VERSION ""

NS_ :

BS_:

BU_: TCM iBooster HCU CIM SCM Right_Hand_Control Left_Hand_Control GPS VCM IC_2 XM GMRS Radio_CANtool Diagnostic_Tool_Digital_Wrench Information_System_Controller_1 STEERING_CONTROLLER VEHICLE_SECURITY RADIO_Hub ABS Battery_Management_Cntrl_2 Battery_Management_Cntrl_1 Auxiliary_Power_Unit_2 Auxiliary_Power_Unit_1 Electric_Propulsion_Cntrl_Unit_4 Electric_Propulsion_Cntrl_Unit_3 Electric_Propulsion_Cntrl_Unit_2 Electric_Propulsion_Cntrl_Unit_1 ECM IC

BO_ 3221225472 VECTOR__INDEPENDENT_SIG_MSG: 0 Vector__XXX
 SG_ pEPS_SAScalibrated : 0|2@1+ (1,0) [0|3] "" Vector__XXX
 SG_ pEPS_OpStatus : 0|3@1+ (1,0) [0|7] "" Vector__XXX
 SG_ pEPS_OpMode : 0|8@1+ (1,0) [0|255] "" Vector__XXX
 SG_ pEPS_ShaftVelocity : 0|16@1+ (0.1,-3276.5) [-3276.5|3276.5] "deg/s" Vector__XXX
 SG_ pEPS_ShaftPosition : 0|16@1+ (0.1,-3276.5) [-3276.5|3276.5] "deg" Vector__XXX
 SG_ DM_SPN2 : 0|8@1+ (1,0) [0|255] "" Vector__XXX
 SG_ DM_SPN3 : 0|3@1+ (1,0) [0|7] "" Vector__XXX
 SG_ DM_SPN1 : 0|8@1+ (1,0) [0|255] "" Vector__XXX
 SG_ DM_FailureModeIdentifier : 0|5@1+ (1,0) [0|0] "" Vector__XXX
 SG_ DM_SPNConversionMethod : 0|1@1+ (1,0) [0|1] "" Vector__XXX
 SG_ DM_OccurenceCount : 0|7@1+ (1,0) [0|126] "" Vector__XXX

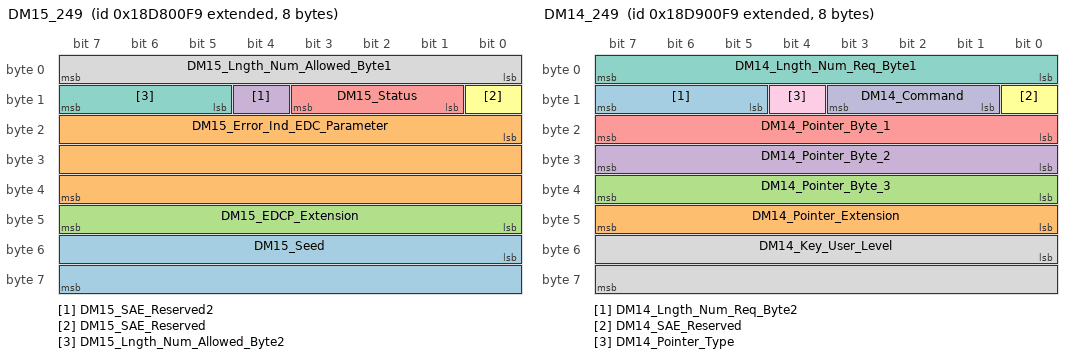
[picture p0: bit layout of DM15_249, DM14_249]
BO_ 2564292857 DM15_249: 8 Diagnostic_Tool_Digital_Wrench
 SG_ DM15_Seed : 48|16@1+ (1,0) [0|65535] "" Vector__XXX
 SG_ DM15_Error_Ind_EDC_Parameter : 16|24@1+ (1,0) [0|16777215] "" Vector__XXX
 SG_ DM15_EDCP_Extension : 40|8@1+ (1,0) [0|255] "" Vector__XXX
 SG_ DM15_SAE_Reserved2 : 12|1@1+ (1,0) [1|1] "" Vector__XXX
 SG_ DM15_Status : 9|3@1+ (1,0) [0|7] "" Vector__XXX
 SG_ DM15_SAE_Reserved : 8|1@1+ (1,0) [1|1] "" Vector__XXX
 SG_ DM15_Lngth_Num_Allowed_Byte2 : 13|3@1+ (1,0) [0|7] "" Vector__XXX
 SG_ DM15_Lngth_Num_Allowed_Byte1 : 0|8@1+ (1,0) [0|255] "" Vector__XXX

BO_ 2564358393 DM14_249: 8 Diagnostic_Tool_Digital_Wrench
 SG_ DM14_Lngth_Num_Req_Byte2 : 13|3@1+ (1,0) [0|7] "" Vector__XXX
 SG_ DM14_Pointer_Extension : 40|8@1+ (1,0) [0|255] "" Vector__XXX
 SG_ DM14_Pointer_Byte_3 : 32|8@1+ (1,0) [0|255] "" Vector__XXX
 SG_ DM14_Pointer_Byte_2 : 24|8@1+ (1,0) [0|255] "" Vector__XXX
 SG_ DM14_Pointer_Byte_1 : 16|8@1+ (1,0) [0|255] "" Vector__XXX
 SG_ DM14_SAE_Reserved : 8|1@1+ (1,0) [1|1] "" Vector__XXX
 SG_ DM14_Lngth_Num_Req_Byte1 : 0|8@1+ (1,0) [0|255] "" Vector__XXX
 SG_ DM14_Key_User_Level : 48|16@1+ (1,0) [0|65535] "" Vector__XXX
 SG_ DM14_Pointer_Type : 12|1@1+ (1,0) [0|1] "" Vector__XXX
 SG_ DM14_Command : 9|3@1+ (1,0) [0|7] "" Vector__XXX

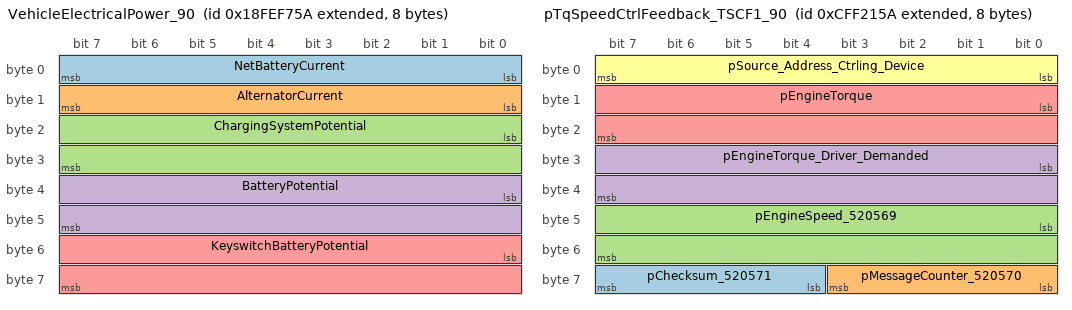
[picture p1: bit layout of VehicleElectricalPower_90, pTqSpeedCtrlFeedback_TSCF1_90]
BO_ 2566846298 VehicleElectricalPower_90: 8 HCU
 SG_ NetBatteryCurrent : 0|8@1+ (1,-125) [-125|125] "A" Vector__XXX
 SG_ AlternatorCurrent : 8|8@1+ (1,0) [0|250] "A" Vector__XXX
 SG_ ChargingSystemPotential : 16|16@1+ (0.05,0) [0|3212.75] "V" Vector__XXX
 SG_ BatteryPotential : 32|16@1+ (0.05,0) [0|3212.75] "V" Vector__XXX
 SG_ KeyswitchBatteryPotential : 48|16@1+ (0.05,0) [0|3212.75] "V" Vector__XXX

BO_ 2633984602 pDriveSystemStatus_90: 8 HCU
 SG_ pHeatedGripEnable : 48|2@1+ (1,0) [0|3] "" Vector__XXX
 SG_ pSideStandStatus : 36|2@1+ (1,0) [0|3] "" Vector__XXX
 SG_ pTetherSwitchStatus : 46|2@1+ (1,0) [0|3] "" Vector__XXX
 SG_ pLowFuelIndicatorStatus : 10|2@1+ (1,0) [0|3] "" Vector__XXX
 SG_ pOperatorNotInOperatingStation : 38|2@1+ (1,0) [0|3] "" Vector__XXX
 SG_ pParkBrakeIndicatorStatus : 40|3@1+ (1,0) [0|7] "" Vector__XXX
 SG_ pADCRequested : 34|2@1+ (1,0) [0|3] "" Vector__XXX
 SG_ pAWDModeRequested : 32|2@1+ (1,0) [0|3] "" Vector__XXX
 SG_ pRWDModeRequested : 30|2@1+ (1,0) [0|3] "" Vector__XXX
 SG_ pTurfModeRequested : 28|2@1+ (1,0) [0|3] "" Vector__XXX
 SG_ pADCStatus : 0|2@1+ (1,0) [0|3] "" Vector__XXX
 SG_ pTreadleNeutralStatus : 2|2@1+ (1,0) [0|3] "" Vector__XXX
 SG_ pTreadleReverseStatus : 4|2@1+ (1,0) [0|3] "" Vector__XXX
 SG_ pSecurityLightStatus : 6|2@1+ (1,0) [0|3] "" Vector__XXX
 SG_ pHighBeamIndicatorStatus : 8|2@1+ (1,0) [0|3] "" Vector__XXX
 SG_ pHeatedGripsPercentage : 16|8@1+ (0.4,0) [0|100] "%" Vector__XXX
 SG_ pCruiseControlSetStatus : 24|2@1+ (1,0) [0|3] "" Vector__XXX
 SG_ pSeatBeltIndicatorStatus : 12|3@1+ (1,0) [0|7] "" Vector__XXX

BO_ 2365530458 pTqSpeedCtrlFeedback_TSCF1_90: 8 HCU
 SG_ pChecksum_520571 : 60|4@1+ (1,0) [0|15] "" Vector__XXX
 SG_ pMessageCounter_520570 : 56|4@1+ (1,0) [0|15] "" Vector__XXX
 SG_ pEngineSpeed_520569 : 40|16@1+ (1,0) [0|64255] "rpm" Vector__XXX
 SG_ pEngineTorque_Driver_Demanded : 24|16@1- (0.03125,0) [-400|1607.96875] "Nm" Vector__XXX
 SG_ pEngineTorque : 8|16@1- (0.03125,0) [-400|1607.96875] "Nm" Vector__XXX
 SG_ pSource_Address_Ctrling_Device : 0|8@1+ (1,0) [0|255] "Source Address" Vector__XXX

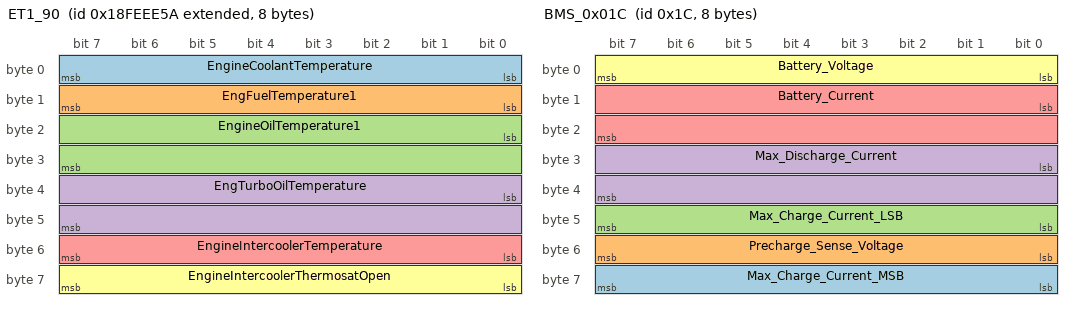
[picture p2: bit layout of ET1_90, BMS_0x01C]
BO_ 2566843994 ET1_90: 8 HCU
 SG_ EngineCoolantTemperature : 0|8@1+ (1,-40) [-40|210] "°C" Vector__XXX
 SG_ EngFuelTemperature1 : 8|8@1+ (1,-40) [-40|210] "°C" Vector__XXX
 SG_ EngineOilTemperature1 : 16|16@1+ (0.03125,-273) [-273|1734.96875] "°C" Vector__XXX
 SG_ EngTurboOilTemperature : 32|16@1+ (0.03125,-273) [-273|1734.96875] "°C" Vector__XXX
 SG_ EngineIntercoolerTemperature : 48|8@1+ (1,-40) [-40|210] "°C" Vector__XXX
 SG_ EngineIntercoolerThermosatOpen : 56|8@1+ (0.4,0) [0|100] "%" Vector__XXX

BO_ 2566841690 EngineHoursRevolutions_90: 8 HCU
 SG_ EngTotalHoursOfOper : 0|32@1+ (0.05,0) [0|210554060.75] "h" Vector__XXX
 SG_ TotalEngineRevolutions : 32|32@1+ (1000,0) [0|4211081215000] "r" Vector__XXX

BO_ 2566876762 pVF1_90: 8 HCU
 SG_ pEngineOilPressureStatus : 4|2@1+ (1,0) [0|3] "" Vector__XXX
 SG_ pHydraulicOilPressureStatus : 2|2@1+ (1,0) [0|3] "" Vector__XXX
 SG_ pHydraulicOilTempStatus : 0|2@1+ (1,0) [0|3] "" Vector__XXX

BO_ 2566876672 pVF1_00: 8 ECM
 SG_ pEngineOilPressureStatus : 4|2@1+ (1,0) [0|3] "" Vector__XXX
 SG_ pHydraulicOilPressureStatus : 2|2@1+ (1,0) [0|3] "" Vector__XXX
 SG_ pHydraulicOilTempStatus : 0|2@1+ (1,0) [0|3] "" Vector__XXX

BO_ 27 BMS_0x01B: 8 Battery_Management_Cntrl_1
 SG_ Battery_Relative_SOC : 0|8@1+ (1,0) [0|0] "%" Vector__XXX
 SG_ BMS_Mode : 8|2@1+ (1,0) [0|0] "1" Vector__XXX

BO_ 28 BMS_0x01C: 8 Battery_Management_Cntrl_1
 SG_ Max_Charge_Current_MSB : 56|8@1+ (1,0) [0|0] "A" Vector__XXX
 SG_ Precharge_Sense_Voltage : 48|8@1+ (1,0) [0|0] "V" Vector__XXX
 SG_ Max_Charge_Current_LSB : 40|8@1+ (1,0) [0|0] "A" Vector__XXX
 SG_ Max_Discharge_Current : 24|16@1+ (1,0) [0|0] "A" Vector__XXX
 SG_ Battery_Current : 8|16@1+ (1,-32768) [0|0] "A" Vector__XXX
 SG_ Battery_Voltage : 0|8@1+ (1,0) [0|0] "V" Vector__XXX

BO_ 2365553933 pRemoteBrakeControl1_13: 8 iBooster
 SG_ Checksum : 56|8@1+ (1,0) [0|255] "Count" Vector__XXX
 SG_ MessageCounter : 52|4@1- (1,0) [-8|7] "Count" Vector__XXX
 SG_ pActualBrakingApplication : 8|8@1+ (0.4,0) [0|100] "%" Vector__XXX
 SG_ pRequestedBrakingApplication : 0|8@1+ (0.4,0) [0|100] "%" Vector__XXX

BO_ 2348941059 TC1_03: 8 TCM
 SG_ TrsmRequestedGear_525 : 16|8@1+ (1,0) [0|0] "" Vector__XXX
 SG_ TrsmGearShiftInhibitReq_681 : 0|2@1+ (1,0) [0|0] "" Vector__XXX

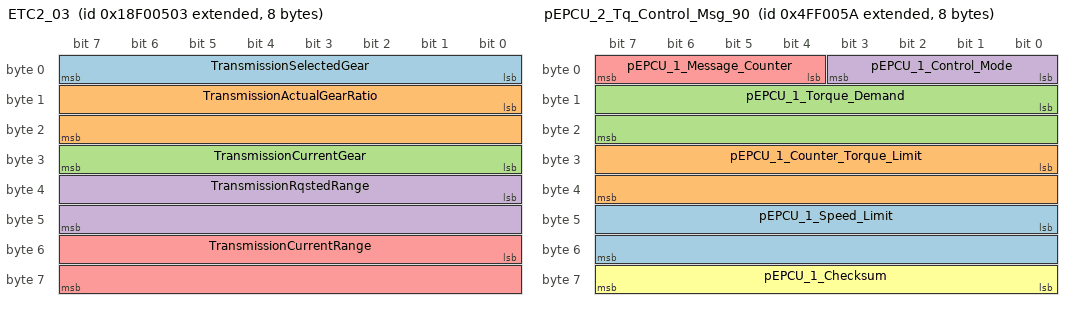
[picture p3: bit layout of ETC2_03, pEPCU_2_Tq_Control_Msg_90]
BO_ 2565866755 ETC2_03: 8 TCM
 SG_ TransmissionSelectedGear : 0|8@1+ (1,-125) [-125|125] "" Vector__XXX
 SG_ TransmissionActualGearRatio : 8|16@1+ (0.001,0) [0|64.255] "" Vector__XXX
 SG_ TransmissionCurrentGear : 24|8@1+ (1,-125) [-125|125] "" Vector__XXX
 SG_ TransmissionRqstedRange : 32|16@1+ (1,0) [0|65535] "" Vector__XXX
 SG_ TransmissionCurrentRange : 48|16@1+ (1,0) [0|65535] "" Vector__XXX

BO_ 2364539395 ElectronicTrsmController1_03: 8 TCM
 SG_ TrsmShiftInProcess_574 : 4|2@1+ (1,0) [0|0] "" Vector__XXX

BO_ 2566844675 CruiseControlVehSpeed_3: 8 TCM
 SG_ pCruiseCntrlCounter : 50|4@1+ (1,0) [0|15] "" Vector__XXX
 SG_ TwoSpeedAxleSwitch : 0|2@1+ (1,0) [0|3] "" Vector__XXX
 SG_ ParkingBrakeSwitch : 2|2@1+ (1,0) [0|3] "" Vector__XXX
 SG_ Wheel_BasedVehicleSpeed : 8|16@1+ (0.00390625,0) [0|251] "km/h" Vector__XXX
 SG_ CruiseCtrlActive : 24|2@1+ (1,0) [0|3] "" Vector__XXX
 SG_ CruiseCtrlEnableSwitch : 26|2@1+ (1,0) [0|3] "" Vector__XXX
 SG_ BrakeSwitch : 28|2@1+ (1,0) [0|3] "" Vector__XXX
 SG_ ClutchSwitch : 30|2@1+ (1,0) [0|3] "" Vector__XXX
 SG_ CruiseCtrlSetSwitch : 32|2@1+ (1,0) [0|3] "" Vector__XXX
 SG_ CruiseCtrlCoastSwitch : 34|2@1+ (1,0) [0|3] "" Vector__XXX
 SG_ CruiseCtrlResumeSwitch : 36|2@1+ (1,0) [0|3] "" Vector__XXX
 SG_ CruiseCtrlAccelerateSwitch : 38|2@1+ (1,0) [0|3] "" Vector__XXX
 SG_ CruiseCtrlSetSpeed : 40|8@1+ (1,0) [0|250] "km/h" Vector__XXX
 SG_ pOdometerDriveBit : 6|2@1+ (1,0) [0|3] "" Vector__XXX
 SG_ CruiseCtrlPauseSw : 4|2@1+ (1,0) [0|3] "" Vector__XXX
 SG_ pCCChecksum : 56|8@1+ (1,0) [0|255] "" Vector__XXX
 SG_ pCruiseEnableStatus : 48|4@1+ (1,0) [0|15] "" Vector__XXX

BO_ 2566841344 SHUTDN_00: 8 ECM
 SG_ Engine_Wait_to_Start_Lamp_1081 : 24|2@1+ (1,0) [0|0] "" Vector__XXX

BO_ 2231304282 pEPCU_2_Tq_Control_Msg_90: 8 HCU
 SG_ pEPCU_1_Speed_Limit : 40|16@1+ (1,-32768) [-32768|31488] "rpm" Vector__XXX
 SG_ pEPCU_1_Counter_Torque_Limit : 24|16@1+ (0.1,-3276.8) [-3276.8|3276.7] "Nm" Vector__XXX
 SG_ pEPCU_1_Torque_Demand : 8|16@1+ (0.1,-3276.8) [-3276.8|3276.7] "Nm" Vector__XXX
 SG_ pEPCU_1_Control_Mode : 0|4@1+ (1,0) [0|15] "" Vector__XXX
 SG_ pEPCU_1_Message_Counter : 4|4@1+ (1,0) [0|15] "" Vector__XXX
 SG_ pEPCU_1_Checksum : 56|8@1+ (1,0) [0|255] "" Vector__XXX

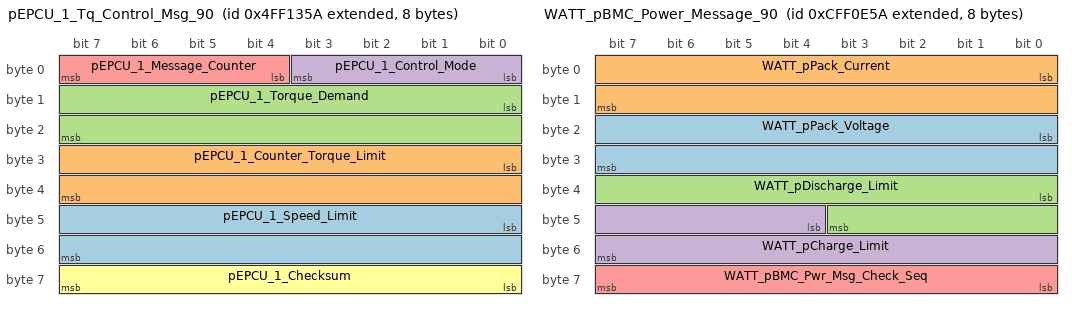
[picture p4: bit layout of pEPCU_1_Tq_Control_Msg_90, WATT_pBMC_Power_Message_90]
BO_ 2231309146 pEPCU_1_Tq_Control_Msg_90: 8 HCU
 SG_ pEPCU_1_Speed_Limit : 40|16@1+ (1,-32768) [-32768|31488] "rpm" Vector__XXX
 SG_ pEPCU_1_Counter_Torque_Limit : 24|16@1+ (0.1,-3276.8) [-3276.8|3276.7] "Nm" Vector__XXX
 SG_ pEPCU_1_Torque_Demand : 8|16@1+ (0.1,-3276.8) [-3276.8|3276.7] "Nm" Vector__XXX
 SG_ pEPCU_1_Control_Mode : 0|4@1+ (1,0) [0|15] "" Vector__XXX
 SG_ pEPCU_1_Message_Counter : 4|4@1+ (1,0) [0|15] "" Vector__XXX
 SG_ pEPCU_1_Checksum : 56|8@1+ (1,0) [0|255] "" Vector__XXX

BO_ 2365525594 WATT_pBMC_Power_Message_90: 8 HCU
 SG_ WATT_pPack_Voltage : 16|16@1+ (0.05,0) [0|3212.75] "V" Vector__XXX
 SG_ WATT_pPack_Current : 0|16@1+ (0.05,-1600) [-1600|1612.75] "A" Vector__XXX
 SG_ WATT_pDischarge_Limit : 32|12@1+ (0.5,0) [0|2007.5] "A" Vector__XXX
 SG_ WATT_pCharge_Limit : 44|12@1+ (0.5,0) [0|2007.5] "A" Vector__XXX
 SG_ WATT_pBMC_Pwr_Msg_Check_Seq : 56|8@1+ (1,0) [0|255] "" Vector__XXX

BO_ 2348941146 TC1_90: 8 HCU
 SG_ TrsmRequestedGear_525 : 16|8@1+ (1,0) [0|0] "" Vector__XXX
 SG_ TrsmGearShiftInhibitReq_681 : 0|2@1+ (1,0) [0|0] "" Vector__XXX

BO_ 2566841434 SHUTDN_90: 8 HCU
 SG_ Engine_Wait_to_Start_Lamp_1081 : 24|2@1+ (1,0) [0|0] "" Vector__XXX

BO_ 2566885722 RF3_RemoteFeedback3_90: 8 HCU
 SG_ pHybridPowertrainMode : 0|4@1+ (1,0) [0|0] "" Vector__XXX

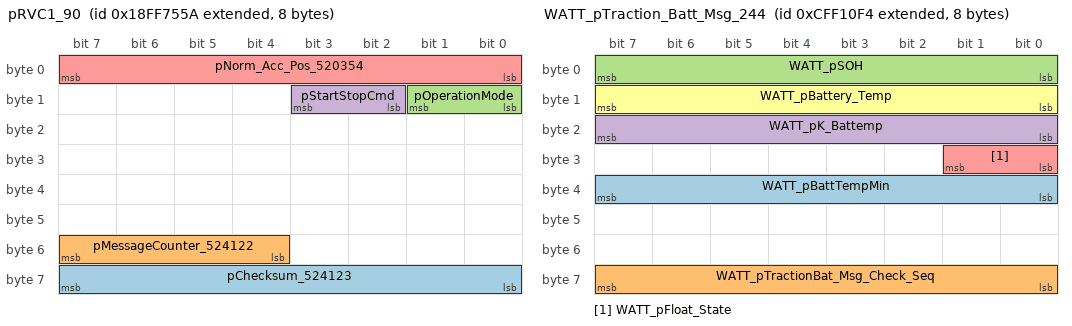
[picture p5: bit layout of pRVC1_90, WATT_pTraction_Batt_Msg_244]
BO_ 2566878554 pRVC1_90: 8 HCU
 SG_ pChecksum_524123 : 56|8@1+ (1,0) [0|255] "" Vector__XXX
 SG_ pMessageCounter_524122 : 52|4@1+ (1,0) [0|15] "" Vector__XXX
 SG_ pOperationMode : 8|2@1+ (1,0) [0|0] "" Vector__XXX
 SG_ pStartStopCmd : 10|2@1+ (1,0) [0|3] "" Vector__XXX
 SG_ pNorm_Acc_Pos_520354 : 0|8@1+ (0.4,0) [0|102] "Percent" Vector__XXX

BO_ 2566844762 CruiseControlVehSpeed_90: 8 HCU
 SG_ TwoSpeedAxleSwitch : 0|2@1+ (1,0) [0|3] "" Vector__XXX
 SG_ ParkingBrakeSwitch : 2|2@1+ (1,0) [0|3] "" Vector__XXX
 SG_ Wheel_BasedVehicleSpeed : 8|16@1+ (0.00390625,0) [0|251] "km/h" Vector__XXX
 SG_ CruiseCtrlActive : 24|2@1+ (1,0) [0|3] "" Vector__XXX
 SG_ CruiseCtrlEnableSwitch : 26|2@1+ (1,0) [0|3] "" Vector__XXX
 SG_ BrakeSwitch : 28|2@1+ (1,0) [0|3] "" Vector__XXX
 SG_ ClutchSwitch : 30|2@1+ (1,0) [0|3] "" Vector__XXX
 SG_ CruiseCtrlSetSwitch : 32|2@1+ (1,0) [0|3] "" Vector__XXX
 SG_ CruiseCtrlCoastSwitch : 34|2@1+ (1,0) [0|3] "" Vector__XXX
 SG_ CruiseCtrlResumeSwitch : 36|2@1+ (1,0) [0|3] "" Vector__XXX
 SG_ CruiseCtrlAccelerateSwitch : 38|2@1+ (1,0) [0|3] "" Vector__XXX
 SG_ CruiseCtrlSetSpeed : 40|8@1+ (1,0) [0|250] "km/h" Vector__XXX
 SG_ pOdometerDriveBit : 6|2@1+ (1,0) [0|3] "" Vector__XXX
 SG_ CruiseCtrlPauseSw : 4|2@1+ (1,0) [0|3] "" Vector__XXX
 SG_ pCCMessageCounter : 52|4@1+ (1,0) [0|15] "" Vector__XXX
 SG_ pCCChecksum : 56|8@1+ (1,0) [0|255] "" Vector__XXX
 SG_ pCruiseEnableStatus : 48|4@1+ (1,0) [0|15] "" Vector__XXX

BO_ 2566887489 pVehicleLoadInfo1_65: 6 Information_System_Controller_1
 SG_ pRiderWeightRearLeft : 32|8@1+ (1,0) [0|250] "kg" Vector__XXX
 SG_ pBoxLoadWeight : 48|8@1+ (10,0) [0|2400] "kg" Vector__XXX
 SG_ pRiderWeightRearRight : 40|8@1+ (1,0) [0|250] "kg" Vector__XXX
 SG_ pRiderWeightMidRight : 24|8@1+ (1,0) [0|250] "kg" Vector__XXX
 SG_ pRiderWeightMidLeft : 16|8@1+ (1,0) [0|250] "kg" Vector__XXX
 SG_ pRiderWeightFrontRight : 8|8@1+ (1,0) [0|250] "kg" Vector__XXX
 SG_ pRiderWeightFrontLeft : 0|8@1+ (1,0) [0|250] "kg" Vector__XXX

BO_ 2566853722 pWattMessage_90: 8 HCU
 SG_ pRangeToEmptyEV : 16|16@1+ (0.1,0) [0|6425.5] "km" Vector__XXX
 SG_ pEfficiencyEV : 0|16@1+ (0.1,0) [0|6425.5] "Wh/km" Vector__XXX

BO_ 2365554060 pRemoteBrakeControl1_140: 8 CIM
 SG_ Checksum : 56|8@1+ (1,0) [0|255] "Count" Vector__XXX
 SG_ MessageCounter : 52|4@1- (1,0) [-8|7] "Count" Vector__XXX
 SG_ pActualBrakingApplication : 8|8@1+ (0.4,0) [0|100] "%" Vector__XXX
 SG_ pRequestedBrakingApplication : 0|8@1+ (0.4,0) [0|100] "%" Vector__XXX

BO_ 2566877965 pRemoteSteeringControl1_13: 8 iBooster
 SG_ pEPS_CommandedVar2 : 48|16@1+ (0.1,-3276.5) [-3276.5|3276.5] "deg/s" Vector__XXX
 SG_ pEPS_CommandedVar1 : 32|16@1+ (0.1,-3276.5) [-3276.5|3276.5] "deg" Vector__XXX
 SG_ pEPS_OpModeCommanded : 0|8@1+ (1,0) [0|255] "" Vector__XXX

BO_ 2365526260 WATT_pTraction_Batt_Msg_244: 8 Battery_Management_Cntrl_2
 SG_ WATT_pBattTempMin : 32|8@1+ (1,-40) [-40|200] "deg C" Vector__XXX
 SG_ WATT_pTractionBat_Msg_Check_Seq : 56|8@1+ (1,0) [0|255] "" Vector__XXX
 SG_ WATT_pSOH : 0|8@1+ (0.5,0) [0|100] "%" Vector__XXX
 SG_ WATT_pK_Battemp : 16|8@1+ (0.5,0) [0|100] "%" Vector__XXX
 SG_ WATT_pFloat_State : 24|2@1+ (1,0) [0|3] "" Vector__XXX
 SG_ WATT_pBattery_Temp : 8|8@1+ (1,-40) [-40|200] "C" Vector__XXX

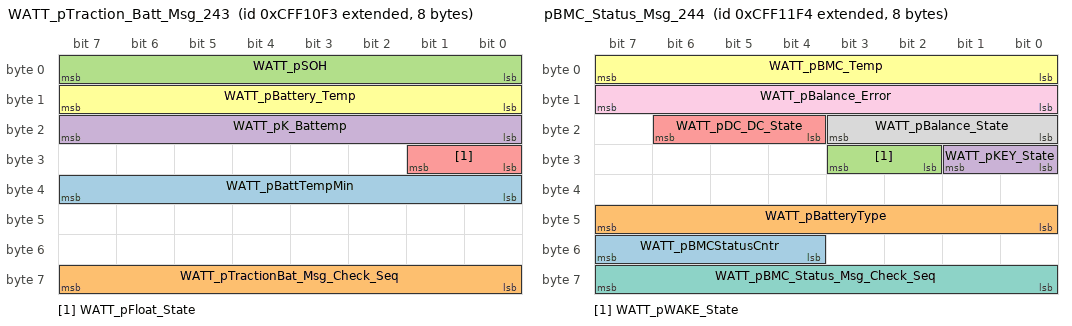
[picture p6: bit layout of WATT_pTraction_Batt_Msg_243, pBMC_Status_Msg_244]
BO_ 2365526259 WATT_pTraction_Batt_Msg_243: 8 Battery_Management_Cntrl_1
 SG_ WATT_pBattTempMin : 32|8@1+ (1,-40) [-40|200] "deg C" Vector__XXX
 SG_ WATT_pTractionBat_Msg_Check_Seq : 56|8@1+ (1,0) [0|255] "" Vector__XXX
 SG_ WATT_pSOH : 0|8@1+ (0.5,0) [0|100] "%" Vector__XXX
 SG_ WATT_pK_Battemp : 16|8@1+ (0.5,0) [0|100] "%" Vector__XXX
 SG_ WATT_pFloat_State : 24|2@1+ (1,0) [0|3] "" Vector__XXX
 SG_ WATT_pBattery_Temp : 8|8@1+ (1,-40) [-40|200] "C" Vector__XXX

BO_ 2365526516 pBMC_Status_Msg_244: 8 Battery_Management_Cntrl_2
 SG_ WATT_pBMCStatusCntr : 52|4@1+ (1,0) [0|15] "" Vector__XXX
 SG_ WATT_pBatteryType : 40|8@1+ (1,0) [0|255] "" Vector__XXX
 SG_ WATT_pWAKE_State : 26|2@1+ (1,0) [0|3] "" Vector__XXX
 SG_ WATT_pKEY_State : 24|2@1+ (1,0) [0|3] "" Vector__XXX
 SG_ WATT_pDC_DC_State : 20|3@1+ (1,0) [0|7] "" Vector__XXX
 SG_ WATT_pBMC_Temp : 0|8@1+ (1,-40) [-40|200] "C" Vector__XXX
 SG_ WATT_pBMC_Status_Msg_Check_Seq : 56|8@1+ (1,0) [0|255] "" Vector__XXX
 SG_ WATT_pBalance_State : 16|4@1+ (1,0) [0|15] "" Vector__XXX
 SG_ WATT_pBalance_Error : 8|8@1+ (0.5,-6.4) [-6.4|6.1] "%" Vector__XXX

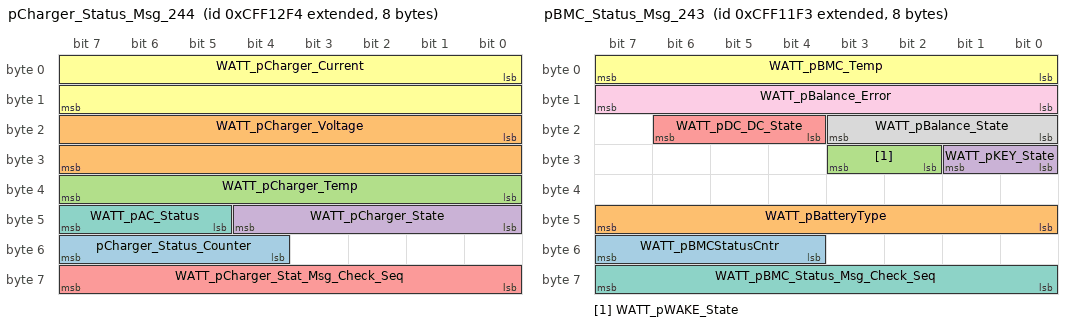
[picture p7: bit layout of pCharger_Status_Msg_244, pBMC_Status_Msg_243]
BO_ 2365526772 pCharger_Status_Msg_244: 8 Battery_Management_Cntrl_2
 SG_ pCharger_Status_Counter : 52|4@1+ (1,0) [0|15] "" Vector__XXX
 SG_ WATT_pCharger_Voltage : 16|16@1+ (0.05,0) [0|3212.75] "V" Vector__XXX
 SG_ WATT_pCharger_Temp : 32|8@1+ (1,-40) [-40|200] "C" Vector__XXX
 SG_ WATT_pCharger_State : 40|5@1+ (1,0) [0|31] "" Vector__XXX
 SG_ WATT_pCharger_Stat_Msg_Check_Seq : 56|8@1+ (1,0) [0|255] "" Vector__XXX
 SG_ WATT_pCharger_Current : 0|16@1+ (0.05,-1600) [-1600|1612.75] "A" Vector__XXX
 SG_ WATT_pAC_Status : 45|3@1+ (1,0) [0|7] "" Vector__XXX

BO_ 2365526004 pEnergy_Msg_244: 8 Battery_Management_Cntrl_2
 SG_ WATT_pWh_In_Since_Key : 24|32@1+ (6.10352E-005,-131072) [-131072|126000] "Wh" Vector__XXX
 SG_ WATT_pSOC : 0|8@1+ (0.5,0) [0|100] "%" Vector__XXX
 SG_ WATT_pEnergy_Msg_Check_Seq : 56|8@1+ (1,0) [0|255] "" Vector__XXX
 SG_ WATT_pAvailable_Wh : 8|16@1+ (4,0) [0|257020] "Wh" Vector__XXX

BO_ 2365526515 pBMC_Status_Msg_243: 8 Battery_Management_Cntrl_1
 SG_ WATT_pBMCStatusCntr : 52|4@1+ (1,0) [0|15] "" Vector__XXX
 SG_ WATT_pBatteryType : 40|8@1+ (1,0) [0|255] "" Vector__XXX
 SG_ WATT_pWAKE_State : 26|2@1+ (1,0) [0|3] "" Vector__XXX
 SG_ WATT_pKEY_State : 24|2@1+ (1,0) [0|3] "" Vector__XXX
 SG_ WATT_pDC_DC_State : 20|3@1+ (1,0) [0|7] "" Vector__XXX
 SG_ WATT_pBMC_Temp : 0|8@1+ (1,-40) [-40|200] "C" Vector__XXX
 SG_ WATT_pBMC_Status_Msg_Check_Seq : 56|8@1+ (1,0) [0|255] "" Vector__XXX
 SG_ WATT_pBalance_State : 16|4@1+ (1,0) [0|15] "" Vector__XXX
 SG_ WATT_pBalance_Error : 8|8@1+ (0.5,-6.4) [-6.4|6.1] "%" Vector__XXX

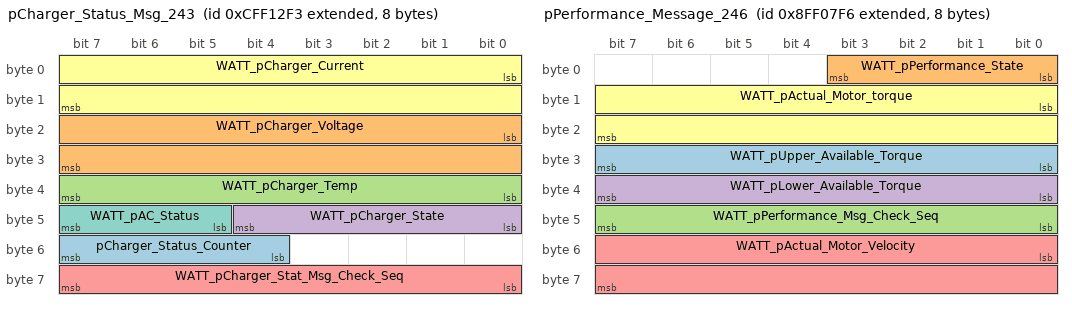
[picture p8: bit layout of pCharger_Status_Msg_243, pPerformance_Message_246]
BO_ 2365526771 pCharger_Status_Msg_243: 8 Battery_Management_Cntrl_1
 SG_ pCharger_Status_Counter : 52|4@1+ (1,0) [0|15] "" Vector__XXX
 SG_ WATT_pCharger_Voltage : 16|16@1+ (0.05,0) [0|3212.75] "V" Vector__XXX
 SG_ WATT_pCharger_Temp : 32|8@1+ (1,-40) [-40|200] "C" Vector__XXX
 SG_ WATT_pCharger_State : 40|5@1+ (1,0) [0|31] "" Vector__XXX
 SG_ WATT_pCharger_Stat_Msg_Check_Seq : 56|8@1+ (1,0) [0|255] "" Vector__XXX
 SG_ WATT_pCharger_Current : 0|16@1+ (0.05,-1600) [-1600|1612.75] "A" Vector__XXX
 SG_ WATT_pAC_Status : 45|3@1+ (1,0) [0|7] "" Vector__XXX

BO_ 2365526003 pEnergy_Msg_243: 8 Battery_Management_Cntrl_1
 SG_ WATT_pWh_In_Since_Key : 24|32@1+ (6.10352E-005,-131072) [-131072|126000] "Wh" Vector__XXX
 SG_ WATT_pSOC : 0|8@1+ (0.5,0) [0|100] "%" Vector__XXX
 SG_ WATT_pEnergy_Msg_Check_Seq : 56|8@1+ (1,0) [0|255] "" Vector__XXX
 SG_ WATT_pAvailable_Wh : 8|16@1+ (4,0) [0|257020] "Wh" Vector__XXX

BO_ 2298415094 pPerformance_Message_246: 8 Auxiliary_Power_Unit_2
 SG_ WATT_pUpper_Available_Torque : 24|8@1+ (2.5,-312.5) [-312.5|312.5] "Nm" Vector__XXX
 SG_ WATT_pPerformance_State : 0|4@1+ (1,0) [0|15] "" Vector__XXX
 SG_ WATT_pPerformance_Msg_Check_Seq : 40|8@1+ (1,0) [0|255] "" Vector__XXX
 SG_ WATT_pLower_Available_Torque : 32|8@1+ (2.5,-312.5) [-312.5|312.5] "Nm" Vector__XXX
 SG_ WATT_pActual_Motor_Velocity : 48|16@1+ (1,-32768) [-32768|31488] "RPM" Vector__XXX
 SG_ WATT_pActual_Motor_torque : 8|16@1+ (0.1,-3276.8) [-3276.8|3148.7] "Nm" Vector__XXX

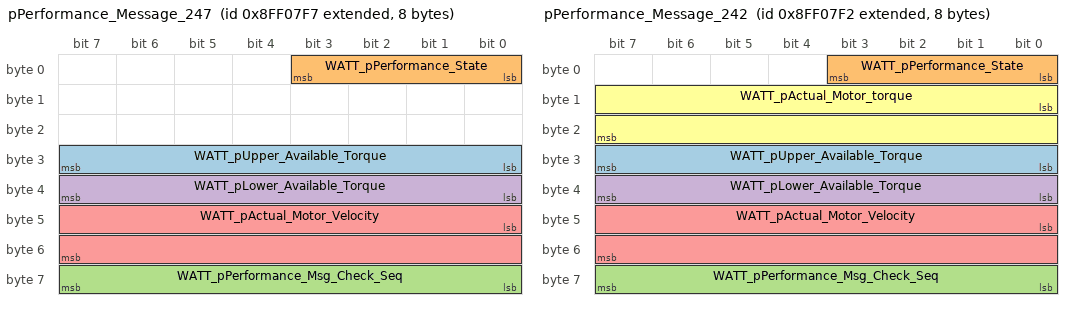
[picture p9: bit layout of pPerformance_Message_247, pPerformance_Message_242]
BO_ 2298415095 pPerformance_Message_247: 8 Auxiliary_Power_Unit_1
 SG_ WATT_pUpper_Available_Torque : 24|8@1+ (2.5,-312.5) [-312.5|312.5] "Nm" Vector__XXX
 SG_ WATT_pPerformance_State : 0|4@1+ (1,0) [0|15] "" Vector__XXX
 SG_ WATT_pPerformance_Msg_Check_Seq : 56|8@1+ (1,0) [0|255] "" Vector__XXX
 SG_ WATT_pLower_Available_Torque : 32|8@1+ (2.5,-312.5) [-312.5|312.5] "Nm" Vector__XXX
 SG_ WATT_pActual_Motor_Velocity : 40|16@1+ (1,-32768) [-32768|31488] "RPM" Vector__XXX

BO_ 2298415090 pPerformance_Message_242: 8 Electric_Propulsion_Cntrl_Unit_4
 SG_ WATT_pUpper_Available_Torque : 24|8@1+ (2.5,-312.5) [-312.5|312.5] "Nm" Vector__XXX
 SG_ WATT_pPerformance_State : 0|4@1+ (1,0) [0|15] "" Vector__XXX
 SG_ WATT_pPerformance_Msg_Check_Seq : 56|8@1+ (1,0) [0|255] "" Vector__XXX
 SG_ WATT_pLower_Available_Torque : 32|8@1+ (2.5,-312.5) [-312.5|312.5] "Nm" Vector__XXX
 SG_ WATT_pActual_Motor_Velocity : 40|16@1+ (1,-32768) [-32768|31488] "RPM" Vector__XXX
 SG_ WATT_pActual_Motor_torque : 8|16@1+ (0.1,-3276.8) [-3276.8|3148.7] "Nm" Vector__XXX

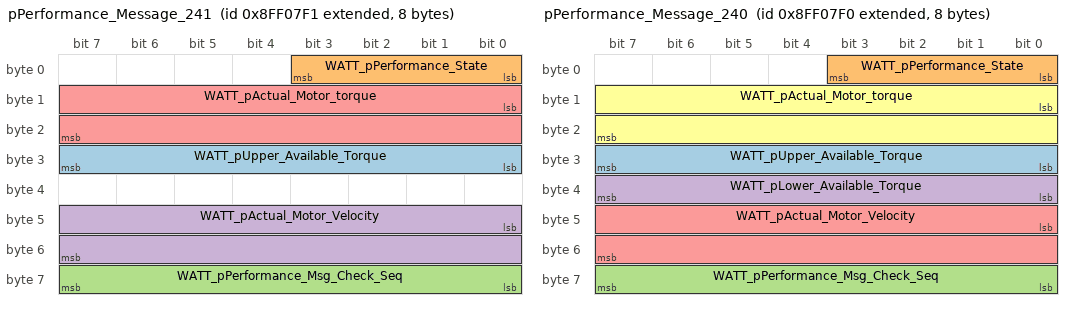
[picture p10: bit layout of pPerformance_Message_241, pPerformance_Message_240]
BO_ 2298415089 pPerformance_Message_241: 8 Electric_Propulsion_Cntrl_Unit_3
 SG_ WATT_pUpper_Available_Torque : 24|8@1+ (2.5,-312.5) [-312.5|312.5] "Nm" Vector__XXX
 SG_ WATT_pPerformance_State : 0|4@1+ (1,0) [0|15] "" Vector__XXX
 SG_ WATT_pPerformance_Msg_Check_Seq : 56|8@1+ (1,0) [0|255] "" Vector__XXX
 SG_ WATT_pActual_Motor_Velocity : 40|16@1+ (1,-32768) [-32768|31488] "RPM" Vector__XXX
 SG_ WATT_pActual_Motor_torque : 8|16@1+ (0.1,-3276.8) [-3276.8|3148.7] "Nm" Vector__XXX

BO_ 2298415088 pPerformance_Message_240: 8 Electric_Propulsion_Cntrl_Unit_2
 SG_ WATT_pUpper_Available_Torque : 24|8@1+ (2.5,-312.5) [-312.5|312.5] "Nm" Vector__XXX
 SG_ WATT_pPerformance_State : 0|4@1+ (1,0) [0|15] "" Vector__XXX
 SG_ WATT_pPerformance_Msg_Check_Seq : 56|8@1+ (1,0) [0|255] "" Vector__XXX
 SG_ WATT_pLower_Available_Torque : 32|8@1+ (2.5,-312.5) [-312.5|312.5] "Nm" Vector__XXX
 SG_ WATT_pActual_Motor_Velocity : 40|16@1+ (1,-32768) [-32768|31488] "RPM" Vector__XXX
 SG_ WATT_pActual_Motor_torque : 8|16@1+ (0.1,-3276.8) [-3276.8|3148.7] "Nm" Vector__XXX

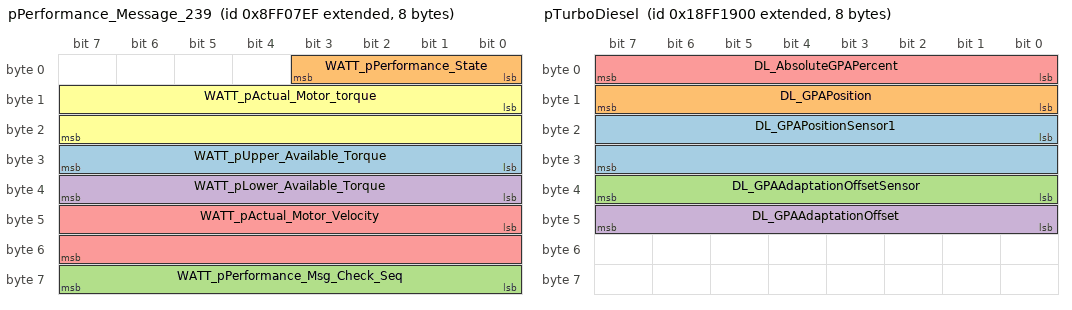
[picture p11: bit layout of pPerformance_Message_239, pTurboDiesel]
BO_ 2298415087 pPerformance_Message_239: 8 Electric_Propulsion_Cntrl_Unit_1
 SG_ WATT_pUpper_Available_Torque : 24|8@1+ (2.5,-312.5) [-312.5|312.5] "Nm" Vector__XXX
 SG_ WATT_pPerformance_State : 0|4@1+ (1,0) [0|15] "" Vector__XXX
 SG_ WATT_pPerformance_Msg_Check_Seq : 56|8@1+ (1,0) [0|255] "" Vector__XXX
 SG_ WATT_pLower_Available_Torque : 32|8@1+ (2.5,-312.5) [-312.5|312.5] "Nm" Vector__XXX
 SG_ WATT_pActual_Motor_Velocity : 40|16@1+ (1,-32768) [-32768|31488] "RPM" Vector__XXX
 SG_ WATT_pActual_Motor_torque : 8|16@1+ (0.1,-3276.8) [-3276.8|3148.7] "Nm" Vector__XXX

BO_ 2566834735 DM1_47: 22 SCM
 SG_ DM_FlashRedStopLamp : 12|2@1+ (1,0) [0|3] "" Vector__XXX
 SG_ DM_FlashProtectLamp : 8|2@1+ (1,0) [0|3] "" Vector__XXX
 SG_ DM_FlashMalfuncIndicatorLamp : 14|2@1+ (1,0) [0|3] "" Vector__XXX
 SG_ DM_FlashAmberWarningLamp : 10|2@1+ (1,0) [0|3] "" Vector__XXX
 SG_ DTC5 : 144|32@1+ (1,0) [0|4294967295] "" Vector__XXX
 SG_ DTC4 : 112|32@1+ (1,0) [0|4294967295] "" Vector__XXX
 SG_ DTC3 : 80|32@1+ (1,0) [0|4294967295] "" Vector__XXX
 SG_ DTC2 : 48|32@1+ (1,0) [0|4294967295] "" Vector__XXX
 SG_ DTC1 : 16|32@1+ (1,0) [0|4294967295] "" Vector__XXX
 SG_ DM_ProtectLampStatus : 0|2@1+ (1,0) [0|3] "" Vector__XXX
 SG_ DM_RedStopLampState : 4|2@1+ (1,0) [0|3] "" Vector__XXX
 SG_ DM_AmberWrningLmpStatus : 2|2@1+ (1,0) [0|3] "" Vector__XXX
 SG_ DM_MalfuncnIndicatorLampStatus : 6|2@1+ (1,0) [0|3] "" Vector__XXX

BO_ 2566903040 DL_DiscreteIO_0: 8 ECM
 SG_ DL_BoostBypassOutputActive : 54|1@1+ (1,0) [0|1] "" Vector__XXX
 SG_ DL_CruiseLampOutputActive : 53|1@1+ (1,0) [0|1] "" Vector__XXX
 SG_ DL_FuelSelectOutput2Active : 52|1@1+ (1,0) [0|1] "" Vector__XXX
 SG_ DL_FuelSelectOutput1Active : 51|1@1+ (1,0) [0|1] "" Vector__XXX
 SG_ DL_OemOutput4Active : 50|1@1+ (1,0) [0|1] "" Vector__XXX
 SG_ DL_OemOutput3Active : 49|1@1+ (1,0) [0|1] "" Vector__XXX
 SG_ DL_OemOutput2Active : 48|1@1+ (1,0) [0|1] "" Vector__XXX
 SG_ DL_OemOutput1Active : 47|1@1+ (1,0) [0|1] "" Vector__XXX
 SG_ DL_FuelPump2RelayOutputActive : 46|1@1+ (1,0) [0|1] "" Vector__XXX
 SG_ DL_IntercoolerOutputActive : 45|1@1+ (1,0) [0|1] "" Vector__XXX
 SG_ DL_ClutchSwitchInputActive : 18|1@1+ (1,0) [0|1] "" Vector__XXX
 SG_ DL_BrakeSwitchInputActive : 17|1@1+ (1,0) [0|1] "" Vector__XXX
 SG_ DL_ReverseSwitchInputActive : 16|1@1+ (1,0) [0|1] "" Vector__XXX
 SG_ DL_CrankReqInput : 0|1@1+ (1,0) [0|1] "" Vector__XXX
 SG_ DL_LowOilLevelInput : 1|1@1+ (1,0) [0|1] "" Vector__XXX
 SG_ DL_LoadAnticipate1Input : 2|1@1+ (1,0) [0|1] "" Vector__XXX
 SG_ DL_LoadAnticipate2Input : 3|1@1+ (1,0) [0|1] "" Vector__XXX
 SG_ DL_CruiseDecelInputActive : 10|1@1+ (1,0) [0|1] "" Vector__XXX
 SG_ DL_CruiseAccelInputActive : 11|1@1+ (1,0) [0|1] "" Vector__XXX
 SG_ DL_PowertrainRelayOutput : 32|1@1+ (1,0) [0|1] "" Vector__XXX
 SG_ DL_StarterRelayOutput : 33|1@1+ (1,0) [0|1] "" Vector__XXX
 SG_ DL_FuelPump1RelayOutput : 44|1@1+ (1,0) [0|1] "" Vector__XXX
 SG_ DL_SlowmodeInputActive : 5|1@1+ (1,0) [0|1] "" Vector__XXX
 SG_ DL_SlowModeLampOutput : 41|1@1+ (1,0) [0|1] "" Vector__XXX
 SG_ DL_GovCruiseSync : 9|1@1+ (1,0) [0|1] "" Vector__XXX
 SG_ DL_DiscreteLowOilPressInput : 7|1@1+ (1,0) [0|0] "" Vector__XXX
 SG_ DL_MILOutput : 34|1@1+ (1,0) [0|1] "" Vector__XXX

BO_ 2566854912 pTurboDiesel: 8 ECM
 SG_ DL_GPAPositionSensor1 : 16|16@1+ (0.001,0) [0|65.535] "Volts" Vector__XXX
 SG_ DL_GPAPosition : 8|8@1+ (0.4,0) [0|102] "%" Vector__XXX
 SG_ DL_GPAAdaptationOffsetSensor : 32|8@1+ (0.02,0) [0|5.1] "Volts" Vector__XXX
 SG_ DL_GPAAdaptationOffset : 40|8@1+ (0.4,0) [0|102] "%" Vector__XXX
 SG_ DL_AbsoluteGPAPercent : 0|8@1+ (0.4,0) [0|102] "%" Vector__XXX

BO_ 2566855680 pFanControl: 8 ECM
 SG_ pRqstdPerFan1DutyCycle : 8|8@1+ (0.4,0) [0|100] "%" Vector__XXX
 SG_ pFan1DirectionCmd : 0|2@1+ (1,0) [0|4] "" Vector__XXX

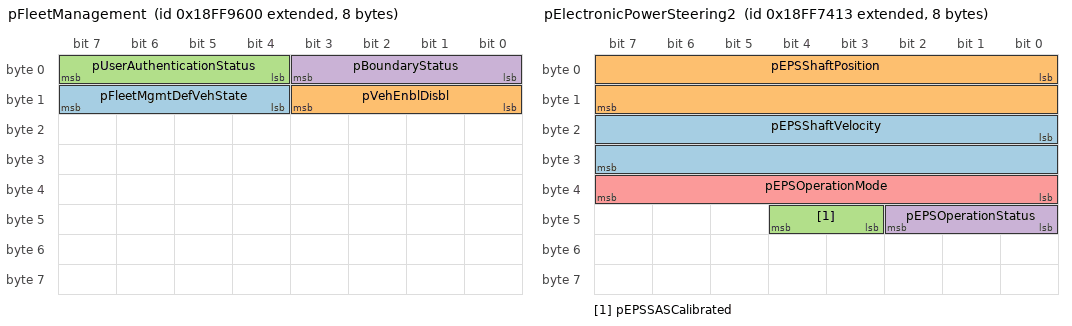
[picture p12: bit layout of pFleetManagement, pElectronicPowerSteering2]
BO_ 2566886912 pFleetManagement: 8 ECM
 SG_ pFleetMgmtDefVehState : 12|4@1+ (1,0) [0|15] "" Vector__XXX
 SG_ pVehEnblDisbl : 8|4@1+ (1,0) [0|15] "" Vector__XXX
 SG_ pUserAuthenticationStatus : 4|4@1+ (1,0) [0|15] "" Vector__XXX
 SG_ pBoundaryStatus : 0|4@1+ (1,0) [0|15] "" Vector__XXX

BO_ 2566886400 LogData: 8 ECM
 SG_ EngineCyldr2IngnitionTmg : 24|8@1+ (1,-128) [-128|122] "deg" Vector__XXX
 SG_ EngineCyldr1IgnitionTmg : 16|8@1+ (1,-128) [-128|122] "deg" Vector__XXX
 SG_ DesiredLambda : 8|8@1+ (0.0078125,0) [0|1.953125] "" Vector__XXX
 SG_ HighRngEngPerLoad : 0|8@1+ (2,0) [0|500] "%" Vector__XXX

BO_ 2566878227 pElectronicPowerSteering2: 8 STEERING_CONTROLLER
 SG_ pEPSShaftVelocity : 16|16@1+ (0.1,-3276.5) [-3276.5|3276.5] "degrees per second" Vector__XXX
 SG_ pEPSShaftPosition : 0|16@1+ (0.1,-3276.5) [-3276.5|3276.5] "degrees" Vector__XXX
 SG_ pEPSSASCalibrated : 43|2@1+ (1,0) [0|3] "" Vector__XXX
 SG_ pEPSOperationStatus : 40|3@1+ (1,0) [0|7] "" Vector__XXX
 SG_ pEPSOperationMode : 32|8@1+ (1,0) [0|255] "" Vector__XXX

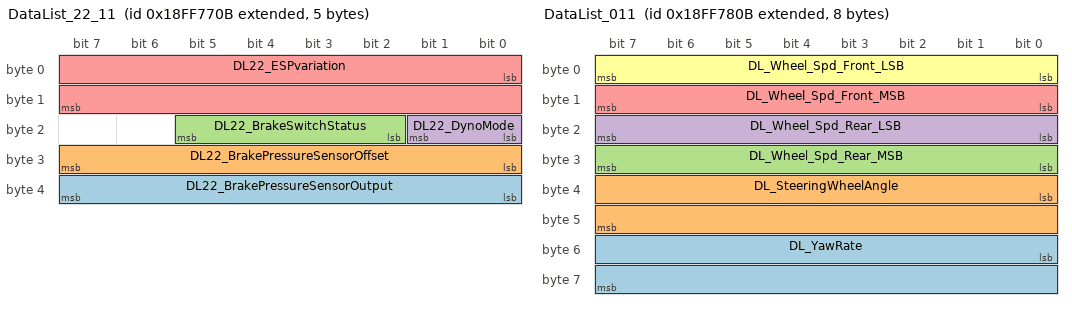
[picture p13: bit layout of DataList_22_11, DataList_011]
BO_ 2566878987 DataList_22_11: 5 ABS
 SG_ DL22_BrakePressureSensorOutput : 32|8@1- (100,5000) [5000|30500] "kPa" Vector__XXX
 SG_ DL22_BrakePressureSensorOffset : 24|8@1+ (100,5000) [5000|30500] "kPa" Vector__XXX
 SG_ DL22_BrakeSwitchStatus : 18|4@1+ (1,0) [0|15] "" Vector__XXX
 SG_ DL22_DynoMode : 16|2@1+ (1,0) [0|3] "Active/Inactive" Vector__XXX
 SG_ DL22_ESPvariation : 0|16@1+ (1,0) [0|255] "Hex" Vector__XXX

BO_ 2365553931 pRemoteBrakeControl1: 8 ABS
 SG_ Checksum : 56|8@1+ (1,0) [0|255] "Count" Vector__XXX
 SG_ MessageCounter : 52|4@1- (1,0) [-8|7] "Count" Vector__XXX
 SG_ pActualBrakingApplication : 8|8@1+ (0.4,0) [0|100] "%" Vector__XXX
 SG_ pRequestedBrakingApplication : 0|8@1+ (0.4,0) [0|100] "%" Vector__XXX

BO_ 2566879243 DataList_011: 8 ABS
 SG_ DL_YawRate : 48|16@1+ (0.0001220703125,-3.92) [-3.92|4.0798779296875] "rad/s" Vector__XXX
 SG_ DL_SteeringWheelAngle : 32|16@1+ (0.0009765625,-31.374) [-31.374|32.6250234375] "rad" Vector__XXX
 SG_ DL_Wheel_Spd_Rear_MSB : 24|8@1+ (0.00390625,0) [0|0.99609375] "kph" Vector__XXX
 SG_ DL_Wheel_Spd_Rear_LSB : 16|8@1+ (0.00390625,0) [0|0.99609375] "kph" Vector__XXX
 SG_ DL_Wheel_Spd_Front_MSB : 8|8@1+ (0.00390625,0) [0|0.99609375] "kph" Vector__XXX
 SG_ DL_Wheel_Spd_Front_LSB : 0|8@1+ (0.00390625,0) [0|0.99609375] "kph" Vector__XXX

BO_ 2566907687 DataList_20_39: 8 VCM
 SG_ DL20_KeyFobBatteryVoltage : 0|8@1+ (0.1,0) [0|25.5] "Volts" Vector__XXX
 SG_ DL20_LeanAngle : 8|8@1+ (1,-125) [-125|130] "Degrees" Vector__XXX

BO_ 2566907943 DataList_19_39: 8 VCM
 SG_ DL19_TirePressure_Rear_Left_Only : 16|8@1+ (4,0) [0|1020] "kPa" Vector__XXX
 SG_ DL19_TirePressureFront_Left_Only : 0|8@1+ (4,0) [0|1020] "kPa" Vector__XXX
 SG_ DL19_TirePressureFrontRight : 8|8@1+ (4,0) [0|1020] "kPa" Vector__XXX
 SG_ DL19_TirePressureRearRight : 24|8@1+ (4,0) [0|1020] "kPa" Vector__XXX

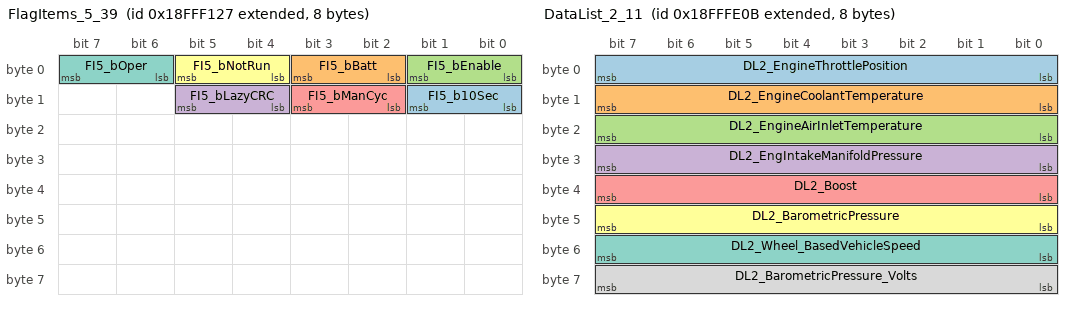
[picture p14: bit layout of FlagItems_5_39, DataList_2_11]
BO_ 2566910247 FlagItems_5_39: 8 VCM
 SG_ FI5_b10Sec : 8|2@1+ (1,0) [0|3] "Binary" Vector__XXX
 SG_ FI5_bBatt : 2|2@1+ (1,0) [0|3] "Binary" Vector__XXX
 SG_ FI5_bEnable : 0|2@1+ (1,0) [0|3] "Binary" Vector__XXX
 SG_ FI5_bLazyCRC : 12|2@1+ (1,0) [0|3] "Binary" Vector__XXX
 SG_ FI5_bManCyc : 10|2@1+ (1,0) [0|3] "Binary" Vector__XXX
 SG_ FI5_bNotRun : 4|2@1+ (1,0) [0|3] "Binary" Vector__XXX
 SG_ FI5_bOper : 6|2@1+ (1,0) [0|3] "Binary" Vector__XXX

BO_ 2566910503 FlagItems_4_39: 8 VCM
 SG_ FI4_SeatbeltSw : 60|2@1+ (1,0) [0|3] "" Vector__XXX
 SG_ FI4_pSideStandSw : 52|2@1+ (1,0) [0|3] "" Vector__XXX
 SG_ FI4_DrvlnMomentaryRight : 58|2@1+ (1,0) [0|3] "" Vector__XXX
 SG_ FI4_DrvlnMomentaryLeft : 56|2@1+ (1,0) [0|3] "" Vector__XXX
 SG_ FI4_BrakeLightOutput : 30|2@1+ (1,0) [0|3] "" Vector__XXX
 SG_ FI4_FogLightInput : 4|2@1+ (1,0) [0|3] "" Vector__XXX
 SG_ FI4_HazardLightOutput : 26|2@1+ (1,0) [0|3] "" Vector__XXX
 SG_ FI4_HazardSWInput : 0|2@1+ (1,0) [0|3] "" Vector__XXX
 SG_ FI4_HeatGripDecSW : 46|2@1+ (1,0) [0|3] "" Vector__XXX
 SG_ FI4_HeatGripIncSW : 44|2@1+ (1,0) [0|3] "" Vector__XXX
 SG_ FI4_HighBeamOutput : 8|2@1+ (1,0) [0|3] "" Vector__XXX
 SG_ FI4_HornInput : 6|2@1+ (1,0) [0|3] "" Vector__XXX
 SG_ FI4_HornOutput : 24|2@1+ (1,0) [0|3] "" Vector__XXX
 SG_ FI4_LeftFogLightOutput : 12|2@1+ (1,0) [0|3] "" Vector__XXX
 SG_ FI4_LFTurnSignalOutput : 32|2@1+ (1,0) [0|3] "" Vector__XXX
 SG_ FI4_LockInput : 18|2@1+ (1,0) [0|3] "" Vector__XXX
 SG_ FI4_LowBeamOutput : 10|2@1+ (1,0) [0|3] "" Vector__XXX
 SG_ FI4_LowHighBeamInput : 2|2@1+ (1,0) [0|3] "" Vector__XXX
 SG_ FI4_LRTurnSignalOutput : 36|2@1+ (1,0) [0|3] "" Vector__XXX
 SG_ FI4_pOperatorButton1 : 48|2@1+ (1,0) [0|3] "" Vector__XXX
 SG_ FI4_RFTurnSignalOutput : 34|2@1+ (1,0) [0|3] "" Vector__XXX
 SG_ FI4_RightFogLightOutput : 14|2@1+ (1,0) [0|3] "" Vector__XXX
 SG_ FI4_RRTurnSignalOutput : 38|2@1+ (1,0) [0|3] "" Vector__XXX
 SG_ FI4_SecondaryAirValveCmd : 42|2@1+ (1,0) [0|3] "" Vector__XXX
 SG_ FI4_SecondaryAirValveOut : 40|2@1+ (1,0) [0|3] "" Vector__XXX
 SG_ FI4_TailLightOutput : 28|2@1+ (1,0) [0|3] "" Vector__XXX
 SG_ FI4_UnlockInput : 16|2@1+ (1,0) [0|3] "" Vector__XXX
 SG_ FI4_WindshieldSWDownInput : 22|2@1+ (1,0) [0|3] "" Vector__XXX
 SG_ FI4_WindshieldSWUpInput : 20|2@1+ (1,0) [0|3] "" Vector__XXX
 SG_ FI4_pOperatorButton2 : 50|2@1+ (1,0) [0|3] "" Vector__XXX

BO_ 2566910759 FlagItems_3_39: 8 VCM
 SG_ FI3_OilPressSwIn : 62|2@1+ (1,0) [0|3] "" Vector__XXX
 SG_ FI3_BrkSw2In : 60|2@1+ (1,0) [0|3] "" Vector__XXX
 SG_ FI3_CruiseCtrlResumeOut : 54|2@1+ (1,0) [0|3] "" Vector__XXX
 SG_ FI3_CruiseCtrlResumeIn : 56|2@1+ (1,0) [0|3] "" Vector__XXX
 SG_ FI3_CruiseCtrlCancelIn : 58|2@1+ (1,0) [0|3] "" Vector__XXX
 SG_ FI3_TetherSwStatus : 38|2@1+ (1,0) [0|3] "" Vector__XXX
 SG_ FI3_DriveMode1Input : 0|2@1+ (1,0) [0|3] "" Vector__XXX
 SG_ FI3_DriveMode2Input : 2|2@1+ (1,0) [0|3] "" Vector__XXX
 SG_ FI3_DriveMode3Input : 4|2@1+ (1,0) [0|3] "" Vector__XXX
 SG_ FI3_DriverMode4Input : 6|2@1+ (1,0) [0|3] "" Vector__XXX
 SG_ FI3_DriverMode1Output : 8|2@1+ (1,0) [0|3] "" Vector__XXX
 SG_ FI3_DriverMode2Output : 10|2@1+ (1,0) [0|3] "" Vector__XXX
 SG_ FI3_DriverMode3Output : 12|2@1+ (1,0) [0|3] "" Vector__XXX
 SG_ FI3_DriverMode4Ouput : 14|2@1+ (1,0) [0|3] "" Vector__XXX
 SG_ FI3_PTOModeInput : 16|2@1+ (1,0) [0|3] "" Vector__XXX
 SG_ FI3_PTOModeOutput : 18|2@1+ (1,0) [0|3] "" Vector__XXX
 SG_ FI3_DriversNetEngagement : 20|2@1+ (1,0) [0|3] "" Vector__XXX
 SG_ FI3_DriversSeatbeltEngagement : 22|2@1+ (1,0) [0|3] "" Vector__XXX
 SG_ FI3_TiltLockInput : 24|2@1+ (1,0) [0|3] "" Vector__XXX
 SG_ FI3_WorkGroupLockInput : 26|2@1+ (1,0) [0|3] "" Vector__XXX
 SG_ FI3_OperatorPresenceInput : 28|2@1+ (1,0) [0|3] "" Vector__XXX
 SG_ FI3_WorkGroupLockOutput : 34|2@1+ (1,0) [0|3] "" Vector__XXX
 SG_ FI3_OperatorPresenceOutput : 36|2@1+ (1,0) [0|3] "" Vector__XXX
 SG_ FI3_FootOnCruiseInput : 40|2@1+ (1,0) [0|3] "" Vector__XXX
 SG_ FI3_CruiseInput : 42|2@1+ (1,0) [0|3] "" Vector__XXX
 SG_ FI3_TredalInput : 44|2@1+ (1,0) [0|3] "" Vector__XXX
 SG_ FI3_CruiseSpeedInput : 46|2@1+ (1,0) [0|3] "" Vector__XXX
 SG_ FI3_FootOnCruiseOutput : 48|2@1+ (1,0) [0|3] "" Vector__XXX
 SG_ FI3_CruiseOutput : 50|2@1+ (1,0) [0|3] "" Vector__XXX
 SG_ FI3_CruiseControltoSetSpeed : 52|2@1+ (1,0) [0|0] "" Vector__XXX
 SG_ FI3_WorkModeInput : 30|2@1+ (1,0) [0|3] "" Vector__XXX
 SG_ FI3_TiltLockOutput : 32|2@1+ (1,0) [0|3] "" Vector__XXX

BO_ 2566911015 FlagItems_2_39: 8 VCM
 SG_ FI2_ThrttlBdyInitLrnValSave : 52|2@1+ (1,0) [0|3] "" Vector__XXX
 SG_ FI2_ThrttlBdyInitLearnSuccess : 54|2@1+ (1,0) [0|3] "" Vector__XXX
 SG_ FI2_ThrottleLimpHomeOpCondition : 46|2@1+ (1,0) [0|3] "" Vector__XXX
 SG_ FI2_SystemOnInput : 42|2@1+ (1,0) [0|3] "" Vector__XXX
 SG_ FI2_SftyFuelCutoffCndn : 56|2@1+ (1,0) [0|3] "" Vector__XXX
 SG_ FI2_RvrsblInjCutoffCndn : 58|2@1+ (1,0) [0|3] "" Vector__XXX
 SG_ FI2_PTOEngagementStatus : 38|2@1+ (1,0) [0|3] "" Vector__XXX
 SG_ FI2_ParkBrakeSwitchIn : 36|2@1+ (1,0) [0|3] "" Vector__XXX
 SG_ FI2_NeutralSwitchIn : 44|2@1+ (1,0) [0|3] "" Vector__XXX
 SG_ FI2_IrrvrsblInjCutoffCndn : 60|2@1+ (1,0) [0|3] "" Vector__XXX
 SG_ FI2_ETCFncnMonitor : 62|2@1+ (1,0) [0|3] "" Vector__XXX
 SG_ FI2_ADCOutput : 0|2@1+ (1,0) [0|3] "" Vector__XXX
 SG_ FI2_RearDiffLockOutput : 2|2@1+ (1,0) [0|3] "" Vector__XXX
 SG_ FI2_AWDOutput : 4|2@1+ (1,0) [0|3] "" Vector__XXX
 SG_ FI2_BrakeSwitchInput : 8|2@1+ (1,0) [0|3] "" Vector__XXX
 SG_ FI2_ADCSwitchInput : 10|2@1+ (1,0) [0|3] "" Vector__XXX
 SG_ FI2_TurfModeInput : 12|2@1+ (1,0) [0|3] "" Vector__XXX
 SG_ FI2_AWDSwitchInput : 14|2@1+ (1,0) [0|3] "" Vector__XXX
 SG_ FI2_ReverseSwitchInput : 16|2@1+ (1,0) [0|3] "" Vector__XXX
 SG_ FI2_ReverseLimitSwitchInput : 18|2@1+ (1,0) [0|3] "" Vector__XXX
 SG_ FI2_ForwardLimitSwitchInput : 20|2@1+ (1,0) [0|3] "" Vector__XXX
 SG_ FI2_EngineDirection : 22|2@1+ (1,0) [0|3] "" Vector__XXX
 SG_ FI2_RevSpeedLimitOverrideInput : 24|2@1+ (1,0) [0|3] "" Vector__XXX
 SG_ FI2_ReverseOverspeedSignal : 26|2@1+ (1,0) [0|3] "" Vector__XXX
 SG_ FI2_RightTurnSignalInput : 32|2@1+ (1,0) [0|3] "" Vector__XXX
 SG_ FI2_LeftTurnSignalInput : 34|2@1+ (1,0) [0|3] "" Vector__XXX
 SG_ FI2_KickstandSwitchInput : 40|2@1+ (1,0) [0|3] "" Vector__XXX
 SG_ FI2_ReflashEnableInputSignal : 48|2@1+ (1,0) [0|3] "" Vector__XXX
 SG_ FI2_TPSLearnInputSignal : 50|2@1+ (1,0) [0|3] "" Vector__XXX
 SG_ FI2_LowRangeSwitchInput : 30|2@1+ (1,0) [0|3] "" Vector__XXX
 SG_ FI2_ReverseMotorDriveInput : 28|2@1+ (1,0) [0|3] "" Vector__XXX

BO_ 2566911271 FlagItems_1_39: 8 VCM
 SG_ FI1_IntercoolerPumpDriverCircuit : 46|2@1+ (1,0) [0|3] "" Vector__XXX
 SG_ FI1_FuelPullSolenoidStatus : 60|2@1+ (1,0) [0|3] "" Vector__XXX
 SG_ FI1_ClutchSwitchInput2 : 62|2@1+ (1,0) [0|3] "" Vector__XXX
 SG_ FI1_FuelPumpDriverCkt : 0|2@1+ (1,0) [0|3] "" Vector__XXX
 SG_ FI1_RolloverSwitch : 2|2@1+ (1,0) [0|3] "" Vector__XXX
 SG_ FI1_CrankSensorSignal : 4|2@1+ (1,0) [0|3] "" Vector__XXX
 SG_ FI1_CamSensorSignal : 6|2@1+ (1,0) [0|3] "" Vector__XXX
 SG_ FI1_RPMLimitActive : 8|2@1+ (1,0) [0|3] "" Vector__XXX
 SG_ FI1_IdleSwitch : 10|2@1+ (1,0) [0|3] "" Vector__XXX
 SG_ FI1_CycleSynchro : 12|2@1+ (1,0) [0|3] "" Vector__XXX
 SG_ FI1_IdleSpeedControlStatus : 14|2@1+ (1,0) [0|3] "" Vector__XXX
 SG_ FI1_IgnitionSwitchInput : 16|2@1+ (1,0) [0|3] "" Vector__XXX
 SG_ FI1_RunStopSwitchInput : 18|2@1+ (1,0) [0|3] "" Vector__XXX
 SG_ FI1_StartSwitchInput : 20|2@1+ (1,0) [0|3] "" Vector__XXX
 SG_ FI1_ThrottleSafetySwInput : 22|2@1+ (1,0) [0|3] "" Vector__XXX
 SG_ FI1_FanRelayOutput : 24|2@1+ (1,0) [0|3] "" Vector__XXX
 SG_ FI1_IntercoolerFanOutput : 26|2@1+ (1,0) [0|3] "" Vector__XXX
 SG_ FI1_ReverseAlarmOutput : 28|2@1+ (1,0) [0|3] "" Vector__XXX
 SG_ FI1_MainRelayOutput : 30|2@1+ (1,0) [0|3] "" Vector__XXX
 SG_ FI1_StartSolenoidOutput : 32|2@1+ (1,0) [0|3] "" Vector__XXX
 SG_ FI1_IgnitionRelayOutput : 34|2@1+ (1,0) [0|3] "" Vector__XXX
 SG_ FI1_ChassisRelayOutput : 36|2@1+ (1,0) [0|3] "" Vector__XXX
 SG_ FI1_StarterEnableOutput : 38|2@1+ (1,0) [0|3] "" Vector__XXX
 SG_ FI1_ExhaustValveOutput : 40|2@1+ (1,0) [0|3] "" Vector__XXX
 SG_ FI1_BatteryChargeRelayOutput : 42|2@1+ (1,0) [0|3] "" Vector__XXX
 SG_ FI1_HeaterAccRelay : 44|2@1+ (1,0) [0|3] "" Vector__XXX
 SG_ FI1_ClutchSwitchInput : 56|2@1+ (1,0) [0|3] "" Vector__XXX
 SG_ FI1_MILLampOutput : 48|2@1+ (1,0) [0|3] "" Vector__XXX
 SG_ FI1_OverTempLampOutput : 50|2@1+ (1,0) [0|3] "" Vector__XXX
 SG_ FI1_KnockDetLampOutput : 52|2@1+ (1,0) [0|3] "" Vector__XXX
 SG_ FI1_ElecOilPumpDrvrCirc : 58|2@1+ (1,0) [0|3] "" Vector__XXX

BO_ 2566913547 DataList_2_11: 8 ABS
 SG_ DL2_EngineThrottlePosition : 0|8@1+ (0.4,0) [0|100] "%" Vector__XXX
 SG_ DL2_EngineCoolantTemperature : 8|8@1+ (1,-40) [-40|210] "°C" Vector__XXX
 SG_ DL2_EngineAirInletTemperature : 16|8@1+ (1,-40) [-40|210] "°C" Vector__XXX
 SG_ DL2_EngIntakeManifoldPressure : 24|8@1+ (2,0) [0|500] "kPa" Vector__XXX
 SG_ DL2_Boost : 32|8@1+ (2,0) [0|500] "kPa" Vector__XXX
 SG_ DL2_BarometricPressure : 40|8@1+ (0.5,0) [0|125] "kPa" Vector__XXX
 SG_ DL2_Wheel_BasedVehicleSpeed : 48|8@1+ (1,0) [0|255] "km/h" Vector__XXX
 SG_ DL2_BarometricPressure_Volts : 56|8@1+ (0.025,0) [0|6.375] "V" Vector__XXX

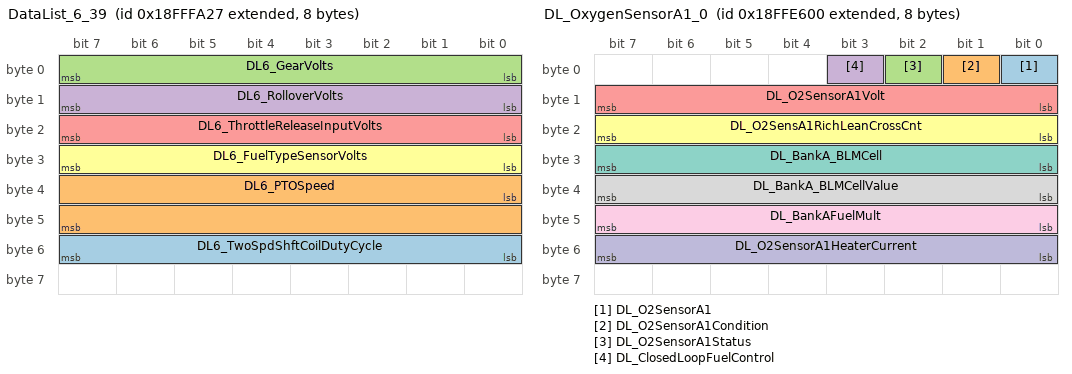
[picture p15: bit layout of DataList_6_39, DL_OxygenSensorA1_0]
BO_ 2566912551 DataList_6_39: 8 VCM
 SG_ DL6_TwoSpdShftCoilDutyCycle : 48|8@1+ (0.4,0) [0|100] "%" Vector__XXX
 SG_ DL6_PTOSpeed : 32|16@1+ (1,0) [0|65535] "RPM" Vector__XXX
 SG_ DL6_GearVolts : 0|8@1+ (0.1,0) [0|25.5] "V" Vector__XXX
 SG_ DL6_RolloverVolts : 8|8@1+ (0.025,0) [0|6.375] "V" Vector__XXX
 SG_ DL6_ThrottleReleaseInputVolts : 16|8@1+ (0.1,0) [0|25.5] "V" Vector__XXX
 SG_ DL6_FuelTypeSensorVolts : 24|8@1+ (0.1,0) [0|25.5] "V" Vector__XXX

BO_ 2566908427 DataList_17_11: 8 ABS
 SG_ DL17_Wheel_Spd_Front_LSB : 0|8@1+ (0.00390625,0) [0|0.99609375] "kph" Vector__XXX
 SG_ DL17_Wheel_Spd_Front_MSB : 8|8@1+ (0.00390625,0) [0|0.99609375] "kph" Vector__XXX
 SG_ DL17_Wheel_Spd_Rear_LSB : 16|8@1+ (0.00390625,0) [0|0.99609375] "kph" Vector__XXX
 SG_ DL17_Wheel_Spd_Rear_MSB : 24|8@1+ (0.00390625,0) [0|0.99609375] "kph" Vector__XXX
 SG_ DL17_ABS_Source_Voltage : 32|8@1+ (0.1,0) [0|25.5] "V" Vector__XXX
 SG_ DL17_ABS_Pump_Command : 40|2@1+ (1,0) [0|3] "" Vector__XXX
 SG_ DL17_Brake_Sw_Status : 42|2@1+ (1,0) [0|3] "" Vector__XXX
 SG_ DL17_ABS_Failsafe_Relay : 44|2@1+ (1,0) [0|3] "" Vector__XXX
 SG_ DL17_ABS_Evac_Fill : 46|2@1+ (1,0) [0|3] "" Vector__XXX
 SG_ DL17_RedBrakeLamp : 48|2@1+ (1,0) [0|3] "" Vector__XXX
 SG_ DL17_ABSFaultLamp : 50|2@1+ (1,0) [0|3] "" Vector__XXX
 SG_ DL17_TCSDisabledLamp : 52|2@1+ (1,0) [0|3] "" Vector__XXX
 SG_ DL17_ESCDisabledLamp : 54|2@1+ (1,0) [0|3] "" Vector__XXX
 SG_ DL17_ESCFaultLampFlashing : 56|2@1+ (1,0) [0|3] "" Vector__XXX
 SG_ DL17_ESCFaultLampSolid : 58|2@1+ (1,0) [0|3] "" Vector__XXX
 SG_ DL17_TorqueRequestedtoECM : 60|2@1+ (1,0) [0|3] "" Vector__XXX
 SG_ DL17_TractionCtrlOverrideSwitch : 62|2@1+ (1,0) [0|0] "" Vector__XXX

BO_ 2566907392 DL_OxygenSensorA1_0: 8 ECM
 SG_ DL_O2SensorA1 : 0|1@1+ (1,0) [0|1] "" Vector__XXX
 SG_ DL_O2SensorA1Condition : 1|1@1+ (1,0) [0|1] "" Vector__XXX
 SG_ DL_O2SensorA1Status : 2|1@1+ (1,0) [0|1] "" Vector__XXX
 SG_ DL_ClosedLoopFuelControl : 3|1@1+ (1,0) [0|1] "" Vector__XXX
 SG_ DL_O2SensorA1Volt : 8|8@1+ (0.009766,0) [0|2.44] "Volts" Vector__XXX
 SG_ DL_O2SensA1RichLeanCrossCnt : 16|8@1+ (1,0) [0|250] "Counts/Sec" Vector__XXX
 SG_ DL_BankA_BLMCell : 24|8@1+ (1,0) [0|250] "Cell ID" Vector__XXX
 SG_ DL_BankA_BLMCellValue : 32|8@1+ (0.007813,0) [0|1.95325] "" Vector__XXX
 SG_ DL_BankAFuelMult : 40|8@1+ (0.0625,0) [0|15.625] "" Vector__XXX
 SG_ DL_O2SensorA1HeaterCurrent : 48|8@1+ (0.0625,0) [0|15.625] "Amps" Vector__XXX

BO_ 2566906880 DL_EnginePedalPositionData_0: 8 ECM
 SG_ DL_PedalPositionSensor1Volt : 0|8@1+ (0.01953,0) [0|4.98015] "Volts" Vector__XXX
 SG_ DL_PedalPositionSensor2Volt : 8|8@1+ (0.01953,0) [0|4.98015] "Volts" Vector__XXX
 SG_ DL_PedalPosition : 16|8@1+ (0.3906,0) [0|100] "%" Vector__XXX

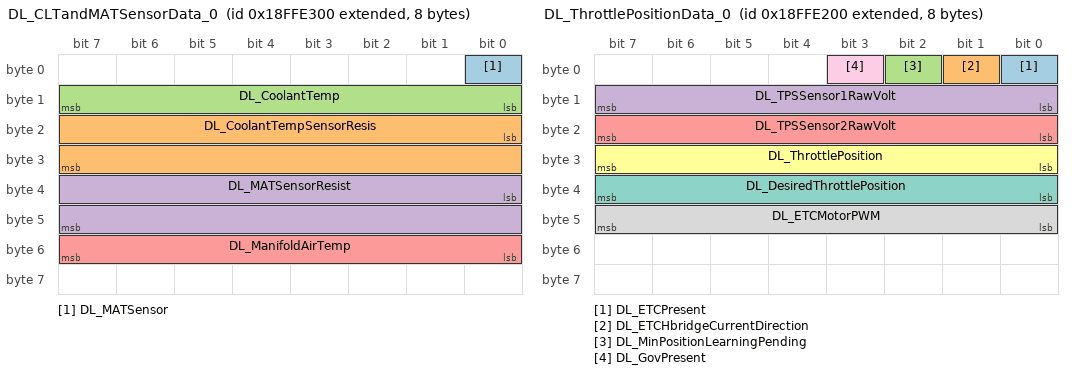
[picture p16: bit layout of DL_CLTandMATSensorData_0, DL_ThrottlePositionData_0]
BO_ 2566906624 DL_CLTandMATSensorData_0: 8 ECM
 SG_ DL_MATSensor : 0|1@1+ (1,0) [0|1] "" Vector__XXX
 SG_ DL_CoolantTempSensorResis : 16|16@1+ (2,0) [0|131060] "Ohms" Vector__XXX
 SG_ DL_CoolantTemp : 8|8@1+ (0.75,-40) [-40|151.25] "°C" Vector__XXX
 SG_ DL_MATSensorResist : 32|16@1+ (2,0) [0|131060] "Ohms" Vector__XXX
 SG_ DL_ManifoldAirTemp : 48|8@1+ (0.75,-40) [-40|151.25] "°C" Vector__XXX

BO_ 2566906368 DL_ThrottlePositionData_0: 8 ECM
 SG_ DL_ETCPresent : 0|1@1+ (1,0) [0|1] "" Vector__XXX
 SG_ DL_ETCHbridgeCurrentDirection : 1|1@1+ (1,0) [0|1] "" Vector__XXX
 SG_ DL_MinPositionLearningPending : 2|1@1+ (1,0) [0|1] "" Vector__XXX
 SG_ DL_TPSSensor1RawVolt : 8|8@1+ (0.01953,0) [0|4.98015] "Volts" Vector__XXX
 SG_ DL_TPSSensor2RawVolt : 16|8@1+ (0.01953,0) [0|4.98015] "Volts" Vector__XXX
 SG_ DL_ThrottlePosition : 24|8@1+ (0.3906,0) [0|100] "%" Vector__XXX
 SG_ DL_DesiredThrottlePosition : 32|8@1+ (0.3906,0) [0|99.603] "%" Vector__XXX
 SG_ DL_ETCMotorPWM : 40|8@1+ (0.3906,0) [0|99.603] "%" Vector__XXX
 SG_ DL_GovPresent : 3|1@1+ (1,0) [0|1] "" Vector__XXX

BO_ 2566906112 DL_MAPSenorData_0: 8 ECM
 SG_ DL_MAPSensorRawVoltage : 0|8@1+ (0.01953,0) [0|4.98015] "Volts" Vector__XXX
 SG_ DL_ManifoldAirPress : 8|16@1+ (0.007813,0) [0|511.99] "kPa" Vector__XXX
 SG_ DL_BarometricPressure : 24|16@1+ (0.007813,0) [0|511.99] "kPa" Vector__XXX
 SG_ DL_BaroSensorPresent : 40|1@1+ (1,0) [0|1] "" Vector__XXX

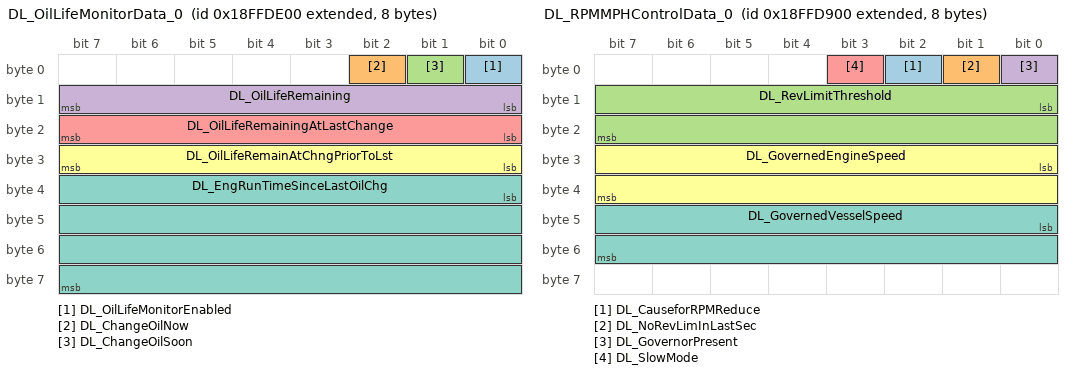
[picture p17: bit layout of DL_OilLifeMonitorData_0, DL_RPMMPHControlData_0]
BO_ 2566905344 DL_OilLifeMonitorData_0: 8 ECM
 SG_ DL_OilLifeMonitorEnabled : 0|1@1+ (1,0) [0|1] "" Vector__XXX
 SG_ DL_ChangeOilNow : 2|1@1+ (1,0) [0|1] "" Vector__XXX
 SG_ DL_ChangeOilSoon : 1|1@1+ (1,0) [0|1] "" Vector__XXX
 SG_ DL_OilLifeRemaining : 8|8@1+ (0.3906,0) [0|100] "%" Vector__XXX
 SG_ DL_OilLifeRemainingAtLastChange : 16|8@1+ (0.3906,0) [0|100] "%" Vector__XXX
 SG_ DL_OilLifeRemainAtChngPriorToLst : 24|8@1+ (0.3906,0) [0|100] "%" Vector__XXX
 SG_ DL_EngRunTimeSinceLastOilChg : 32|32@1+ (1,0) [0|4294967295] "Sec" Vector__XXX

BO_ 2566904064 DL_RPMMPHControlData_0: 8 ECM
 SG_ DL_CauseforRPMReduce : 2|1@1+ (1,0) [0|1] "" Vector__XXX
 SG_ DL_NoRevLimInLastSec : 1|1@1+ (1,0) [0|1] "" Vector__XXX
 SG_ DL_RevLimitThreshold : 8|16@1+ (0.25,0) [0|16382.5] "RPM" Vector__XXX
 SG_ DL_GovernorPresent : 0|1@1+ (1,0) [0|1] "" Vector__XXX
 SG_ DL_SlowMode : 3|1@1+ (1,0) [0|1] "" Vector__XXX
 SG_ DL_GovernedEngineSpeed : 24|16@1+ (0.25,0) [0|16383.75] "rpm" Vector__XXX
 SG_ DL_GovernedVesselSpeed : 40|16@1+ (0.003906,0) [0|255.97971] "mph" Vector__XXX

BO_ 2566903808 DL_CanisterPurgeData_0: 8 ECM
 SG_ DL_CanisterPurgeSystemPresent : 0|1@1+ (1,0) [0|1] "" Vector__XXX
 SG_ DL_CCPDutyCycle : 8|8@1+ (0.3906,0) [0|99.603] "%" Vector__XXX

BO_ 2566903552 DL_EngineDiagHistoryData1_0: 8 ECM
 SG_ DL_FailedDTCTestThisIgnCycle : 0|1@1+ (1,0) [0|1] "" Vector__XXX
 SG_ DL_HistoryDataCorrupted : 1|1@1+ (1,0) [0|1] "" Vector__XXX
 SG_ DL_NumWarmUpCycSinceLastDTCSet : 8|8@1+ (1,0) [0|250] "Cycles" Vector__XXX
 SG_ DL_TotalEngineRunTime : 16|32@1+ (1,0) [0|4294967290] "sec" Vector__XXX

BO_ 2566903296 DL_FanData_0: 8 ECM
 SG_ DL_FanDriver : 4|1@1+ (1,0) [0|1] "" Vector__XXX
 SG_ DL_DesiredFanPosition : 24|8@1+ (0.3906,0) [0|99.603] "%" Vector__XXX
 SG_ DL_FanDutyCycle : 32|8@1+ (0.3906,0) [0|99.603] "%" Vector__XXX

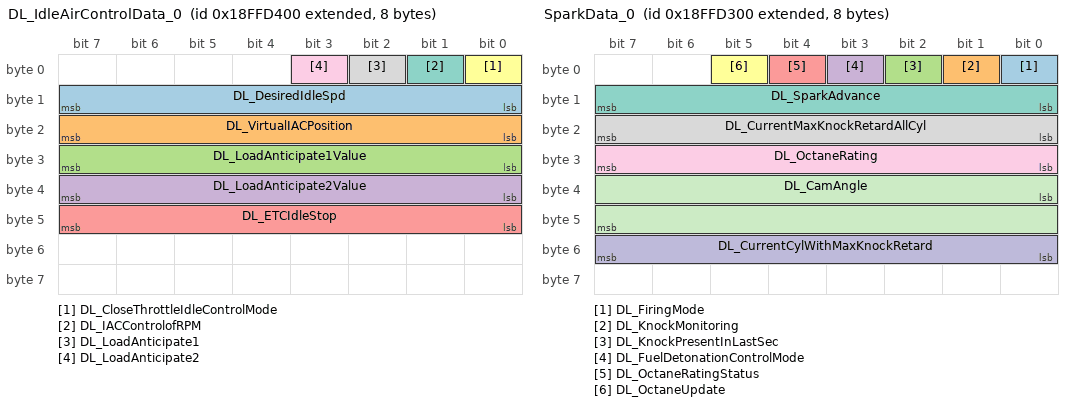
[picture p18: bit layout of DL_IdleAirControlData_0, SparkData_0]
BO_ 2566902784 DL_IdleAirControlData_0: 8 ECM
 SG_ DL_DesiredIdleSpd : 8|8@1+ (8,0) [0|2000] "RPM" Vector__XXX
 SG_ DL_VirtualIACPosition : 16|8@1+ (0.3906,0) [0|99.603] "%" Vector__XXX
 SG_ DL_LoadAnticipate1Value : 24|8@1+ (0.3906,0) [0|99.603] "%" Vector__XXX
 SG_ DL_LoadAnticipate2Value : 32|8@1+ (0.3906,0) [0|99.603] "%" Vector__XXX
 SG_ DL_ETCIdleStop : 40|8@1+ (0.3906,0) [0|99.603] "%" Vector__XXX
 SG_ DL_CloseThrottleIdleControlMode : 0|1@1+ (1,0) [0|1] "" Vector__XXX
 SG_ DL_IACControlofRPM : 1|1@1+ (1,0) [0|1] "" Vector__XXX
 SG_ DL_LoadAnticipate1 : 2|1@1+ (1,0) [0|1] "" Vector__XXX
 SG_ DL_LoadAnticipate2 : 3|1@1+ (1,0) [0|1] "" Vector__XXX

BO_ 2566902528 SparkData_0: 8 ECM
 SG_ DL_FiringMode : 0|1@1+ (1,0) [0|1] "" Vector__XXX
 SG_ DL_KnockMonitoring : 1|1@1+ (1,0) [0|1] "" Vector__XXX
 SG_ DL_KnockPresentInLastSec : 2|1@1+ (1,0) [0|1] "" Vector__XXX
 SG_ DL_FuelDetonationControlMode : 3|1@1+ (1,0) [0|1] "" Vector__XXX
 SG_ DL_OctaneRatingStatus : 4|1@1+ (1,0) [0|1] "" Vector__XXX
 SG_ DL_OctaneUpdate : 5|1@1+ (1,0) [0|1] "" Vector__XXX
 SG_ DL_SparkAdvance : 8|8@1+ (0.3516,-20) [-20|69.658] "Deg" Vector__XXX
 SG_ DL_CurrentMaxKnockRetardAllCyl : 16|8@1+ (0.08789,0) [0|22.41195] "Deg" Vector__XXX
 SG_ DL_OctaneRating : 24|8@1+ (0.3906,0) [0|99.603] "Cnts" Vector__XXX
 SG_ DL_CurrentCylWithMaxKnockRetard : 48|8@1+ (1,0) [0|255] "Cyl#" Vector__XXX
 SG_ DL_CamAngle : 32|16@1+ (1,0) [0|65535] "" Vector__XXX

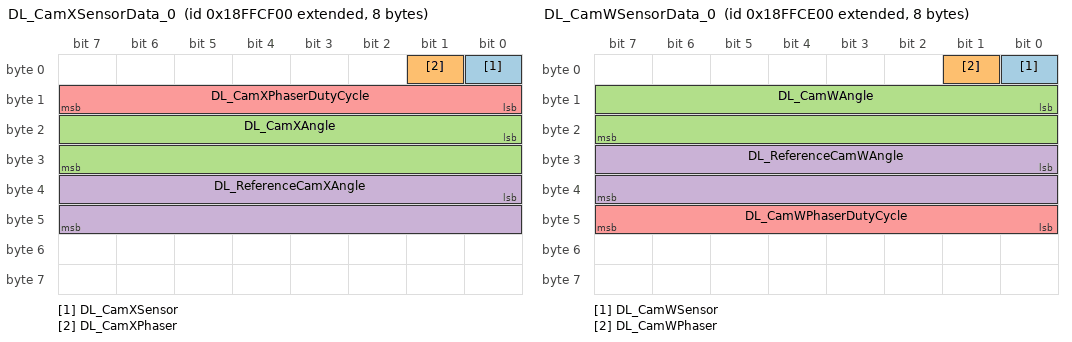
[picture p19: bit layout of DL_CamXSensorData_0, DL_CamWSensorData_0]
BO_ 2566901504 DL_CamXSensorData_0: 8 ECM
 SG_ DL_CamXSensor : 0|1@1+ (1,0) [0|1] "" Vector__XXX
 SG_ DL_CamXPhaser : 1|1@1+ (1,0) [0|1] "" Vector__XXX
 SG_ DL_CamXAngle : 16|16@1+ (0.01563,0) [0|1024.31205] "Deg" Vector__XXX
 SG_ DL_ReferenceCamXAngle : 32|16@1+ (0.01563,0) [0|1024.31205] "Deg" Vector__XXX
 SG_ DL_CamXPhaserDutyCycle : 8|8@1+ (0.3906,0) [0|99.603] "%" Vector__XXX

BO_ 2566901248 DL_CamWSensorData_0: 8 ECM
 SG_ DL_CamWSensor : 0|1@1+ (1,0) [0|1] "" Vector__XXX
 SG_ DL_CamWPhaser : 1|1@1+ (1,0) [0|1] "" Vector__XXX
 SG_ DL_CamWAngle : 8|16@1+ (0.01563,0) [0|1024.31205] "Deg" Vector__XXX
 SG_ DL_ReferenceCamWAngle : 24|16@1+ (0.01563,0) [0|1024.31205] "Deg" Vector__XXX
 SG_ DL_CamWPhaserDutyCycle : 40|8@1+ (0.3906,0) [0|99.603] "%" Vector__XXX

CM_ BU_ iBooster "13 / 0x0D - iBooster";
CM_ BU_ CIM "140 / 0x8C Communications Interface Module";
CM_ BU_ Right_Hand_Control "134-Left Hand Control";
CM_ BU_ Left_Hand_Control "135-Left Hand Control";
CM_ BU_ GPS "28";
CM_ BU_ VCM "39 - Management Computer #1";
CM_ BU_ IC_2 "167 - Instrument Cluster #2";
CM_ BU_ XM "126";
CM_ BU_ GMRS "124";
CM_ BU_ Radio_CANtool "120";
CM_ BU_ Diagnostic_Tool_Digital_Wrench "249 - Diagnostic Tool (Polaris Digital Wrench)";
CM_ BU_ Information_System_Controller_1 "65";
CM_ BU_ STEERING_CONTROLLER "19 - EPAS";
CM_ BU_ VEHICLE_SECURITY "29";
CM_ BU_ RADIO_Hub "127";
CM_ BU_ ABS "11 - Brake Controller";
CM_ BU_ Battery_Management_Cntrl_2 "244 - Li-ion BMC";
CM_ BU_ Battery_Management_Cntrl_1 "243 - Battery Pack Monitor";
CM_ BU_ Auxiliary_Power_Unit_2 "246";
CM_ BU_ Auxiliary_Power_Unit_1 "247";
CM_ BU_ Electric_Propulsion_Cntrl_Unit_4 "242";
CM_ BU_ Electric_Propulsion_Cntrl_Unit_3 "241";
CM_ BU_ Electric_Propulsion_Cntrl_Unit_2 "240";
CM_ BU_ Electric_Propulsion_Cntrl_Unit_1 "239";
CM_ BU_ ECM "0 - Engine #1";
CM_ BU_ IC "23 - Instrument Cluster";
CM_ BO_ 3221225472 "This is a message for not used signals, created by Vector CANdb++ DBC OLE DB Provider.";
CM_ SG_ 3221225472 pEPS_SAScalibrated "EPS Steering Angle Sensor Calibrated
0x00 = Not Calibrated
0x01 = Calibrated
0x10 = Not Available
0x11 = Error";
CM_ SG_ 3221225472 pEPS_OpStatus "EPS Operation Status";
CM_ SG_ 3221225472 pEPS_OpMode "EPS Operation Mode
2 = Standard Operation
5 = Command Operation";
CM_ SG_ 3221225472 pEPS_ShaftVelocity "Steering Shaft Angular Velocity";
CM_ SG_ 3221225472 pEPS_ShaftPosition "Steering Shaft Angular Position";
CM_ SG_ 3221225472 DM_SPN2 "SPN, second byte of SPN";
CM_ SG_ 3221225472 DM_SPN3 "SPN, 3 most significant bits";
CM_ SG_ 3221225472 DM_SPN1 "SPN, 8 lease significant bits";
CM_ SG_ 3221225472 DM_FailureModeIdentifier "The FMI defines the type of failure detected in the subsystem identified by an SPN.";
CM_ SG_ 3221225472 DM_OccurenceCount "The 7 bit occurence count field contains the number of times a fault has gone from active to previously active.";
CM_ BO_ 2564292857 "Memory Access Response / Output State Control";
CM_ BO_ 2564358393 "Memory Access Request / Output State Control";
CM_ BO_ 2566846298 "Vehicle Electrical Power Information";
CM_ SG_ 2566846298 NetBatteryCurrent "Net flow of electrical current into/out of the battery or batteries.";
CM_ SG_ 2566846298 AlternatorCurrent "Measure of electrical current flow from the alternator. Alternator Current (High Range/Resolution) parameter SPN 1795 has a higher range and resolution of the same parameter.";
CM_ SG_ 2566846298 ChargingSystemPotential "Electrical potential measured at the charging system output. The charging system may be any device charging the batteries. This includes alternators, generators, solid state charger,
and other charging devices.";
CM_ SG_ 2566846298 BatteryPotential "This parameter measures the first souce of battery potential as measured at the input of the ECM/actuator etc. coming from one or more batteries, irrespective of the distance between the component
and the battery.";
CM_ SG_ 2566846298 KeyswitchBatteryPotential "Battery potential measured at the input of the electronic control unit supplied through a keyswitch or similar switching device.";
CM_ BO_ 2633984602 "Status of Drive System Information";
CM_ SG_ 2633984602 pHeatedGripEnable "Indicates if the controller broadcasting this SPN is calibrated to support vehicle speed limit 3";
CM_ SG_ 2633984602 pSideStandStatus "Status of the side stand switch of a motorcycle";
CM_ SG_ 2633984602 pTetherSwitchStatus "Status of the Tether Switch";
CM_ SG_ 2633984602 pLowFuelIndicatorStatus "Broadcasting the status of the fuel level for user indication.";
CM_ SG_ 2633984602 pOperatorNotInOperatingStation "Status of Operator presence in a vehicle";
CM_ SG_ 2633984602 pParkBrakeIndicatorStatus "Broadcasting the status of the park brake for user indication";
CM_ SG_ 2633984602 pADCRequested "Broadcasting the status of the users request for ADC mode";
CM_ SG_ 2633984602 pAWDModeRequested "Broadcasting the status of the users request for AWD mode";
CM_ SG_ 2633984602 pRWDModeRequested "Broadcasting the status of the users request for RWD mode";
CM_ SG_ 2633984602 pTurfModeRequested "Broadcasting the status of the users request for TURF mode";
CM_ SG_ 2633984602 pADCStatus "Broadcasting the status of the ADC (active indicates the solenoid is powered)";
CM_ SG_ 2633984602 pTreadleNeutralStatus "Broadcasting the status of the switch indicating the treadle is/is not in the Neutral position";
CM_ SG_ 2633984602 pTreadleReverseStatus "Broadcasting the status of the switch indicating the treadle is/is not in the Reverse position";
CM_ SG_ 2633984602 pSecurityLightStatus "Broadcasting the status of the security system for user indication";
CM_ SG_ 2633984602 pHighBeamIndicatorStatus "Broadcasting the status of the high beam headlight for user indication";
CM_ SG_ 2633984602 pHeatedGripsPercentage "Heated Grips Percent On, 0% is Off and 100% is the maximum heat";
CM_ SG_ 2633984602 pCruiseControlSetStatus "Broadcasting the status of the Cruise Control Set Status for user indication";
CM_ SG_ 2633984602 pSeatBeltIndicatorStatus "Broadcasting the status of the seat belt for user indication";
CM_ BO_ 2365530458 "Feedback from the engine or motor controller to be used in conjunction with making torque/speed requests.  To be used with PGN 65312 and PGN 65314.";
CM_ SG_ 2365530458 pChecksum_520571 "Used to verify the signal path from the transmitting device to the receiving device. The message checksum is calculated using the first 7 data bytes, the message counter and the bytes of the message identifier.";
CM_ SG_ 2365530458 pMessageCounter_520570 "Message counter that increments by one for each transmission from 0 to 15 and then rolls over.
The message counter is used to detect situations where the transmitting ECU malfunction repeats the same frame all the time";
CM_ SG_ 2365530458 pEngineSpeed_520569 "Indication of the current engine or motor speed.";
CM_ SG_ 2365530458 pEngineTorque_Driver_Demanded "Indication of the driver demanded engine or motor output torque.";
CM_ SG_ 2365530458 pEngineTorque "Indication of the actual engine or motor output torque.  Estimated torque is acceptable if actual is not available.";
CM_ SG_ 2365530458 pSource_Address_Ctrling_Device "Indication of the source address of the device from which the torque/speed request is being honored.  If an internal torque request is being honored, the controller will transmit its own source address.";
CM_ BO_ 2566843994 "Engine Temperature 1";
CM_ SG_ 2566843994 EngineCoolantTemperature "Temperature of the liquid in the engine cooling system.";
CM_ SG_ 2566843994 EngFuelTemperature1 "Temperature of fuel (or gass) passing through the first fuel control system. Se SPN 3468 for the second control system.";
CM_ SG_ 2566843994 EngineOilTemperature1 "Temperature of the engine lubricant.";
CM_ SG_ 2566843994 EngTurboOilTemperature "Temperature of the turbocharger lubricant.";
CM_ SG_ 2566843994 EngineIntercoolerTemperature "Not approved for use at Polaris at this time.";
CM_ SG_ 2566843994 EngineIntercoolerThermosatOpen "Not approved for use at Polaris at this time.

(The current position of the thermostat used to regulate the temperature of the engine intercooler.)";
CM_ SG_ 2566841690 EngTotalHoursOfOper "Accumulated time of operation of engine";
CM_ SG_ 2566841690 TotalEngineRevolutions "(Accumulated number of revolutions of engine crankshaft during its operation)";
CM_ BO_ 2566876762 "Vehicle Fluid Information";
CM_ SG_ 2566876762 pEngineOilPressureStatus "Pressure Status of the Engine Oil";
CM_ SG_ 2566876762 pHydraulicOilPressureStatus "Pressure Status of the Hydraulic Oil Pressure";
CM_ SG_ 2566876762 pHydraulicOilTempStatus "Status of the hydraulic oil temperature";
CM_ BO_ 2566876672 "Vehicle Fluid Information";
CM_ SG_ 2566876672 pEngineOilPressureStatus "Pressure Status of the Engine Oil";
CM_ SG_ 2566876672 pHydraulicOilPressureStatus "Pressure Status of the Hydraulic Oil Pressure";
CM_ SG_ 2566876672 pHydraulicOilTempStatus "Status of the hydraulic oil temperature";
CM_ SG_ 2365553933 Checksum "Used to verify the signal path from the transmitting device to the receiving device. The message checksum is 
calculated using the first 7 data bytes, the message counter and the bytes of the message identifier";
CM_ SG_ 2365553933 pActualBrakingApplication "Actual braking application in percent of braking pressure available";
CM_ SG_ 2365553933 pRequestedBrakingApplication "Requested Braking Application in Percent of Breaking Pressure Available";
CM_ BO_ 2565866755 "Electronic Transmission Controller 2";
CM_ SG_ 2565866755 TransmissionSelectedGear "The gear that the transmission will attempt to achieve during the current shift if a shift is in progress,
or the next shift if one is pending";
CM_ SG_ 2565866755 TransmissionActualGearRatio "Actual ratio of input shaft speed to output shaft speed";
CM_ SG_ 2565866755 TransmissionCurrentGear "The gear currently engaged in the transmission or the last gear engaged while the transmission is in
the process of shifting to the new or selected gear";
CM_ SG_ 2565866755 TransmissionRqstedRange "Range selected by the operator.";
CM_ SG_ 2565866755 TransmissionCurrentRange "Range currently being commanded by the transmission control system.";
CM_ BO_ 2566844675 "Cruise Control Status and Vehicle Speed Information";
CM_ SG_ 2566844675 pCruiseCntrlCounter "Rolling Counter (ensures updated message is used).";
CM_ SG_ 2566844675 TwoSpeedAxleSwitch "Switch signal which indicates the current axle range.";
CM_ SG_ 2566844675 ParkingBrakeSwitch "Switch signal which indicates when the parking brake is set. In general the switch actuated by the operator's park brake control,
whether a pedal, lever, or other control mechanism.";
CM_ SG_ 2566844675 Wheel_BasedVehicleSpeed "Speed of the vehicle as calculated from wheel or tailshaft speed.";
CM_ SG_ 2566844675 CruiseCtrlActive "Cruise control is switched on.  It is not ensured that the engine is controlled by cruise control, as in the case of a large driver's demand the engine is controlled by the driver while
cruise control is active.";
CM_ SG_ 2566844675 CruiseCtrlEnableSwitch "Switch signal which indicates that it is possible to manage the cruise control function";
CM_ SG_ 2566844675 BrakeSwitch "Switch signal which indicates that the driver operated brake foot pedal is being pressed";
CM_ SG_ 2566844675 ClutchSwitch "Switch signal which indicates that the clutch pedal is being pressed.  It is necessary for a safe drivetrain behavior that the clutch switch is set before the clutch is opened (cruise control function).";
CM_ SG_ 2566844675 CruiseCtrlSetSwitch "Switch signal of the cruise control activator which indicates that the activator is in the position 'set'.";
CM_ SG_ 2566844675 CruiseCtrlCoastSwitch "Switch signal of the cruise control activator which indicates that the activator is in the position 'coast'";
CM_ SG_ 2566844675 CruiseCtrlResumeSwitch "Switch signal of the cruise control activator which indicates that the activator is in the position 'resume'";
CM_ SG_ 2566844675 CruiseCtrlAccelerateSwitch "Switch signal of the cruise control activator which indicates that the activator is in the position 'accelerate'";
CM_ SG_ 2566844675 CruiseCtrlSetSpeed "Value of set (chosen) velocity of velocity control system.";
CM_ SG_ 2566844675 pOdometerDriveBit "Alternate state (A->B, B->A) each time the vehicle has moved a defined distance (currently 40m).";
CM_ SG_ 2566844675 CruiseCtrlPauseSw "Switch signal which indicates the positon of the Cruise Control Pause Switch used on Remote Cruise Control applications. The Cruise Control Pause Switch signal temporarily
disables the Cruise Control function.";
CM_ SG_ 2566844675 pCCChecksum "XOR of bytes 0-6 (ensures data is valid before use)";
CM_ SG_ 2566844675 pCruiseEnableStatus "The Cruise Control System has been enabled by the operator.  (Amber Light)";
CM_ SG_ 2231304282 pEPCU_1_Speed_Limit "Checksum ensures data is valid before use.";
CM_ SG_ 2231304282 pEPCU_1_Counter_Torque_Limit "Checksum ensures data is valid before use.";
CM_ SG_ 2231304282 pEPCU_1_Torque_Demand "Checksum ensures data is valid before use.";
CM_ SG_ 2231304282 pEPCU_1_Control_Mode "Checksum ensures data is valid before use.";
CM_ SG_ 2231304282 pEPCU_1_Message_Counter "Checksum ensures data is valid before use.";
CM_ SG_ 2231304282 pEPCU_1_Checksum "Checksum ensures data is valid before use.";
CM_ SG_ 2231309146 pEPCU_1_Speed_Limit "Checksum ensures data is valid before use.";
CM_ SG_ 2231309146 pEPCU_1_Counter_Torque_Limit "Checksum ensures data is valid before use.";
CM_ SG_ 2231309146 pEPCU_1_Torque_Demand "Checksum ensures data is valid before use.";
CM_ SG_ 2231309146 pEPCU_1_Control_Mode "Checksum ensures data is valid before use.";
CM_ SG_ 2231309146 pEPCU_1_Message_Counter "Checksum ensures data is valid before use.";
CM_ SG_ 2231309146 pEPCU_1_Checksum "Checksum ensures data is valid before use.";
CM_ BO_ 2365525594 "BMC Power Information";
CM_ SG_ 2365525594 WATT_pPack_Voltage "The voltage of the battery pack monitored by the Battery Management Controller (BMC).";
CM_ SG_ 2365525594 WATT_pPack_Current "The current of the battery pack monitored by the Battery Management Controller (BMC).";
CM_ SG_ 2365525594 WATT_pDischarge_Limit "The discharge limit of the battery pack monitored by the Battery Management Controller (BMC).";
CM_ SG_ 2365525594 WATT_pCharge_Limit "The Charge limit of the battery pack monitored by the Battery Management Controller (BMC).";
CM_ SG_ 2365525594 WATT_pBMC_Pwr_Msg_Check_Seq "Checksum ensures data is valid before use.";
CM_ SG_ 2566878554 pChecksum_524123 "Used to verify the signal path from the transmitting device to the receiving device. The message checksum is calculated using the first 7 data bytes, the message counter and the bytes of the message identifier.";
CM_ SG_ 2566878554 pMessageCounter_524122 "The message counter is used to detect situations where the transmitting ECU malfunction repeats the same frame all the time";
CM_ SG_ 2566878554 pOperationMode "Status of Manned or Remote Vehicle Operation Mode";
CM_ SG_ 2566878554 pStartStopCmd "Commanded Status of the Start Button";
CM_ SG_ 2566878554 pNorm_Acc_Pos_520354 "Indication of the current accelerator pedal position normalized to 0 to 100 %.  Commanded accelerator position as a percent of maximum accelerator position. ";
CM_ BO_ 2566844762 "Cruise Control Status and Vehicle Speed Information";
CM_ SG_ 2566844762 TwoSpeedAxleSwitch "Switch signal which indicates the current axle range.";
CM_ SG_ 2566844762 ParkingBrakeSwitch "Switch signal which indicates when the parking brake is set. In general the switch actuated by the operator's park brake control,
whether a pedal, lever, or other control mechanism.";
CM_ SG_ 2566844762 Wheel_BasedVehicleSpeed "Speed of the vehicle as calculated from wheel or tailshaft speed.";
CM_ SG_ 2566844762 CruiseCtrlActive "Cruise control is switched on.  It is not ensured that the engine is controlled by cruise control, as in the case of a large driver's demand the engine is controlled by the driver while
cruise control is active.";
CM_ SG_ 2566844762 CruiseCtrlEnableSwitch "Switch signal which indicates that it is possible to manage the cruise control function";
CM_ SG_ 2566844762 BrakeSwitch "Switch signal which indicates that the driver operated brake foot pedal is being pressed";
CM_ SG_ 2566844762 ClutchSwitch "Switch signal which indicates that the clutch pedal is being pressed.  It is necessary for a safe drivetrain behavior that the clutch switch is set before the clutch is opened (cruise control function).";
CM_ SG_ 2566844762 CruiseCtrlSetSwitch "Switch signal of the cruise control activator which indicates that the activator is in the position 'set'.";
CM_ SG_ 2566844762 CruiseCtrlCoastSwitch "Switch signal of the cruise control activator which indicates that the activator is in the position 'coast'";
CM_ SG_ 2566844762 CruiseCtrlResumeSwitch "Switch signal of the cruise control activator which indicates that the activator is in the position 'resume'";
CM_ SG_ 2566844762 CruiseCtrlAccelerateSwitch "Switch signal of the cruise control activator which indicates that the activator is in the position 'accelerate'";
CM_ SG_ 2566844762 CruiseCtrlSetSpeed "Value of set (chosen) velocity of velocity control system.";
CM_ SG_ 2566844762 pOdometerDriveBit "Alternate state (A->B, B->A) each time the vehicle has moved a defined distance (currently 40m).";
CM_ SG_ 2566844762 CruiseCtrlPauseSw "Switch signal which indicates the positon of the Cruise Control Pause Switch used on Remote Cruise Control applications. The Cruise Control Pause Switch signal temporarily
disables the Cruise Control function.";
CM_ SG_ 2566844762 pCCMessageCounter "Rolling Counter (ensures updated message is used)";
CM_ SG_ 2566844762 pCCChecksum "XOR of bytes 0-6 (ensures data is valid before use)";
CM_ SG_ 2566844762 pCruiseEnableStatus "The Cruise Control System has been enabled by the operator.  (Amber Light)";
CM_ SG_ 2566887489 pRiderWeightRearLeft "Weight of occupant in rear left seat in kilograms. FE indicates Error. FF indicates data not available.";
CM_ SG_ 2566887489 pBoxLoadWeight "Weight of load in box in kilograms. FE indicates Error. FF indicates data not available.";
CM_ SG_ 2566887489 pRiderWeightRearRight "Weight of occupant in rear right seat in kilograms. FE indicates Error. FF indicates data not available.";
CM_ SG_ 2566887489 pRiderWeightMidRight "Weight of occupant in mid right seat in kilograms. FE indicates Error. FF indicates data not available.";
CM_ SG_ 2566887489 pRiderWeightMidLeft "Weight of occupant in mid left seat in kilograms. FE indicates Error. FF indicates data not available.";
CM_ SG_ 2566887489 pRiderWeightFrontRight "Weight of occupant in front right seat in kilograms. FE indicates Error. FF indicates data not available.";
CM_ SG_ 2566887489 pRiderWeightFrontLeft "Weight of occupant in front left seat in kilograms. FE indicates Error. FF indicates data not available.";
CM_ BO_ 2566853722 "Contains information used on the Watt platform for electrical characteristics of the vehicle.";
CM_ SG_ 2566853722 pRangeToEmptyEV "Calculated range on remaining electrical power";
CM_ SG_ 2566853722 pEfficiencyEV "Calculated efficiency of an electric powertrain vehicle.";
CM_ SG_ 2365554060 Checksum "Used to verify the signal path from the transmitting device to the receiving device. The message checksum is 
calculated using the first 7 data bytes, the message counter and the bytes of the message identifier";
CM_ SG_ 2365554060 pActualBrakingApplication "Actual braking application in percent of braking pressure available";
CM_ SG_ 2365554060 pRequestedBrakingApplication "Requested Braking Application in Percent of Breaking Pressure Available";
CM_ SG_ 2566877965 pEPS_CommandedVar2 "EPS Mode 5: Var2 = Shaft Speed (deg/s)";
CM_ SG_ 2566877965 pEPS_CommandedVar1 "EPS Mode 5 and Mode 16: Var1 = Shaft Position (deg)";
CM_ SG_ 2566877965 pEPS_OpModeCommanded "EPS Mode:
2 - Torque Assist
5 - Command Mode
16 - Set Position";
CM_ BO_ 2365526260 "Traction Battery Information";
CM_ SG_ 2365526260 WATT_pTractionBat_Msg_Check_Seq "Checksum ensures data is valid before use.";
CM_ SG_ 2365526260 WATT_pSOH "The State of Health (SOH) – percent of the battery’s nominal capacity remaining due to aging effects – of the battery pack monitored by the Battery Management Controller (BMC).";
CM_ SG_ 2365526260 WATT_pK_Battemp "The percent of energy capacity at 25°C and current State of Health (SOH) that is available at useful discharge rates at the current battery temperature of the battery pack monitored by the Battery Management Controller (BMC).";
CM_ SG_ 2365526260 WATT_pFloat_State "The status bits indicating the electrolyte level of the battery pack monitored by the Battery Management Controller (BMC).";
CM_ SG_ 2365526260 WATT_pBattery_Temp "The temperature of the battery pack monitored by the Battery Management Controller (BMC).";
CM_ BO_ 2365526259 "Traction Battery Information";
CM_ SG_ 2365526259 WATT_pTractionBat_Msg_Check_Seq "Checksum ensures data is valid before use.";
CM_ SG_ 2365526259 WATT_pSOH "The State of Health (SOH) – percent of the battery’s nominal capacity remaining due to aging effects – of the battery pack monitored by the Battery Management Controller (BMC).";
CM_ SG_ 2365526259 WATT_pK_Battemp "The percent of energy capacity at 25°C and current State of Health (SOH) that is available at useful discharge rates at the current battery temperature of the battery pack monitored by the Battery Management Controller (BMC).";
CM_ SG_ 2365526259 WATT_pFloat_State "The status bits indicating the electrolyte level of the battery pack monitored by the Battery Management Controller (BMC).";
CM_ SG_ 2365526259 WATT_pBattery_Temp "The temperature of the battery pack monitored by the Battery Management Controller (BMC).";
CM_ BO_ 2365526516 "BMC Status Information";
CM_ SG_ 2365526516 WATT_pWAKE_State "The state of the BMC’s WAKE input.";
CM_ SG_ 2365526516 WATT_pKEY_State "State signifying the presence of an activated Key switch.";
CM_ SG_ 2365526516 WATT_pDC_DC_State "Operating state of the DC-DC converter controlled by the Battery Management Controller (BMC).";
CM_ SG_ 2365526516 WATT_pBMC_Temp "The temperature of the Battery Management Controller (BMC).";
CM_ SG_ 2365526516 WATT_pBMC_Status_Msg_Check_Seq "Checksum ensures data is valid before use.";
CM_ SG_ 2365526516 WATT_pBalance_State "The state of the BMC in terms of balancing the state of charge of the bottom battery and the top battery.";
CM_ SG_ 2365526516 WATT_pBalance_Error "The error in state of charge existing between the bottom battery and the top battery balanced by the Battery Management Controller (BMC). Positive error corresponds to the lower battery being at a higher state of charge.";
CM_ BO_ 2365526772 "Battery Charger Status Information";
CM_ SG_ 2365526772 pCharger_Status_Counter "Checksum ensures data is valid before use.";
CM_ SG_ 2365526772 WATT_pCharger_Voltage "The voltage output of the battery charger.";
CM_ SG_ 2365526772 WATT_pCharger_Temp "The temperature of the battery charger.";
CM_ SG_ 2365526772 WATT_pCharger_State "State of the battery charging process.";
CM_ SG_ 2365526772 WATT_pCharger_Stat_Msg_Check_Seq "Checksum ensures data is valid before use.";
CM_ SG_ 2365526772 WATT_pCharger_Current "The output current of the battery charger.";
CM_ SG_ 2365526772 WATT_pAC_Status "State signifying the presence of an AC Supply on the battery charger.";
CM_ BO_ 2365526004 "Vehicle Energy Information";
CM_ SG_ 2365526004 WATT_pWh_In_Since_Key "The capacity in Watt hours delivered to the battery pack monitored by the Battery Management Controller (BMC), negative for net energy removed from the battery pack.";
CM_ SG_ 2365526004 WATT_pSOC "The State of Charge (SOC) – percent of battery capacity available at current battery health and temperature – of the battery pack monitored by the Battery Management Controller (BMC).";
CM_ SG_ 2365526004 WATT_pEnergy_Msg_Check_Seq "Checksum ensures data is valid before use.";
CM_ SG_ 2365526004 WATT_pAvailable_Wh "The capacity, in Watt hours, of the battery pack monitored by the Battery Management Controller (BMC).";
CM_ BO_ 2365526515 "BMC Status Information";
CM_ SG_ 2365526515 WATT_pWAKE_State "The state of the BMC’s WAKE input.";
CM_ SG_ 2365526515 WATT_pKEY_State "State signifying the presence of an activated Key switch.";
CM_ SG_ 2365526515 WATT_pDC_DC_State "Operating state of the DC-DC converter controlled by the Battery Management Controller (BMC).";
CM_ SG_ 2365526515 WATT_pBMC_Temp "The temperature of the Battery Management Controller (BMC).";
CM_ SG_ 2365526515 WATT_pBMC_Status_Msg_Check_Seq "Checksum ensures data is valid before use.";
CM_ SG_ 2365526515 WATT_pBalance_State "The state of the BMC in terms of balancing the state of charge of the bottom battery and the top battery.";
CM_ SG_ 2365526515 WATT_pBalance_Error "The error in state of charge existing between the bottom battery and the top battery balanced by the Battery Management Controller (BMC). Positive error corresponds to the lower battery being at a higher state of charge.";
CM_ BO_ 2365526771 "Battery Charger Status Information";
CM_ SG_ 2365526771 pCharger_Status_Counter "Checksum ensures data is valid before use.";
CM_ SG_ 2365526771 WATT_pCharger_Voltage "The voltage output of the battery charger.";
CM_ SG_ 2365526771 WATT_pCharger_Temp "The temperature of the battery charger.";
CM_ SG_ 2365526771 WATT_pCharger_State "State of the battery charging process.";
CM_ SG_ 2365526771 WATT_pCharger_Stat_Msg_Check_Seq "Checksum ensures data is valid before use.";
CM_ SG_ 2365526771 WATT_pCharger_Current "The output current of the battery charger.";
CM_ SG_ 2365526771 WATT_pAC_Status "State signifying the presence of an AC Supply on the battery charger.";
CM_ BO_ 2365526003 "Vehicle Energy Information";
CM_ SG_ 2365526003 WATT_pWh_In_Since_Key "The capacity in Watt hours delivered to the battery pack monitored by the Battery Management Controller (BMC), negative for net energy removed from the battery pack.";
CM_ SG_ 2365526003 WATT_pSOC "The State of Charge (SOC) – percent of battery capacity available at current battery health and temperature – of the battery pack monitored by the Battery Management Controller (BMC).";
CM_ SG_ 2365526003 WATT_pEnergy_Msg_Check_Seq "Checksum ensures data is valid before use.";
CM_ SG_ 2365526003 WATT_pAvailable_Wh "The capacity, in Watt hours, of the battery pack monitored by the Battery Management Controller (BMC).";
CM_ BO_ 2298415094 "Perfromance Characteristics of the Motor";
CM_ SG_ 2298415094 WATT_pUpper_Available_Torque "The maximum torque available for accelerating in the positive direction. In overspeed conditions the upper available torque may be negative.";
CM_ SG_ 2298415094 WATT_pPerformance_State "Bits dictating the state of the Electric Propulsion Control Unit or Auxiliary Power Unit from which the message is sent.";
CM_ SG_ 2298415094 WATT_pPerformance_Msg_Check_Seq "Checksum ensures data is valid before use.";
CM_ SG_ 2298415094 WATT_pLower_Available_Torque "The maximum torque available in the reverse direction. Lower available torque is normally negative but can be positive in an negative overspeed condition.";
CM_ SG_ 2298415094 WATT_pActual_Motor_Velocity "Actual RPM of the Electric Propulsion Control Unit or Auxiliary Power Unit from which the message is sent.";
CM_ SG_ 2298415094 WATT_pActual_Motor_torque "The actual motor torque output by the Electric Propulsion Control Unit or Auxiliary Power Unit from which the message is sent.";
CM_ BO_ 2298415095 "Perfromance Characteristics of the Motor";
CM_ SG_ 2298415095 WATT_pUpper_Available_Torque "The maximum torque available for accelerating in the positive direction. In overspeed conditions the upper available torque may be negative.";
CM_ SG_ 2298415095 WATT_pPerformance_State "Bits dictating the state of the Electric Propulsion Control Unit or Auxiliary Power Unit from which the message is sent.";
CM_ SG_ 2298415095 WATT_pPerformance_Msg_Check_Seq "Checksum ensures data is valid before use.";
CM_ SG_ 2298415095 WATT_pLower_Available_Torque "The maximum torque available in the reverse direction. Lower available torque is normally negative but can be positive in an negative overspeed condition.";
CM_ SG_ 2298415095 WATT_pActual_Motor_Velocity "Actual RPM of the Electric Propulsion Control Unit or Auxiliary Power Unit from which the message is sent.";
CM_ BO_ 2298415090 "Perfromance Characteristics of the Motor";
CM_ SG_ 2298415090 WATT_pUpper_Available_Torque "The maximum torque available for accelerating in the positive direction. In overspeed conditions the upper available torque may be negative.";
CM_ SG_ 2298415090 WATT_pPerformance_State "Bits dictating the state of the Electric Propulsion Control Unit or Auxiliary Power Unit from which the message is sent.";
CM_ SG_ 2298415090 WATT_pPerformance_Msg_Check_Seq "Checksum ensures data is valid before use.";
CM_ SG_ 2298415090 WATT_pLower_Available_Torque "The maximum torque available in the reverse direction. Lower available torque is normally negative but can be positive in an negative overspeed condition.";
CM_ SG_ 2298415090 WATT_pActual_Motor_Velocity "Actual RPM of the Electric Propulsion Control Unit or Auxiliary Power Unit from which the message is sent.";
CM_ SG_ 2298415090 WATT_pActual_Motor_torque "The actual motor torque output by the Electric Propulsion Control Unit or Auxiliary Power Unit from which the message is sent.";
CM_ BO_ 2298415089 "Perfromance Characteristics of the Motor";
CM_ SG_ 2298415089 WATT_pUpper_Available_Torque "The maximum torque available for accelerating in the positive direction. In overspeed conditions the upper available torque may be negative.";
CM_ SG_ 2298415089 WATT_pPerformance_State "Bits dictating the state of the Electric Propulsion Control Unit or Auxiliary Power Unit from which the message is sent.";
CM_ SG_ 2298415089 WATT_pPerformance_Msg_Check_Seq "Checksum ensures data is valid before use.";
CM_ SG_ 2298415089 WATT_pActual_Motor_Velocity "Actual RPM of the Electric Propulsion Control Unit or Auxiliary Power Unit from which the message is sent.";
CM_ SG_ 2298415089 WATT_pActual_Motor_torque "The actual motor torque output by the Electric Propulsion Control Unit or Auxiliary Power Unit from which the message is sent.";
CM_ BO_ 2298415088 "Perfromance Characteristics of the Motor";
CM_ SG_ 2298415088 WATT_pUpper_Available_Torque "The maximum torque available for accelerating in the positive direction. In overspeed conditions the upper available torque may be negative.";
CM_ SG_ 2298415088 WATT_pPerformance_State "Bits dictating the state of the Electric Propulsion Control Unit or Auxiliary Power Unit from which the message is sent.";
CM_ SG_ 2298415088 WATT_pPerformance_Msg_Check_Seq "Checksum ensures data is valid before use.";
CM_ SG_ 2298415088 WATT_pLower_Available_Torque "The maximum torque available in the reverse direction. Lower available torque is normally negative but can be positive in an negative overspeed condition.";
CM_ SG_ 2298415088 WATT_pActual_Motor_Velocity "Actual RPM of the Electric Propulsion Control Unit or Auxiliary Power Unit from which the message is sent.";
CM_ SG_ 2298415088 WATT_pActual_Motor_torque "The actual motor torque output by the Electric Propulsion Control Unit or Auxiliary Power Unit from which the message is sent.";
CM_ BO_ 2298415087 "Perfromance Characteristics of the Motor";
CM_ SG_ 2298415087 WATT_pUpper_Available_Torque "The maximum torque available for accelerating in the positive direction. In overspeed conditions the upper available torque may be negative.";
CM_ SG_ 2298415087 WATT_pPerformance_State "Bits dictating the state of the Electric Propulsion Control Unit or Auxiliary Power Unit from which the message is sent.";
CM_ SG_ 2298415087 WATT_pPerformance_Msg_Check_Seq "Checksum ensures data is valid before use.";
CM_ SG_ 2298415087 WATT_pLower_Available_Torque "The maximum torque available in the reverse direction. Lower available torque is normally negative but can be positive in an negative overspeed condition.";
CM_ SG_ 2298415087 WATT_pActual_Motor_Velocity "Actual RPM of the Electric Propulsion Control Unit or Auxiliary Power Unit from which the message is sent.";
CM_ SG_ 2298415087 WATT_pActual_Motor_torque "The actual motor torque output by the Electric Propulsion Control Unit or Auxiliary Power Unit from which the message is sent.";
CM_ BO_ 2566834735 "Active diagnostic trouble codes";
CM_ SG_ 2566834735 DM_FlashRedStopLamp "Flash status of the Red Stop Lamp";
CM_ SG_ 2566834735 DM_FlashProtectLamp "Flash status of the Stop Protect Lamp";
CM_ SG_ 2566834735 DM_FlashMalfuncIndicatorLamp "Flash status of the Malfunction Indicator Lamp";
CM_ SG_ 2566834735 DM_FlashAmberWarningLamp "Flash status of the Amber Warning Lamp";
CM_ SG_ 2566834735 DTC5 "Diagnostic Trouble Code";
CM_ SG_ 2566834735 DTC4 "Diagnostic Trouble Code";
CM_ SG_ 2566834735 DTC3 "Diagnostic Trouble Code";
CM_ SG_ 2566834735 DTC2 "Diagnostic Trouble Code";
CM_ SG_ 2566834735 DTC1 "Diagnostic Trouble Code";
CM_ SG_ 2566834735 DM_ProtectLampStatus "This lamp is used to relay trouble code informatio that is reporting a problem with a vehicle system that is most
probably not electronic subsystem related.";
CM_ SG_ 2566834735 DM_RedStopLampState "This lamp is uesed to relay trouble code information that is of a severe enought condition that it warrants stopping the vehicle.";
CM_ SG_ 2566834735 DM_AmberWrningLmpStatus "This lamp is used to relay trouble code information that is reporting a problem with the vehicle system but the vehicle need
not be immediately stopped.";
CM_ SG_ 2566834735 DM_MalfuncnIndicatorLampStatus "A lamp used to relay only emissions-related trouble code information.";
CM_ BO_ 2566855680 "Fan Control";
CM_ SG_ 2566855680 pRqstdPerFan1DutyCycle "Fan duty cycle";
CM_ SG_ 2566855680 pFan1DirectionCmd "Direction command to the Supplemental Fan";
CM_ BO_ 2566886912 "Fleet Management";
CM_ SG_ 2566886912 pFleetMgmtDefVehState "Default state of the vehicle after commanded by Fleet Management device";
CM_ SG_ 2566886912 pVehEnblDisbl "Used to command vehicle states; i.e. vehicle enabled or disabled";
CM_ SG_ 2566886912 pUserAuthenticationStatus "Used to indicate user authentication status";
CM_ SG_ 2566886912 pBoundaryStatus "Used to communicate information about boundary proximity";
CM_ BO_ 2566886400 "Log data";
CM_ SG_ 2566886400 EngineCyldr2IngnitionTmg "Target ignition timing for cylinder 2";
CM_ SG_ 2566886400 EngineCyldr1IgnitionTmg "Target ignition timing for cylinder 1";
CM_ SG_ 2566886400 DesiredLambda "The target lambda value";
CM_ SG_ 2566886400 HighRngEngPerLoad "Percent engine load but with a range high enough to support boosted applications";
CM_ SG_ 2566878227 pEPSShaftVelocity "The rotational velocity of the output shaft of the power steering unit";
CM_ SG_ 2566878227 pEPSShaftPosition "The absolute position of the output shaft of the power steering unit";
CM_ SG_ 2566878227 pEPSSASCalibrated "Indicates the calibration status of the EPS steering angle sensor";
CM_ SG_ 2566878227 pEPSOperationStatus "The operational stutas of the EPS unit";
CM_ SG_ 2566878227 pEPSOperationMode "The mode that the power steering unit is currently functioning in";
CM_ SG_ 2566878987 DL22_BrakeSwitchStatus "0000b – no brake; 0001b – one switch closed/ one open; 0010b – both switches closed ;
 0011b – 1101b : reserved; 1110b –error; 1111b - unavailable";
CM_ SG_ 2365553931 Checksum "Used to verify the signal path from the transmitting device to the receiving device. The message checksum is 
calculated using the first 7 data bytes, the message counter and the bytes of the message identifier";
CM_ SG_ 2365553931 pActualBrakingApplication "Actual braking application in percent of braking pressure available";
CM_ SG_ 2365553931 pRequestedBrakingApplication "Requested Braking Application in Percent of Breaking Pressure Available";
CM_ SG_ 2566879243 DL_YawRate "Rate of rotation about the vertical axis.  Positive raw rate results when the vehicle turns counter-clockwise.";
CM_ SG_ 2566879243 DL_SteeringWheelAngle "The main operator`s steering wheel angle (on the steering column, not the actual wheel angle). The vehicle being
steered to the left (counterclockwise) results in a positive steering wheel angle.";
CM_ SG_ 2566911015 FI2_ReverseMotorDriveInput "Status of the reverse motor switch input; input is high (open circuit) when the selector lever is in the reverse position and low (closed to ground) when the lever is in the forward position.";
CM_ BO_ 2566913547 "ECU Data List 2";
CM_ SG_ 2566913547 DL2_EngineThrottlePosition "The position of the valve used to regulatethe supply of a fluid, usually air or fuel/air mixture, to an engine.";
CM_ SG_ 2566913547 DL2_EngineCoolantTemperature "Temperature of liquid found in engine coolant system.";
CM_ SG_ 2566913547 DL2_EngineAirInletTemperature "Temperature of air entering vehicle air induction system.";
CM_ SG_ 2566913547 DL2_EngIntakeManifoldPressure "Pressure of pre-combustion air found in intake manifold of engine air supply system.";
CM_ SG_ 2566913547 DL2_Boost "Gage pressure of air measured downstream on the compressor discharge side of the turbocharger.";
CM_ SG_ 2566913547 DL2_BarometricPressure "Absolute air pressure of the atmosphere.";
CM_ SG_ 2566913547 DL2_Wheel_BasedVehicleSpeed "Speed of the vehicle as calculated from wheel or tailshaft speed.";
CM_ SG_ 2566913547 DL2_BarometricPressure_Volts "Absolute air pressure of the atmosphere.";
CM_ BO_ 2566912551 "ECU Data List 6";
CM_ BO_ 2566908427 "ECU Data List 17";
CM_ SG_ 2566901504 DL_CamXAngle "Cam-X Angle (from TDCC-A to Cam-X Edge)";
CM_ SG_ 2566901504 DL_ReferenceCamXAngle "Reference Cam-X Angle (from TDCC-A to Cam-X Edge prior to cam phaser activation)";
CM_ SG_ 2566901248 DL_CamWAngle "Cam-W Angle (from TDCC-A to Cam-W Edge)";
CM_ SG_ 2566901248 DL_ReferenceCamWAngle "Reference Cam-W Angle (from TDCC-A to Cam-W Edge prior to cam phaser activation)";
BA_DEF_ SG_  "GenSigSendType" ENUM  "Cyclic","OnWrite","OnWriteWithRepetition","OnChange","OnChangeWithRepetition","IfActive","IfActiveWithRepetition","NoSigSendType";
BA_DEF_ SG_  "GenSigStartValue" INT 0 10000;
BA_DEF_ SG_  "GenSigEVName" STRING ;
BA_DEF_ SG_  "SPN" INT 0 524287;
BA_DEF_ SG_  "SigType" ENUM  "Default","Range","RangeSigned","ASCII","Discrete","Control","ReferencePGN","DTC","StringDelimiter","StringLength","StringLengthControl","MessageCounter","MessageChecksum";
BA_DEF_ SG_  "GenSigILSupport" ENUM  "No","Yes";
BA_DEF_ BO_  "GenMsgCycleTimeFast" INT 0 3600000;
BA_DEF_ BO_  "GenMsgILSupport" ENUM  "No","Yes";
BA_DEF_ BO_  "J1939PGNameSecSrc0Dest3" STRING ;
BA_DEF_ BO_  "J1939PGRelationDest3Src0" INT 0 254;
BA_DEF_ BO_  "J1939PGtoECUSrc0Dest3" INT 0 254;
BA_DEF_ BO_  "J1939PGtoWSMSrc0Dest3" INT 0 254;
BA_DEF_ BO_  "J1939PGRelationSrc0Dest3" INT 0 254;
BA_DEF_ BO_  "J1939PGRepTypeSrc0Dest3" INT 0 4;
BA_DEF_ BO_  "J1939PGRepCycleSrc0Dest3" INT -1 65535;
BA_DEF_ BO_  "J1939PGPrioSrc0Dest3" INT 0 7;
BA_DEF_ BO_  "J1939PGRepetitionType" ENUM  "always","when active","on request";
BA_DEF_ BO_  "J1939PGRepetitionCycle" INT 0 65535;
BA_DEF_ BO_  "J1939PGPrio" INT 0 7;
BA_DEF_ BO_  "VFrameFormat" ENUM  "StandardCAN","ExtendedCAN","reserved","J1939PG";
BA_DEF_ BO_  "GenMsgCycleTime" INT 0 3600000;
BA_DEF_ BO_  "GenMsgRequestable" INT 0 1;
BA_DEF_ BO_  "GenMsgSendType" ENUM  "cyclic","spontaneous","cyclicIfActive","spontaneousWithDelay","cyclicAndSpontaneous","cyclicAndSpontaneousWithDelay","spontaneousWithRepetition","cyclicIfActiveAndSpontaneousWD";
BA_DEF_ BU_  "J1939Ecu0Name" STRING ;
BA_DEF_ BU_  "J1939EcuNr0" INT 0 254;
BA_DEF_ BU_  "J1939Ecu3Name" STRING ;
BA_DEF_ BU_  "J1939EcuNr3" INT 0 254;
BA_DEF_ BU_  "NmStationAddress" INT 0 255;
BA_DEF_ BU_  "NmJ1939AAC" INT 0 1;
BA_DEF_ BU_  "NmJ1939ECUInstance" INT 0 3;
BA_DEF_ BU_  "NmJ1939Function" INT 0 255;
BA_DEF_ BU_  "NmJ1939FunctionInstance" INT 0 7;
BA_DEF_ BU_  "NmJ1939IdentityNumber" INT 0 2097151;
BA_DEF_ BU_  "NmJ1939IndustryGroup" INT 0 7;
BA_DEF_ BU_  "NmJ1939ManufacturerCode" INT 0 2047;
BA_DEF_ BU_  "NmJ1939System" INT 0 127;
BA_DEF_ BU_  "NmJ1939SystemInstance" INT 0 15;
BA_DEF_ BU_  "ECU" STRING ;
BA_DEF_  "Specification" STRING ;
BA_DEF_  "ProtocolType" STRING ;
BA_DEF_  "BusType" STRING ;
BA_DEF_  "DBName" STRING ;
BA_DEF_DEF_  "GenSigSendType" "NoSigSendType";
BA_DEF_DEF_  "GenSigStartValue" 0;
BA_DEF_DEF_  "GenSigEVName" "Env@Nodename_@Signame";
BA_DEF_DEF_  "SPN" 0;
BA_DEF_DEF_  "SigType" "Default";
BA_DEF_DEF_  "GenSigILSupport" "Yes";
BA_DEF_DEF_  "GenMsgCycleTimeFast" 0;
BA_DEF_DEF_  "GenMsgILSupport" "Yes";
BA_DEF_DEF_  "J1939PGNameSecSrc0Dest3" "(null)";
BA_DEF_DEF_  "J1939PGRelationDest3Src0" 254;
BA_DEF_DEF_  "J1939PGtoECUSrc0Dest3" -1;
BA_DEF_DEF_  "J1939PGtoWSMSrc0Dest3" -1;
BA_DEF_DEF_  "J1939PGRelationSrc0Dest3" 254;
BA_DEF_DEF_  "J1939PGRepTypeSrc0Dest3" 3;
BA_DEF_DEF_  "J1939PGRepCycleSrc0Dest3" -1;
BA_DEF_DEF_  "J1939PGPrioSrc0Dest3" 6;
BA_DEF_DEF_  "J1939PGRepetitionType" "always";
BA_DEF_DEF_  "J1939PGRepetitionCycle" 100;
BA_DEF_DEF_  "J1939PGPrio" 6;
BA_DEF_DEF_  "VFrameFormat" "J1939PG";
BA_DEF_DEF_  "GenMsgCycleTime" 0;
BA_DEF_DEF_  "GenMsgRequestable" 1;
BA_DEF_DEF_  "GenMsgSendType" "cyclic";
BA_DEF_DEF_  "J1939Ecu0Name" "(null)";
BA_DEF_DEF_  "J1939EcuNr0" 254;
BA_DEF_DEF_  "J1939Ecu3Name" "(null)";
BA_DEF_DEF_  "J1939EcuNr3" 254;
BA_DEF_DEF_  "NmStationAddress" 254;
BA_DEF_DEF_  "NmJ1939AAC" 0;
BA_DEF_DEF_  "NmJ1939ECUInstance" 0;
BA_DEF_DEF_  "NmJ1939Function" 0;
BA_DEF_DEF_  "NmJ1939FunctionInstance" 0;
BA_DEF_DEF_  "NmJ1939IdentityNumber" 0;
BA_DEF_DEF_  "NmJ1939IndustryGroup" 0;
BA_DEF_DEF_  "NmJ1939ManufacturerCode" 0;
BA_DEF_DEF_  "NmJ1939System" 0;
BA_DEF_DEF_  "NmJ1939SystemInstance" 0;
BA_DEF_DEF_  "ECU" "";
BA_DEF_DEF_  "Specification" "";
BA_DEF_DEF_  "ProtocolType" "J1939";
BA_DEF_DEF_  "BusType" "CAN";
BA_DEF_DEF_  "DBName" "";
BA_ "Specification" "SAE J1939-71 Revised 08-2002 and SAE J1939-73 OCT1998";
BA_ "DBName" "Polaris_j1939";
BA_ "NmStationAddress" BU_ TCM 3;
BA_ "NmStationAddress" BU_ iBooster 13;
BA_ "NmStationAddress" BU_ HCU 90;
BA_ "NmStationAddress" BU_ CIM 140;
BA_ "NmStationAddress" BU_ SCM 47;
BA_ "NmStationAddress" BU_ Right_Hand_Control 134;
BA_ "NmStationAddress" BU_ Left_Hand_Control 135;
BA_ "NmStationAddress" BU_ GPS 28;
BA_ "NmStationAddress" BU_ VCM 39;
BA_ "NmStationAddress" BU_ IC_2 167;
BA_ "NmStationAddress" BU_ XM 126;
BA_ "NmStationAddress" BU_ GMRS 124;
BA_ "NmStationAddress" BU_ Radio_CANtool 120;
BA_ "NmStationAddress" BU_ Diagnostic_Tool_Digital_Wrench 249;
BA_ "NmStationAddress" BU_ Information_System_Controller_1 65;
BA_ "NmStationAddress" BU_ STEERING_CONTROLLER 19;
BA_ "NmStationAddress" BU_ VEHICLE_SECURITY 29;
BA_ "NmStationAddress" BU_ RADIO_Hub 127;
BA_ "NmStationAddress" BU_ ABS 11;
BA_ "NmStationAddress" BU_ Battery_Management_Cntrl_2 244;
BA_ "NmStationAddress" BU_ Battery_Management_Cntrl_1 243;
BA_ "NmStationAddress" BU_ Auxiliary_Power_Unit_2 246;
BA_ "NmStationAddress" BU_ Auxiliary_Power_Unit_1 247;
BA_ "NmStationAddress" BU_ Electric_Propulsion_Cntrl_Unit_4 242;
BA_ "NmStationAddress" BU_ Electric_Propulsion_Cntrl_Unit_3 241;
BA_ "NmStationAddress" BU_ Electric_Propulsion_Cntrl_Unit_2 240;
BA_ "NmStationAddress" BU_ Electric_Propulsion_Cntrl_Unit_1 239;
BA_ "NmStationAddress" BU_ ECM 0;
BA_ "NmJ1939ManufacturerCode" BU_ ECM 100;
BA_ "ECU" BU_ ECM "ECM";
BA_ "NmStationAddress" BU_ IC 23;
BA_ "NmJ1939Function" BU_ IC 19;
BA_ "NmJ1939ManufacturerCode" BU_ IC 102;
BA_ "ECU" BU_ IC "DISPLAY";
BA_ "GenMsgCycleTime" BO_ 2564292857 100;
BA_ "GenMsgCycleTime" BO_ 2564358393 100;
BA_ "GenMsgCycleTime" BO_ 2566846298 1000;
BA_ "GenMsgCycleTime" BO_ 2633984602 100;
BA_ "GenMsgCycleTime" BO_ 2365530458 10;
BA_ "GenMsgCycleTime" BO_ 2566843994 1000;
BA_ "GenMsgCycleTime" BO_ 2566841690 100;
BA_ "GenMsgCycleTime" BO_ 2566876762 1000;
BA_ "GenMsgCycleTime" BO_ 2566876672 1000;
BA_ "VFrameFormat" BO_ 27 0;
BA_ "VFrameFormat" BO_ 28 0;
BA_ "GenMsgCycleTime" BO_ 2565866755 100;
BA_ "GenMsgCycleTime" BO_ 2566844675 100;
BA_ "GenMsgSendType" BO_ 2566844675 4.90833586961908E-316;
BA_ "GenMsgCycleTime" BO_ 2231304282 5000;
BA_ "GenMsgSendType" BO_ 2231304282 4;
BA_ "GenMsgCycleTime" BO_ 2231309146 5000;
BA_ "GenMsgSendType" BO_ 2231309146 4;
BA_ "GenMsgCycleTime" BO_ 2365525594 10;
BA_ "GenMsgCycleTimeFast" BO_ 2566878554 10;
BA_ "GenMsgCycleTime" BO_ 2566878554 200;
BA_ "GenMsgSendType" BO_ 2566878554 4;
BA_ "GenMsgCycleTime" BO_ 2566844762 100;
BA_ "GenMsgCycleTimeFast" BO_ 2566887489 100;
BA_ "GenMsgCycleTime" BO_ 2566887489 100;
BA_ "GenMsgSendType" BO_ 2566887489 4;
BA_ "GenMsgCycleTime" BO_ 2566853722 100;
BA_ "GenMsgCycleTime" BO_ 2365554060 10;
BA_ "GenMsgCycleTime" BO_ 2566877965 10;
BA_ "GenMsgCycleTime" BO_ 2365526260 1000;
BA_ "GenMsgCycleTime" BO_ 2365526259 1000;
BA_ "GenMsgCycleTime" BO_ 2365526516 100;
BA_ "GenMsgCycleTime" BO_ 2365526772 100;
BA_ "GenMsgCycleTime" BO_ 2365526004 100;
BA_ "GenMsgCycleTime" BO_ 2365526515 100;
BA_ "GenMsgCycleTime" BO_ 2365526771 100;
BA_ "GenMsgCycleTime" BO_ 2365526003 100;
BA_ "GenMsgCycleTime" BO_ 2298415094 10;
BA_ "GenMsgCycleTime" BO_ 2298415095 10;
BA_ "GenMsgCycleTime" BO_ 2298415090 10;
BA_ "GenMsgCycleTime" BO_ 2298415089 10;
BA_ "GenMsgCycleTime" BO_ 2298415088 10;
BA_ "GenMsgCycleTime" BO_ 2298415087 10;
BA_ "GenMsgCycleTime" BO_ 2566834735 100;
BA_ "GenMsgCycleTime" BO_ 2566854912 100;
BA_ "GenMsgCycleTime" BO_ 2566855680 1000;
BA_ "GenMsgCycleTime" BO_ 2566886912 1000;
BA_ "GenMsgCycleTime" BO_ 2566886400 100;
BA_ "GenMsgCycleTime" BO_ 2566878227 100;
BA_ "GenMsgCycleTime" BO_ 2566878987 20;
BA_ "GenMsgCycleTime" BO_ 2566907687 100;
BA_ "GenMsgCycleTime" BO_ 2566907943 100;
BA_ "GenMsgCycleTime" BO_ 2566910247 100;
BA_ "GenMsgCycleTime" BO_ 2566910503 100;
BA_ "GenMsgCycleTime" BO_ 2566910759 100;
BA_ "GenMsgCycleTime" BO_ 2566911015 100;
BA_ "GenMsgCycleTime" BO_ 2566911271 100;
BA_ "GenMsgCycleTime" BO_ 2566913547 100;
BA_ "GenMsgCycleTime" BO_ 2566912551 100;
BA_ "GenMsgCycleTime" BO_ 2566908427 100;
BA_ "GenMsgCycleTime" BO_ 2566907392 100;
BA_ "GenMsgCycleTime" BO_ 2566906880 100;
BA_ "GenMsgCycleTime" BO_ 2566906624 100;
BA_ "GenMsgCycleTime" BO_ 2566906368 100;
BA_ "GenMsgCycleTime" BO_ 2566906112 100;
BA_ "GenMsgCycleTime" BO_ 2566905344 100;
BA_ "GenMsgCycleTime" BO_ 2566904064 100;
BA_ "GenMsgCycleTime" BO_ 2566903808 100;
BA_ "GenMsgCycleTime" BO_ 2566903552 100;
BA_ "GenMsgCycleTime" BO_ 2566903296 100;
BA_ "GenMsgCycleTime" BO_ 2566902784 100;
BA_ "GenMsgCycleTime" BO_ 2566902528 100;
BA_ "GenMsgCycleTime" BO_ 2566901504 100;
BA_ "GenMsgCycleTime" BO_ 2566901248 100;
BA_ "SigType" SG_ 3221225472 DM_SPN2 1.7E-308;
BA_ "SigType" SG_ 3221225472 DM_SPN3 1.7E-308;
BA_ "SPN" SG_ 3221225472 DM_SPN1 1214;
BA_ "SigType" SG_ 3221225472 DM_SPN1 1.7E-308;
BA_ "SPN" SG_ 3221225472 DM_FailureModeIdentifier 1215;
BA_ "SigType" SG_ 3221225472 DM_FailureModeIdentifier 1.7E-308;
BA_ "SPN" SG_ 3221225472 DM_SPNConversionMethod 1706;
BA_ "SigType" SG_ 3221225472 DM_SPNConversionMethod 1.7E-308;
BA_ "SPN" SG_ 3221225472 DM_OccurenceCount 1216;
BA_ "SigType" SG_ 3221225472 DM_OccurenceCount 1.7E-308;
BA_ "GenSigStartValue" SG_ 2564292857 DM15_SAE_Reserved2 1;
BA_ "GenSigStartValue" SG_ 2564292857 DM15_SAE_Reserved 1;
BA_ "GenSigStartValue" SG_ 2564358393 DM14_SAE_Reserved 1;
BA_ "SPN" SG_ 2566846298 NetBatteryCurrent 114;
BA_ "SigType" SG_ 2566846298 NetBatteryCurrent 1.7E-308;
BA_ "SPN" SG_ 2566846298 AlternatorCurrent 115;
BA_ "SigType" SG_ 2566846298 AlternatorCurrent 1.7E-308;
BA_ "SPN" SG_ 2566846298 ChargingSystemPotential 167;
BA_ "SigType" SG_ 2566846298 ChargingSystemPotential 1.7E-308;
BA_ "SPN" SG_ 2566846298 BatteryPotential 168;
BA_ "SigType" SG_ 2566846298 BatteryPotential 1.7E-308;
BA_ "SPN" SG_ 2566846298 KeyswitchBatteryPotential 158;
BA_ "SigType" SG_ 2566846298 KeyswitchBatteryPotential 1.7E-308;
BA_ "SPN" SG_ 2633984602 pHeatedGripEnable 520366;
BA_ "SPN" SG_ 2633984602 pSideStandStatus 524098;
BA_ "SigType" SG_ 2633984602 pSideStandStatus 1.7E-308;
BA_ "SPN" SG_ 2633984602 pTetherSwitchStatus 520600;
BA_ "SPN" SG_ 2633984602 pLowFuelIndicatorStatus 524087;
BA_ "SPN" SG_ 2633984602 pOperatorNotInOperatingStation 2832;
BA_ "SPN" SG_ 2633984602 pParkBrakeIndicatorStatus 524271;
BA_ "SPN" SG_ 2633984602 pADCRequested 524139;
BA_ "SPN" SG_ 2633984602 pAWDModeRequested 524138;
BA_ "SPN" SG_ 2633984602 pRWDModeRequested 524137;
BA_ "SPN" SG_ 2633984602 pTurfModeRequested 524136;
BA_ "SPN" SG_ 2633984602 pADCStatus 524013;
BA_ "SigType" SG_ 2633984602 pADCStatus 1.7E-308;
BA_ "SPN" SG_ 2633984602 pTreadleNeutralStatus 524017;
BA_ "SigType" SG_ 2633984602 pTreadleNeutralStatus 1.7E-308;
BA_ "SPN" SG_ 2633984602 pTreadleReverseStatus 524018;
BA_ "SigType" SG_ 2633984602 pTreadleReverseStatus 1.7E-308;
BA_ "SPN" SG_ 2633984602 pSecurityLightStatus 524019;
BA_ "SigType" SG_ 2633984602 pSecurityLightStatus 1.7E-308;
BA_ "SPN" SG_ 2633984602 pHighBeamIndicatorStatus 524084;
BA_ "SigType" SG_ 2633984602 pHighBeamIndicatorStatus 1.7E-308;
BA_ "SPN" SG_ 2633984602 pHeatedGripsPercentage 524096;
BA_ "SigType" SG_ 2633984602 pHeatedGripsPercentage 1.7E-308;
BA_ "SPN" SG_ 2633984602 pCruiseControlSetStatus 524097;
BA_ "SigType" SG_ 2633984602 pCruiseControlSetStatus 1.7E-308;
BA_ "SPN" SG_ 2633984602 pSeatBeltIndicatorStatus 524092;
BA_ "SigType" SG_ 2633984602 pSeatBeltIndicatorStatus 1.7E-308;
BA_ "SPN" SG_ 2365530458 pChecksum_520571 520571;
BA_ "SPN" SG_ 2365530458 pMessageCounter_520570 520570;
BA_ "SPN" SG_ 2365530458 pEngineSpeed_520569 520569;
BA_ "SPN" SG_ 2365530458 pEngineTorque_Driver_Demanded 520568;
BA_ "SPN" SG_ 2365530458 pEngineTorque 520567;
BA_ "SPN" SG_ 2365530458 pSource_Address_Ctrling_Device 520566;
BA_ "SPN" SG_ 2566843994 EngineCoolantTemperature 110;
BA_ "SigType" SG_ 2566843994 EngineCoolantTemperature 1.7E-308;
BA_ "SPN" SG_ 2566843994 EngFuelTemperature1 174;
BA_ "SigType" SG_ 2566843994 EngFuelTemperature1 1.7E-308;
BA_ "SPN" SG_ 2566843994 EngineOilTemperature1 175;
BA_ "SigType" SG_ 2566843994 EngineOilTemperature1 1.7E-308;
BA_ "SPN" SG_ 2566843994 EngTurboOilTemperature 176;
BA_ "SigType" SG_ 2566843994 EngTurboOilTemperature 1.7E-308;
BA_ "SPN" SG_ 2566843994 EngineIntercoolerTemperature 52;
BA_ "SigType" SG_ 2566843994 EngineIntercoolerTemperature 1.7E-308;
BA_ "SPN" SG_ 2566843994 EngineIntercoolerThermosatOpen 1134;
BA_ "SigType" SG_ 2566843994 EngineIntercoolerThermosatOpen 1.7E-308;
BA_ "SPN" SG_ 2566841690 EngTotalHoursOfOper 247;
BA_ "SigType" SG_ 2566841690 EngTotalHoursOfOper 1.7E-308;
BA_ "SPN" SG_ 2566841690 TotalEngineRevolutions 249;
BA_ "SigType" SG_ 2566841690 TotalEngineRevolutions 1.7E-308;
BA_ "SPN" SG_ 2566876762 pEngineOilPressureStatus 524076;
BA_ "SigType" SG_ 2566876762 pEngineOilPressureStatus 1.7E-308;
BA_ "SPN" SG_ 2566876762 pHydraulicOilPressureStatus 524075;
BA_ "SigType" SG_ 2566876762 pHydraulicOilPressureStatus 1.7E-308;
BA_ "SPN" SG_ 2566876762 pHydraulicOilTempStatus 524074;
BA_ "SigType" SG_ 2566876762 pHydraulicOilTempStatus 1.7E-308;
BA_ "SPN" SG_ 2566876672 pEngineOilPressureStatus 524076;
BA_ "SigType" SG_ 2566876672 pEngineOilPressureStatus 1.7E-308;
BA_ "SPN" SG_ 2566876672 pHydraulicOilPressureStatus 524075;
BA_ "SigType" SG_ 2566876672 pHydraulicOilPressureStatus 1.7E-308;
BA_ "SPN" SG_ 2566876672 pHydraulicOilTempStatus 524074;
BA_ "SigType" SG_ 2566876672 pHydraulicOilTempStatus 1.7E-308;
BA_ "SPN" SG_ 2365553933 MessageCounter 4206;
BA_ "SigType" SG_ 2365553933 MessageCounter 1.7E-308;
BA_ "SPN" SG_ 2565866755 TransmissionSelectedGear 524;
BA_ "SigType" SG_ 2565866755 TransmissionSelectedGear 1.7E-308;
BA_ "SPN" SG_ 2565866755 TransmissionActualGearRatio 526;
BA_ "SigType" SG_ 2565866755 TransmissionActualGearRatio 1.7E-308;
BA_ "SPN" SG_ 2565866755 TransmissionCurrentGear 523;
BA_ "SigType" SG_ 2565866755 TransmissionCurrentGear 1.7E-308;
BA_ "SPN" SG_ 2565866755 TransmissionRqstedRange 162;
BA_ "SigType" SG_ 2565866755 TransmissionRqstedRange 1.7E-308;
BA_ "SPN" SG_ 2565866755 TransmissionCurrentRange 163;
BA_ "SigType" SG_ 2565866755 TransmissionCurrentRange 1.7E-308;
BA_ "GenSigStartValue" SG_ 2566844675 pCruiseCntrlCounter 7;
BA_ "SPN" SG_ 2566844675 pCruiseCntrlCounter 524080;
BA_ "SPN" SG_ 2566844675 TwoSpeedAxleSwitch 69;
BA_ "SigType" SG_ 2566844675 TwoSpeedAxleSwitch 1.7E-308;
BA_ "SPN" SG_ 2566844675 ParkingBrakeSwitch 70;
BA_ "SigType" SG_ 2566844675 ParkingBrakeSwitch 1.7E-308;
BA_ "SPN" SG_ 2566844675 Wheel_BasedVehicleSpeed 84;
BA_ "SigType" SG_ 2566844675 Wheel_BasedVehicleSpeed 1.7E-308;
BA_ "SPN" SG_ 2566844675 CruiseCtrlActive 595;
BA_ "SigType" SG_ 2566844675 CruiseCtrlActive 1.7E-308;
BA_ "SPN" SG_ 2566844675 CruiseCtrlEnableSwitch 596;
BA_ "SigType" SG_ 2566844675 CruiseCtrlEnableSwitch 1.7E-308;
BA_ "SPN" SG_ 2566844675 BrakeSwitch 597;
BA_ "SigType" SG_ 2566844675 BrakeSwitch 1.7E-308;
BA_ "SPN" SG_ 2566844675 ClutchSwitch 598;
BA_ "SigType" SG_ 2566844675 ClutchSwitch 1.7E-308;
BA_ "SPN" SG_ 2566844675 CruiseCtrlSetSwitch 599;
BA_ "SigType" SG_ 2566844675 CruiseCtrlSetSwitch 1.7E-308;
BA_ "SPN" SG_ 2566844675 CruiseCtrlCoastSwitch 600;
BA_ "SigType" SG_ 2566844675 CruiseCtrlCoastSwitch 1.7E-308;
BA_ "SPN" SG_ 2566844675 CruiseCtrlResumeSwitch 601;
BA_ "SigType" SG_ 2566844675 CruiseCtrlResumeSwitch 1.7E-308;
BA_ "SPN" SG_ 2566844675 CruiseCtrlAccelerateSwitch 602;
BA_ "SigType" SG_ 2566844675 CruiseCtrlAccelerateSwitch 1.7E-308;
BA_ "SPN" SG_ 2566844675 CruiseCtrlSetSpeed 86;
BA_ "SigType" SG_ 2566844675 CruiseCtrlSetSpeed 1.7E-308;
BA_ "SPN" SG_ 2566844675 pOdometerDriveBit 523994;
BA_ "SigType" SG_ 2566844675 pOdometerDriveBit 1.7E-308;
BA_ "SPN" SG_ 2566844675 CruiseCtrlPauseSw 1633;
BA_ "SigType" SG_ 2566844675 CruiseCtrlPauseSw 1.7E-308;
BA_ "SPN" SG_ 2566844675 pCCChecksum 524079;
BA_ "SigType" SG_ 2566844675 pCCChecksum 1.7E-308;
BA_ "SPN" SG_ 2566844675 pCruiseEnableStatus 524108;
BA_ "SigType" SG_ 2566844675 pCruiseEnableStatus 1.7E-308;
BA_ "SPN" SG_ 2231304282 pEPCU_1_Speed_Limit 524251;
BA_ "SPN" SG_ 2231304282 pEPCU_1_Counter_Torque_Limit 524251;
BA_ "SPN" SG_ 2231304282 pEPCU_1_Torque_Demand 524251;
BA_ "SPN" SG_ 2231304282 pEPCU_1_Control_Mode 524251;
BA_ "SPN" SG_ 2231304282 pEPCU_1_Message_Counter 524251;
BA_ "SPN" SG_ 2231304282 pEPCU_1_Checksum 524251;
BA_ "SPN" SG_ 2231309146 pEPCU_1_Speed_Limit 524251;
BA_ "SPN" SG_ 2231309146 pEPCU_1_Counter_Torque_Limit 524251;
BA_ "SPN" SG_ 2231309146 pEPCU_1_Torque_Demand 524251;
BA_ "SPN" SG_ 2231309146 pEPCU_1_Control_Mode 524251;
BA_ "SPN" SG_ 2231309146 pEPCU_1_Message_Counter 524251;
BA_ "SPN" SG_ 2231309146 pEPCU_1_Checksum 524251;
BA_ "SPN" SG_ 2365525594 WATT_pPack_Voltage 524217;
BA_ "SPN" SG_ 2365525594 WATT_pPack_Current 524216;
BA_ "SPN" SG_ 2365525594 WATT_pDischarge_Limit 524218;
BA_ "SPN" SG_ 2365525594 WATT_pCharge_Limit 524219;
BA_ "SPN" SG_ 2365525594 WATT_pBMC_Pwr_Msg_Check_Seq 524252;
BA_ "SPN" SG_ 2566878554 pChecksum_524123 524123;
BA_ "SPN" SG_ 2566878554 pMessageCounter_524122 524122;
BA_ "SPN" SG_ 2566878554 pOperationMode 524120;
BA_ "SPN" SG_ 2566878554 pStartStopCmd 520497;
BA_ "SPN" SG_ 2566878554 pNorm_Acc_Pos_520354 520354;
BA_ "SPN" SG_ 2566844762 TwoSpeedAxleSwitch 69;
BA_ "SigType" SG_ 2566844762 TwoSpeedAxleSwitch 1.7E-308;
BA_ "SPN" SG_ 2566844762 ParkingBrakeSwitch 70;
BA_ "SigType" SG_ 2566844762 ParkingBrakeSwitch 1.7E-308;
BA_ "SPN" SG_ 2566844762 Wheel_BasedVehicleSpeed 84;
BA_ "SigType" SG_ 2566844762 Wheel_BasedVehicleSpeed 1.7E-308;
BA_ "SPN" SG_ 2566844762 CruiseCtrlActive 595;
BA_ "SigType" SG_ 2566844762 CruiseCtrlActive 1.7E-308;
BA_ "SPN" SG_ 2566844762 CruiseCtrlEnableSwitch 596;
BA_ "SigType" SG_ 2566844762 CruiseCtrlEnableSwitch 1.7E-308;
BA_ "SPN" SG_ 2566844762 BrakeSwitch 597;
BA_ "SigType" SG_ 2566844762 BrakeSwitch 1.7E-308;
BA_ "SPN" SG_ 2566844762 ClutchSwitch 598;
BA_ "SigType" SG_ 2566844762 ClutchSwitch 1.7E-308;
BA_ "SPN" SG_ 2566844762 CruiseCtrlSetSwitch 599;
BA_ "SigType" SG_ 2566844762 CruiseCtrlSetSwitch 1.7E-308;
BA_ "SPN" SG_ 2566844762 CruiseCtrlCoastSwitch 600;
BA_ "SigType" SG_ 2566844762 CruiseCtrlCoastSwitch 1.7E-308;
BA_ "SPN" SG_ 2566844762 CruiseCtrlResumeSwitch 601;
BA_ "SigType" SG_ 2566844762 CruiseCtrlResumeSwitch 1.7E-308;
BA_ "SPN" SG_ 2566844762 CruiseCtrlAccelerateSwitch 602;
BA_ "SigType" SG_ 2566844762 CruiseCtrlAccelerateSwitch 1.7E-308;
BA_ "SPN" SG_ 2566844762 CruiseCtrlSetSpeed 86;
BA_ "SigType" SG_ 2566844762 CruiseCtrlSetSpeed 1.7E-308;
BA_ "SPN" SG_ 2566844762 pOdometerDriveBit 523994;
BA_ "SigType" SG_ 2566844762 pOdometerDriveBit 1.7E-308;
BA_ "SPN" SG_ 2566844762 CruiseCtrlPauseSw 1633;
BA_ "SigType" SG_ 2566844762 CruiseCtrlPauseSw 1.7E-308;
BA_ "SPN" SG_ 2566844762 pCCMessageCounter 524080;
BA_ "SigType" SG_ 2566844762 pCCMessageCounter 1.7E-308;
BA_ "SPN" SG_ 2566844762 pCCChecksum 524079;
BA_ "SigType" SG_ 2566844762 pCCChecksum 1.7E-308;
BA_ "SPN" SG_ 2566844762 pCruiseEnableStatus 524108;
BA_ "SigType" SG_ 2566844762 pCruiseEnableStatus 1.7E-308;
BA_ "SPN" SG_ 2566887489 pRiderWeightRearLeft 516103;
BA_ "SigType" SG_ 2566887489 pRiderWeightRearLeft 1.7E-308;
BA_ "SPN" SG_ 2566887489 pBoxLoadWeight 516105;
BA_ "SigType" SG_ 2566887489 pBoxLoadWeight 1.7E-308;
BA_ "SPN" SG_ 2566887489 pRiderWeightRearRight 516104;
BA_ "SigType" SG_ 2566887489 pRiderWeightRearRight 1.7E-308;
BA_ "SPN" SG_ 2566887489 pRiderWeightMidRight 516102;
BA_ "SigType" SG_ 2566887489 pRiderWeightMidRight 1.7E-308;
BA_ "SPN" SG_ 2566887489 pRiderWeightMidLeft 516101;
BA_ "SigType" SG_ 2566887489 pRiderWeightMidLeft 1.7E-308;
BA_ "SPN" SG_ 2566887489 pRiderWeightFrontRight 516100;
BA_ "SigType" SG_ 2566887489 pRiderWeightFrontRight 1.7E-308;
BA_ "SPN" SG_ 2566887489 pRiderWeightFrontLeft 516099;
BA_ "SigType" SG_ 2566887489 pRiderWeightFrontLeft 1.7E-308;
BA_ "SPN" SG_ 2566853722 pRangeToEmptyEV 520529;
BA_ "SPN" SG_ 2566853722 pEfficiencyEV 520528;
BA_ "SPN" SG_ 2365554060 MessageCounter 4206;
BA_ "SigType" SG_ 2365554060 MessageCounter 1.7E-308;
BA_ "SPN" SG_ 2365526260 WATT_pBattTempMin 524282;
BA_ "SPN" SG_ 2365526260 WATT_pTractionBat_Msg_Check_Seq 524254;
BA_ "SPN" SG_ 2365526260 WATT_pSOH 524223;
BA_ "SPN" SG_ 2365526260 WATT_pK_Battemp 524225;
BA_ "SPN" SG_ 2365526260 WATT_pFloat_State 524226;
BA_ "SPN" SG_ 2365526260 WATT_pBattery_Temp 524224;
BA_ "SPN" SG_ 2365526259 WATT_pBattTempMin 524282;
BA_ "SPN" SG_ 2365526259 WATT_pTractionBat_Msg_Check_Seq 524254;
BA_ "SPN" SG_ 2365526259 WATT_pSOH 524223;
BA_ "SPN" SG_ 2365526259 WATT_pK_Battemp 524225;
BA_ "SPN" SG_ 2365526259 WATT_pFloat_State 524226;
BA_ "SPN" SG_ 2365526259 WATT_pBattery_Temp 524224;
BA_ "SPN" SG_ 2365526516 WATT_pBMCStatusCntr 524273;
BA_ "SPN" SG_ 2365526516 WATT_pBatteryType 520404;
BA_ "SPN" SG_ 2365526516 WATT_pWAKE_State 524230;
BA_ "SPN" SG_ 2365526516 WATT_pKEY_State 524232;
BA_ "SPN" SG_ 2365526516 WATT_pDC_DC_State 524233;
BA_ "SPN" SG_ 2365526516 WATT_pBMC_Temp 524227;
BA_ "SPN" SG_ 2365526516 WATT_pBMC_Status_Msg_Check_Seq 524255;
BA_ "SPN" SG_ 2365526516 WATT_pBalance_State 524229;
BA_ "SPN" SG_ 2365526516 WATT_pBalance_Error 524228;
BA_ "SPN" SG_ 2365526772 pCharger_Status_Counter 524251;
BA_ "SPN" SG_ 2365526772 WATT_pCharger_Voltage 524235;
BA_ "SPN" SG_ 2365526772 WATT_pCharger_Temp 524236;
BA_ "SPN" SG_ 2365526772 WATT_pCharger_State 524239;
BA_ "SPN" SG_ 2365526772 WATT_pCharger_Stat_Msg_Check_Seq 524256;
BA_ "SPN" SG_ 2365526772 WATT_pCharger_Current 524234;
BA_ "SPN" SG_ 2365526772 WATT_pAC_Status 524238;
BA_ "SPN" SG_ 2365526004 WATT_pWh_In_Since_Key 524222;
BA_ "SPN" SG_ 2365526004 WATT_pSOC 524220;
BA_ "SPN" SG_ 2365526004 WATT_pEnergy_Msg_Check_Seq 524253;
BA_ "SPN" SG_ 2365526004 WATT_pAvailable_Wh 524221;
BA_ "SPN" SG_ 2365526515 WATT_pBMCStatusCntr 524273;
BA_ "SPN" SG_ 2365526515 WATT_pBatteryType 520404;
BA_ "SPN" SG_ 2365526515 WATT_pWAKE_State 524230;
BA_ "SPN" SG_ 2365526515 WATT_pKEY_State 524232;
BA_ "SPN" SG_ 2365526515 WATT_pDC_DC_State 524233;
BA_ "SPN" SG_ 2365526515 WATT_pBMC_Temp 524227;
BA_ "SPN" SG_ 2365526515 WATT_pBMC_Status_Msg_Check_Seq 524255;
BA_ "SPN" SG_ 2365526515 WATT_pBalance_State 524229;
BA_ "SPN" SG_ 2365526515 WATT_pBalance_Error 524228;
BA_ "SPN" SG_ 2365526771 pCharger_Status_Counter 524251;
BA_ "SPN" SG_ 2365526771 WATT_pCharger_Voltage 524235;
BA_ "SPN" SG_ 2365526771 WATT_pCharger_Temp 524236;
BA_ "SPN" SG_ 2365526771 WATT_pCharger_State 524239;
BA_ "SPN" SG_ 2365526771 WATT_pCharger_Stat_Msg_Check_Seq 524256;
BA_ "SPN" SG_ 2365526771 WATT_pCharger_Current 524234;
BA_ "SPN" SG_ 2365526771 WATT_pAC_Status 524238;
BA_ "SPN" SG_ 2365526003 WATT_pWh_In_Since_Key 524222;
BA_ "SPN" SG_ 2365526003 WATT_pSOC 524220;
BA_ "SPN" SG_ 2365526003 WATT_pEnergy_Msg_Check_Seq 524253;
BA_ "SPN" SG_ 2365526003 WATT_pAvailable_Wh 524221;
BA_ "SPN" SG_ 2298415094 WATT_pUpper_Available_Torque 524192;
BA_ "SPN" SG_ 2298415094 WATT_pPerformance_State 524190;
BA_ "SPN" SG_ 2298415094 WATT_pPerformance_Msg_Check_Seq 524249;
BA_ "SPN" SG_ 2298415094 WATT_pLower_Available_Torque 524193;
BA_ "SPN" SG_ 2298415094 WATT_pActual_Motor_Velocity 524194;
BA_ "SPN" SG_ 2298415094 WATT_pActual_Motor_torque 524191;
BA_ "SPN" SG_ 2298415095 WATT_pUpper_Available_Torque 524192;
BA_ "SPN" SG_ 2298415095 WATT_pPerformance_State 524190;
BA_ "SPN" SG_ 2298415095 WATT_pPerformance_Msg_Check_Seq 524249;
BA_ "SPN" SG_ 2298415095 WATT_pLower_Available_Torque 524193;
BA_ "SPN" SG_ 2298415095 WATT_pActual_Motor_Velocity 524194;
BA_ "SPN" SG_ 2298415090 WATT_pUpper_Available_Torque 524192;
BA_ "SPN" SG_ 2298415090 WATT_pPerformance_State 524190;
BA_ "SPN" SG_ 2298415090 WATT_pPerformance_Msg_Check_Seq 524249;
BA_ "SPN" SG_ 2298415090 WATT_pLower_Available_Torque 524193;
BA_ "SPN" SG_ 2298415090 WATT_pActual_Motor_Velocity 524194;
BA_ "SPN" SG_ 2298415090 WATT_pActual_Motor_torque 524191;
BA_ "SPN" SG_ 2298415089 WATT_pUpper_Available_Torque 524192;
BA_ "SPN" SG_ 2298415089 WATT_pPerformance_State 524190;
BA_ "SPN" SG_ 2298415089 WATT_pPerformance_Msg_Check_Seq 524249;
BA_ "SPN" SG_ 2298415089 WATT_pActual_Motor_Velocity 524194;
BA_ "SPN" SG_ 2298415089 WATT_pActual_Motor_torque 524191;
BA_ "SPN" SG_ 2298415088 WATT_pUpper_Available_Torque 524192;
BA_ "SPN" SG_ 2298415088 WATT_pPerformance_State 524190;
BA_ "SPN" SG_ 2298415088 WATT_pPerformance_Msg_Check_Seq 524249;
BA_ "SPN" SG_ 2298415088 WATT_pLower_Available_Torque 524193;
BA_ "SPN" SG_ 2298415088 WATT_pActual_Motor_Velocity 524194;
BA_ "SPN" SG_ 2298415088 WATT_pActual_Motor_torque 524191;
BA_ "SPN" SG_ 2298415087 WATT_pUpper_Available_Torque 524192;
BA_ "SPN" SG_ 2298415087 WATT_pPerformance_State 524190;
BA_ "SPN" SG_ 2298415087 WATT_pPerformance_Msg_Check_Seq 524249;
BA_ "SPN" SG_ 2298415087 WATT_pLower_Available_Torque 524193;
BA_ "SPN" SG_ 2298415087 WATT_pActual_Motor_Velocity 524194;
BA_ "SPN" SG_ 2298415087 WATT_pActual_Motor_torque 524191;
BA_ "SPN" SG_ 2566834735 DM_FlashRedStopLamp 3039;
BA_ "SPN" SG_ 2566834735 DM_FlashProtectLamp 3041;
BA_ "SPN" SG_ 2566834735 DM_FlashMalfuncIndicatorLamp 3038;
BA_ "SPN" SG_ 2566834735 DM_FlashAmberWarningLamp 3040;
BA_ "SigType" SG_ 2566834735 DTC5 7;
BA_ "SigType" SG_ 2566834735 DTC4 7;
BA_ "SigType" SG_ 2566834735 DTC3 7;
BA_ "SigType" SG_ 2566834735 DTC2 7;
BA_ "SigType" SG_ 2566834735 DTC1 7;
BA_ "SPN" SG_ 2566834735 DM_ProtectLampStatus 987;
BA_ "SigType" SG_ 2566834735 DM_ProtectLampStatus 1.7E-308;
BA_ "SPN" SG_ 2566834735 DM_RedStopLampState 623;
BA_ "SigType" SG_ 2566834735 DM_RedStopLampState 1.7E-308;
BA_ "SPN" SG_ 2566834735 DM_AmberWrningLmpStatus 624;
BA_ "SigType" SG_ 2566834735 DM_AmberWrningLmpStatus 1.7E-308;
BA_ "SPN" SG_ 2566834735 DM_MalfuncnIndicatorLampStatus 1213;
BA_ "SigType" SG_ 2566834735 DM_MalfuncnIndicatorLampStatus 1.7E-308;
BA_ "SigType" SG_ 2566903040 DL_CrankReqInput 1.7E-308;
BA_ "SigType" SG_ 2566903040 DL_LowOilLevelInput 1.7E-308;
BA_ "SigType" SG_ 2566903040 DL_LoadAnticipate1Input 1.7E-308;
BA_ "SigType" SG_ 2566903040 DL_LoadAnticipate2Input 1.7E-308;
BA_ "SigType" SG_ 2566903040 DL_CruiseDecelInputActive 1.7E-308;
BA_ "SigType" SG_ 2566903040 DL_CruiseAccelInputActive 1.7E-308;
BA_ "SigType" SG_ 2566903040 DL_PowertrainRelayOutput 1.7E-308;
BA_ "SigType" SG_ 2566903040 DL_StarterRelayOutput 1.7E-308;
BA_ "SigType" SG_ 2566903040 DL_FuelPump1RelayOutput 1.7E-308;
BA_ "SigType" SG_ 2566903040 DL_SlowmodeInputActive 1.7E-308;
BA_ "SigType" SG_ 2566903040 DL_SlowModeLampOutput 1.7E-308;
BA_ "SigType" SG_ 2566903040 DL_GovCruiseSync 1.7E-308;
BA_ "SigType" SG_ 2566903040 DL_DiscreteLowOilPressInput 1.7E-308;
BA_ "SigType" SG_ 2566903040 DL_MILOutput 1.7E-308;
BA_ "SPN" SG_ 2566855680 pRqstdPerFan1DutyCycle 520361;
BA_ "SPN" SG_ 2566855680 pFan1DirectionCmd 520360;
BA_ "SPN" SG_ 2566886912 pFleetMgmtDefVehState 520638;
BA_ "SPN" SG_ 2566886912 pVehEnblDisbl 520637;
BA_ "SPN" SG_ 2566886912 pUserAuthenticationStatus 520636;
BA_ "SPN" SG_ 2566886912 pBoundaryStatus 520635;
BA_ "SPN" SG_ 2566886400 EngineCyldr2IngnitionTmg 520535;
BA_ "SPN" SG_ 2566886400 EngineCyldr1IgnitionTmg 520534;
BA_ "SPN" SG_ 2566886400 DesiredLambda 520533;
BA_ "SPN" SG_ 2566886400 HighRngEngPerLoad 520532;
BA_ "SPN" SG_ 2566878227 pEPSShaftVelocity 524115;
BA_ "SPN" SG_ 2566878227 pEPSShaftPosition 524114;
BA_ "SPN" SG_ 2566878227 pEPSSASCalibrated 524118;
BA_ "SPN" SG_ 2566878227 pEPSOperationStatus 524117;
BA_ "SPN" SG_ 2566878227 pEPSOperationMode 524116;
BA_ "SPN" SG_ 2365553931 MessageCounter 4206;
BA_ "SigType" SG_ 2365553931 MessageCounter 1.7E-308;
BA_ "SigType" SG_ 2566907687 DL20_KeyFobBatteryVoltage 1.7E-308;
BA_ "SigType" SG_ 2566907687 DL20_LeanAngle 1.7E-308;
BA_ "SigType" SG_ 2566907943 DL19_TirePressure_Rear_Left_Only 1.7E-308;
BA_ "SigType" SG_ 2566907943 DL19_TirePressureFront_Left_Only 1.7E-308;
BA_ "SigType" SG_ 2566907943 DL19_TirePressureFrontRight 1.7E-308;
BA_ "SigType" SG_ 2566907943 DL19_TirePressureRearRight 1.7E-308;
BA_ "SigType" SG_ 2566910247 FI5_b10Sec 1.7E-308;
BA_ "SigType" SG_ 2566910247 FI5_bBatt 1.7E-308;
BA_ "SigType" SG_ 2566910247 FI5_bEnable 1.7E-308;
BA_ "SigType" SG_ 2566910247 FI5_bLazyCRC 1.7E-308;
BA_ "SigType" SG_ 2566910247 FI5_bManCyc 1.7E-308;
BA_ "SigType" SG_ 2566910247 FI5_bNotRun 1.7E-308;
BA_ "SigType" SG_ 2566910247 FI5_bOper 1.7E-308;
BA_ "SigType" SG_ 2566910503 FI4_BrakeLightOutput 1.7E-308;
BA_ "SigType" SG_ 2566910503 FI4_FogLightInput 1.7E-308;
BA_ "SigType" SG_ 2566910503 FI4_HazardLightOutput 1.7E-308;
BA_ "SigType" SG_ 2566910503 FI4_HazardSWInput 1.7E-308;
BA_ "SigType" SG_ 2566910503 FI4_HeatGripDecSW 1.7E-308;
BA_ "SigType" SG_ 2566910503 FI4_HeatGripIncSW 1.7E-308;
BA_ "SigType" SG_ 2566910503 FI4_HighBeamOutput 1.7E-308;
BA_ "SigType" SG_ 2566910503 FI4_HornInput 1.7E-308;
BA_ "SigType" SG_ 2566910503 FI4_HornOutput 1.7E-308;
BA_ "SigType" SG_ 2566910503 FI4_LeftFogLightOutput 1.7E-308;
BA_ "SigType" SG_ 2566910503 FI4_LFTurnSignalOutput 1.7E-308;
BA_ "SigType" SG_ 2566910503 FI4_LockInput 1.7E-308;
BA_ "SigType" SG_ 2566910503 FI4_LowBeamOutput 1.7E-308;
BA_ "SigType" SG_ 2566910503 FI4_LowHighBeamInput 1.7E-308;
BA_ "SigType" SG_ 2566910503 FI4_LRTurnSignalOutput 1.7E-308;
BA_ "SigType" SG_ 2566910503 FI4_pOperatorButton1 1.7E-308;
BA_ "SigType" SG_ 2566910503 FI4_RFTurnSignalOutput 1.7E-308;
BA_ "SigType" SG_ 2566910503 FI4_RightFogLightOutput 1.7E-308;
BA_ "SigType" SG_ 2566910503 FI4_RRTurnSignalOutput 1.7E-308;
BA_ "SigType" SG_ 2566910503 FI4_SecondaryAirValveCmd 1.7E-308;
BA_ "SigType" SG_ 2566910503 FI4_SecondaryAirValveOut 1.7E-308;
BA_ "SigType" SG_ 2566910503 FI4_TailLightOutput 1.7E-308;
BA_ "SigType" SG_ 2566910503 FI4_UnlockInput 1.7E-308;
BA_ "SigType" SG_ 2566910503 FI4_WindshieldSWDownInput 1.7E-308;
BA_ "SigType" SG_ 2566910503 FI4_WindshieldSWUpInput 1.7E-308;
BA_ "SigType" SG_ 2566910503 FI4_pOperatorButton2 1.7E-308;
BA_ "SigType" SG_ 2566910759 FI3_DriveMode1Input 1.7E-308;
BA_ "SigType" SG_ 2566910759 FI3_DriveMode2Input 1.7E-308;
BA_ "SigType" SG_ 2566910759 FI3_DriveMode3Input 1.7E-308;
BA_ "SigType" SG_ 2566910759 FI3_DriverMode4Input 1.7E-308;
BA_ "SigType" SG_ 2566910759 FI3_DriverMode1Output 1.7E-308;
BA_ "SigType" SG_ 2566910759 FI3_DriverMode2Output 1.7E-308;
BA_ "SigType" SG_ 2566910759 FI3_DriverMode3Output 1.7E-308;
BA_ "SigType" SG_ 2566910759 FI3_DriverMode4Ouput 1.7E-308;
BA_ "SigType" SG_ 2566910759 FI3_PTOModeInput 1.7E-308;
BA_ "SigType" SG_ 2566910759 FI3_PTOModeOutput 1.7E-308;
BA_ "SigType" SG_ 2566910759 FI3_DriversNetEngagement 1.7E-308;
BA_ "SigType" SG_ 2566910759 FI3_DriversSeatbeltEngagement 1.7E-308;
BA_ "SigType" SG_ 2566910759 FI3_TiltLockInput 1.7E-308;
BA_ "SigType" SG_ 2566910759 FI3_WorkGroupLockInput 1.7E-308;
BA_ "SigType" SG_ 2566910759 FI3_OperatorPresenceInput 1.7E-308;
BA_ "SigType" SG_ 2566910759 FI3_WorkGroupLockOutput 1.7E-308;
BA_ "SigType" SG_ 2566910759 FI3_OperatorPresenceOutput 1.7E-308;
BA_ "SigType" SG_ 2566910759 FI3_FootOnCruiseInput 1.7E-308;
BA_ "SigType" SG_ 2566910759 FI3_CruiseInput 1.7E-308;
BA_ "SigType" SG_ 2566910759 FI3_TredalInput 1.7E-308;
BA_ "SigType" SG_ 2566910759 FI3_CruiseSpeedInput 1.7E-308;
BA_ "SigType" SG_ 2566910759 FI3_FootOnCruiseOutput 1.7E-308;
BA_ "SigType" SG_ 2566910759 FI3_CruiseOutput 1.7E-308;
BA_ "SigType" SG_ 2566910759 FI3_CruiseControltoSetSpeed 1.7E-308;
BA_ "SigType" SG_ 2566910759 FI3_WorkModeInput 1.7E-308;
BA_ "SigType" SG_ 2566910759 FI3_TiltLockOutput 1.7E-308;
BA_ "SigType" SG_ 2566911015 FI2_ADCOutput 1.7E-308;
BA_ "SigType" SG_ 2566911015 FI2_RearDiffLockOutput 1.7E-308;
BA_ "SigType" SG_ 2566911015 FI2_AWDOutput 1.7E-308;
BA_ "SigType" SG_ 2566911015 FI2_BrakeSwitchInput 1.7E-308;
BA_ "SigType" SG_ 2566911015 FI2_ADCSwitchInput 1.7E-308;
BA_ "SigType" SG_ 2566911015 FI2_TurfModeInput 1.7E-308;
BA_ "SigType" SG_ 2566911015 FI2_AWDSwitchInput 1.7E-308;
BA_ "SigType" SG_ 2566911015 FI2_ReverseSwitchInput 1.7E-308;
BA_ "SigType" SG_ 2566911015 FI2_ReverseLimitSwitchInput 1.7E-308;
BA_ "SigType" SG_ 2566911015 FI2_ForwardLimitSwitchInput 1.7E-308;
BA_ "SigType" SG_ 2566911015 FI2_EngineDirection 1.7E-308;
BA_ "SigType" SG_ 2566911015 FI2_RevSpeedLimitOverrideInput 1.7E-308;
BA_ "SigType" SG_ 2566911015 FI2_ReverseOverspeedSignal 1.7E-308;
BA_ "SigType" SG_ 2566911015 FI2_RightTurnSignalInput 1.7E-308;
BA_ "SigType" SG_ 2566911015 FI2_LeftTurnSignalInput 1.7E-308;
BA_ "SigType" SG_ 2566911015 FI2_KickstandSwitchInput 1.7E-308;
BA_ "SigType" SG_ 2566911015 FI2_ReflashEnableInputSignal 1.7E-308;
BA_ "SigType" SG_ 2566911015 FI2_TPSLearnInputSignal 1.7E-308;
BA_ "SigType" SG_ 2566911015 FI2_LowRangeSwitchInput 1.7E-308;
BA_ "SigType" SG_ 2566911015 FI2_ReverseMotorDriveInput 1.7E-308;
BA_ "SigType" SG_ 2566911271 FI1_FuelPumpDriverCkt 1.7E-308;
BA_ "SigType" SG_ 2566911271 FI1_RolloverSwitch 1.7E-308;
BA_ "SigType" SG_ 2566911271 FI1_CrankSensorSignal 1.7E-308;
BA_ "SigType" SG_ 2566911271 FI1_CamSensorSignal 1.7E-308;
BA_ "SigType" SG_ 2566911271 FI1_RPMLimitActive 1.7E-308;
BA_ "SigType" SG_ 2566911271 FI1_IdleSwitch 1.7E-308;
BA_ "SigType" SG_ 2566911271 FI1_CycleSynchro 1.7E-308;
BA_ "SigType" SG_ 2566911271 FI1_IdleSpeedControlStatus 1.7E-308;
BA_ "SigType" SG_ 2566911271 FI1_IgnitionSwitchInput 1.7E-308;
BA_ "SigType" SG_ 2566911271 FI1_RunStopSwitchInput 1.7E-308;
BA_ "SigType" SG_ 2566911271 FI1_StartSwitchInput 1.7E-308;
BA_ "SigType" SG_ 2566911271 FI1_ThrottleSafetySwInput 1.7E-308;
BA_ "SigType" SG_ 2566911271 FI1_FanRelayOutput 1.7E-308;
BA_ "SigType" SG_ 2566911271 FI1_IntercoolerFanOutput 1.7E-308;
BA_ "SigType" SG_ 2566911271 FI1_ReverseAlarmOutput 1.7E-308;
BA_ "SigType" SG_ 2566911271 FI1_MainRelayOutput 1.7E-308;
BA_ "SigType" SG_ 2566911271 FI1_StartSolenoidOutput 1.7E-308;
BA_ "SigType" SG_ 2566911271 FI1_IgnitionRelayOutput 1.7E-308;
BA_ "SigType" SG_ 2566911271 FI1_ChassisRelayOutput 1.7E-308;
BA_ "SigType" SG_ 2566911271 FI1_StarterEnableOutput 1.7E-308;
BA_ "SigType" SG_ 2566911271 FI1_ExhaustValveOutput 1.7E-308;
BA_ "SigType" SG_ 2566911271 FI1_BatteryChargeRelayOutput 1.7E-308;
BA_ "SigType" SG_ 2566911271 FI1_HeaterAccRelay 1.7E-308;
BA_ "SigType" SG_ 2566911271 FI1_ClutchSwitchInput 1.7E-308;
BA_ "SigType" SG_ 2566911271 FI1_MILLampOutput 1.7E-308;
BA_ "SigType" SG_ 2566911271 FI1_OverTempLampOutput 1.7E-308;
BA_ "SigType" SG_ 2566911271 FI1_KnockDetLampOutput 1.7E-308;
BA_ "SigType" SG_ 2566911271 FI1_ElecOilPumpDrvrCirc 1.7E-308;
BA_ "SigType" SG_ 2566913547 DL2_EngineThrottlePosition 1.7E-308;
BA_ "SigType" SG_ 2566913547 DL2_EngineCoolantTemperature 1.7E-308;
BA_ "SigType" SG_ 2566913547 DL2_EngineAirInletTemperature 1.7E-308;
BA_ "SigType" SG_ 2566913547 DL2_EngIntakeManifoldPressure 1.7E-308;
BA_ "SigType" SG_ 2566913547 DL2_Boost 1.7E-308;
BA_ "SigType" SG_ 2566913547 DL2_BarometricPressure 1.7E-308;
BA_ "SigType" SG_ 2566913547 DL2_Wheel_BasedVehicleSpeed 1.7E-308;
BA_ "SigType" SG_ 2566913547 DL2_BarometricPressure_Volts 1.7E-308;
BA_ "SigType" SG_ 2566912551 DL6_GearVolts 1.7E-308;
BA_ "SigType" SG_ 2566912551 DL6_RolloverVolts 1.7E-308;
BA_ "SigType" SG_ 2566912551 DL6_ThrottleReleaseInputVolts 1.7E-308;
BA_ "SigType" SG_ 2566912551 DL6_FuelTypeSensorVolts 1.7E-308;
BA_ "SigType" SG_ 2566908427 DL17_Wheel_Spd_Front_LSB 1.7E-308;
BA_ "SigType" SG_ 2566908427 DL17_Wheel_Spd_Front_MSB 1.7E-308;
BA_ "SigType" SG_ 2566908427 DL17_Wheel_Spd_Rear_LSB 1.7E-308;
BA_ "SigType" SG_ 2566908427 DL17_Wheel_Spd_Rear_MSB 1.7E-308;
BA_ "SigType" SG_ 2566908427 DL17_ABS_Source_Voltage 1.7E-308;
BA_ "SigType" SG_ 2566908427 DL17_ABS_Pump_Command 1.7E-308;
BA_ "SigType" SG_ 2566908427 DL17_Brake_Sw_Status 1.7E-308;
BA_ "SigType" SG_ 2566908427 DL17_ABS_Failsafe_Relay 1.7E-308;
BA_ "SigType" SG_ 2566908427 DL17_ABS_Evac_Fill 1.7E-308;
BA_ "SigType" SG_ 2566908427 DL17_RedBrakeLamp 1.7E-308;
BA_ "SigType" SG_ 2566908427 DL17_ABSFaultLamp 1.7E-308;
BA_ "SigType" SG_ 2566908427 DL17_TCSDisabledLamp 1.7E-308;
BA_ "SigType" SG_ 2566908427 DL17_ESCDisabledLamp 1.7E-308;
BA_ "SigType" SG_ 2566908427 DL17_ESCFaultLampFlashing 1.7E-308;
BA_ "SigType" SG_ 2566908427 DL17_ESCFaultLampSolid 1.7E-308;
BA_ "SigType" SG_ 2566908427 DL17_TorqueRequestedtoECM 1.7E-308;
BA_ "SigType" SG_ 2566908427 DL17_TractionCtrlOverrideSwitch 1.7E-308;
BA_ "SigType" SG_ 2566907392 DL_O2SensorA1 1.7E-308;
BA_ "SigType" SG_ 2566907392 DL_O2SensorA1Condition 1.7E-308;
BA_ "SigType" SG_ 2566907392 DL_O2SensorA1Status 1.7E-308;
BA_ "SigType" SG_ 2566907392 DL_ClosedLoopFuelControl 1.7E-308;
BA_ "SigType" SG_ 2566907392 DL_O2SensorA1Volt 1.7E-308;
BA_ "SigType" SG_ 2566907392 DL_O2SensA1RichLeanCrossCnt 1.7E-308;
BA_ "SigType" SG_ 2566907392 DL_BankA_BLMCell 1.7E-308;
BA_ "SigType" SG_ 2566907392 DL_BankA_BLMCellValue 1.7E-308;
BA_ "SigType" SG_ 2566907392 DL_BankAFuelMult 1.7E-308;
BA_ "SigType" SG_ 2566907392 DL_O2SensorA1HeaterCurrent 1.7E-308;
BA_ "SigType" SG_ 2566906880 DL_PedalPositionSensor1Volt 1.7E-308;
BA_ "SigType" SG_ 2566906880 DL_PedalPositionSensor2Volt 1.7E-308;
BA_ "SigType" SG_ 2566906880 DL_PedalPosition 1.7E-308;
BA_ "SigType" SG_ 2566906624 DL_MATSensor 1.7E-308;
BA_ "SigType" SG_ 2566906624 DL_CoolantTempSensorResis 1.7E-308;
BA_ "SigType" SG_ 2566906624 DL_CoolantTemp 1.7E-308;
BA_ "SigType" SG_ 2566906624 DL_MATSensorResist 1.7E-308;
BA_ "SigType" SG_ 2566906624 DL_ManifoldAirTemp 1.7E-308;
BA_ "SigType" SG_ 2566906368 DL_ETCPresent 1.7E-308;
BA_ "SigType" SG_ 2566906368 DL_ETCHbridgeCurrentDirection 1.7E-308;
BA_ "SigType" SG_ 2566906368 DL_MinPositionLearningPending 1.7E-308;
BA_ "SigType" SG_ 2566906368 DL_TPSSensor1RawVolt 1.7E-308;
BA_ "SigType" SG_ 2566906368 DL_TPSSensor2RawVolt 1.7E-308;
BA_ "SigType" SG_ 2566906368 DL_ThrottlePosition 1.7E-308;
BA_ "SigType" SG_ 2566906368 DL_DesiredThrottlePosition 1.7E-308;
BA_ "SigType" SG_ 2566906368 DL_ETCMotorPWM 1.7E-308;
BA_ "SigType" SG_ 2566906368 DL_GovPresent 1.7E-308;
BA_ "SigType" SG_ 2566906112 DL_MAPSensorRawVoltage 1.7E-308;
BA_ "SigType" SG_ 2566906112 DL_ManifoldAirPress 1.7E-308;
BA_ "SPN" SG_ 2566906112 DL_BarometricPressure 108;
BA_ "SigType" SG_ 2566906112 DL_BarometricPressure 1.7E-308;
BA_ "SigType" SG_ 2566906112 DL_BaroSensorPresent 1.7E-308;
BA_ "SigType" SG_ 2566905344 DL_OilLifeMonitorEnabled 1.7E-308;
BA_ "SigType" SG_ 2566905344 DL_ChangeOilNow 1.7E-308;
BA_ "SigType" SG_ 2566905344 DL_ChangeOilSoon 1.7E-308;
BA_ "SigType" SG_ 2566905344 DL_OilLifeRemaining 1.7E-308;
BA_ "SigType" SG_ 2566905344 DL_OilLifeRemainingAtLastChange 1.7E-308;
BA_ "SigType" SG_ 2566905344 DL_OilLifeRemainAtChngPriorToLst 1.7E-308;
BA_ "SigType" SG_ 2566905344 DL_EngRunTimeSinceLastOilChg 1.7E-308;
BA_ "SigType" SG_ 2566904064 DL_NoRevLimInLastSec 1.7E-308;
BA_ "SigType" SG_ 2566904064 DL_RevLimitThreshold 1.7E-308;
BA_ "SigType" SG_ 2566904064 DL_GovernorPresent 1.7E-308;
BA_ "SigType" SG_ 2566904064 DL_SlowMode 1.7E-308;
BA_ "SigType" SG_ 2566904064 DL_GovernedEngineSpeed 1.7E-308;
BA_ "SigType" SG_ 2566904064 DL_GovernedVesselSpeed 1.7E-308;
BA_ "SigType" SG_ 2566903808 DL_CanisterPurgeSystemPresent 1.7E-308;
BA_ "SigType" SG_ 2566903808 DL_CCPDutyCycle 1.7E-308;
BA_ "SigType" SG_ 2566903552 DL_FailedDTCTestThisIgnCycle 1.7E-308;
BA_ "SigType" SG_ 2566903552 DL_HistoryDataCorrupted 1.7E-308;
BA_ "SigType" SG_ 2566903552 DL_NumWarmUpCycSinceLastDTCSet 1.7E-308;
BA_ "SigType" SG_ 2566903552 DL_TotalEngineRunTime 1.7E-308;
BA_ "SigType" SG_ 2566903296 DL_FanDriver 1.7E-308;
BA_ "SigType" SG_ 2566903296 DL_DesiredFanPosition 1.7E-308;
BA_ "SigType" SG_ 2566903296 DL_FanDutyCycle 1.7E-308;
BA_ "SigType" SG_ 2566902784 DL_DesiredIdleSpd 1.7E-308;
BA_ "SigType" SG_ 2566902784 DL_VirtualIACPosition 1.7E-308;
BA_ "SigType" SG_ 2566902784 DL_LoadAnticipate1Value 1.7E-308;
BA_ "SigType" SG_ 2566902784 DL_LoadAnticipate2Value 1.7E-308;
BA_ "SigType" SG_ 2566902784 DL_ETCIdleStop 1.7E-308;
BA_ "SigType" SG_ 2566902784 DL_CloseThrottleIdleControlMode 1.7E-308;
BA_ "SigType" SG_ 2566902784 DL_IACControlofRPM 1.7E-308;
BA_ "SigType" SG_ 2566902784 DL_LoadAnticipate1 1.7E-308;
BA_ "SigType" SG_ 2566902784 DL_LoadAnticipate2 1.7E-308;
BA_ "SigType" SG_ 2566902528 DL_FiringMode 1.7E-308;
BA_ "SigType" SG_ 2566902528 DL_KnockMonitoring 1.7E-308;
BA_ "SigType" SG_ 2566902528 DL_KnockPresentInLastSec 1.7E-308;
BA_ "SigType" SG_ 2566902528 DL_FuelDetonationControlMode 1.7E-308;
BA_ "SigType" SG_ 2566902528 DL_OctaneRatingStatus 1.7E-308;
BA_ "SigType" SG_ 2566902528 DL_OctaneUpdate 1.7E-308;
BA_ "SigType" SG_ 2566902528 DL_SparkAdvance 1.7E-308;
BA_ "SigType" SG_ 2566902528 DL_CurrentMaxKnockRetardAllCyl 1.7E-308;
BA_ "SigType" SG_ 2566902528 DL_OctaneRating 1.7E-308;
BA_ "SigType" SG_ 2566902528 DL_CurrentCylWithMaxKnockRetard 1.7E-308;
BA_ "SigType" SG_ 2566902528 DL_CamAngle 1.7E-308;
BA_ "SigType" SG_ 2566901504 DL_CamXSensor 1.7E-308;
BA_ "SigType" SG_ 2566901504 DL_CamXPhaser 1.7E-308;
BA_ "SigType" SG_ 2566901504 DL_CamXAngle 1.7E-308;
BA_ "SigType" SG_ 2566901504 DL_ReferenceCamXAngle 1.7E-308;
BA_ "SigType" SG_ 2566901504 DL_CamXPhaserDutyCycle 1.7E-308;
BA_ "SigType" SG_ 2566901248 DL_CamWSensor 1.7E-308;
BA_ "SigType" SG_ 2566901248 DL_CamWPhaser 1.7E-308;
BA_ "SigType" SG_ 2566901248 DL_CamWAngle 1.7E-308;
BA_ "SigType" SG_ 2566901248 DL_ReferenceCamWAngle 1.7E-308;
BA_ "SigType" SG_ 2566901248 DL_CamWPhaserDutyCycle 1.7E-308;
VAL_ 3221225472 DM_FailureModeIdentifier 0 "Above normal (most severe)" 1 "Below normal (most severe)" 2 "Data erratic" 3 "Voltage above normal" 4 "Voltage below normal" 5 "Current below normal" 6 "Current above normal" 7 "Mechanical system not responding" 8 "Abnormal frequency" 9 "Abnormal update rate" 10 "Abnormal rate of change" 11 "Root cause not known" 12 "Bad intelligent device" 13 "Out of calibration" 14 "Special intstructions" 15 "Above normal (least severe)" 16 "Above normal (moderately severe)" 17 "Below normal (least severe)" 18 "Below normal (moderatels severe)" 19 "Received network data in error" 31 "Not available" ;
VAL_ 2564292857 DM15_Seed 65535 "No Further Key required of Tool" 1 "Use Long Seed or Key" 0 "Seed Complete - send key" ;
VAL_ 2564292857 DM15_Error_Ind_EDC_Parameter 16777215 "No Error Indicator Available" 65540 "Transport NOT completed in time" 65539 "Transport NOT initiated in time" 65538 "NO response in the time allowed" 65537 "Too Many Retries" 65536 "Abort from external" 4103 "Security Error - NOT in Park" 4102 "Security Error - Engine running" 4101 "Security Error NOT in Dev mode" 4100 "Security Error NOT in Diag mode" 4099 "Security Error Invalid Key" 4098 "Security Error Invalid User Lvl" 4097 "Security Error Invalid Password" 4096 "Security Error General" 266 "DATA Error NAME unexpected value" 265 "DATA Error invalid value ranges" 264 "Addressing Error invalid bounds" 263 "Addressing Error wrong memory" 262 "Addressing Error requires trans" 261 "Addressing Error requires erase" 260 "Addressing Error requires erase" 259 "Addressing Error exceeded memory" 258 "Addressing Error Length invalid" 257 "Addressing Error bounds invalid" 256 "Addressing or DATA General Error" 36 "Internal failure preventing req" 35 "PROM did not verify on Write" 34 "FLASH did not verify on Write" 33 "RAM did not verify on Write" 32 "EDC parm not correct for data" 31 "Currently processing request" 23 "Currently processing Gen Req" 22 "Currently processing Boot Req" 19 "Currently processing Status Req" 18 "Currently processing Write Req" 17 "Currently processing Read Req" 16 "Currently processing Erase Req" 2 "Currently processing for another" 1 "Error NOT identified" 0 "No Error" ;
VAL_ 2564292857 DM15_EDCP_Extension 255 "No Error/EDC Parameter Available" 7 "Data in Error Indicator" 6 "Data in Error Indicator" 3 "More, Lower order EDC Parameter" 2 "More, Higher order EDC Parameter" 0 "Completed" ;
VAL_ 2564292857 DM15_Status 7 "Reserved" 6 "Reserved" 5 "Operation Failed" 4 "Operation Completed" 3 "Reserved" 2 "Reserved" 1 "Busy" 0 "Proceed" ;
VAL_ 2564358393 DM14_Pointer_Type 1 "Directed Spatial Addressing" 0 "Direct Memory Addressing" ;
VAL_ 2564358393 DM14_Command 7 "EDCP Generation" 6 "Boot Load" 5 "Operation Failed" 4 "Operation Completed" 3 "Status Request" 2 "Write" 1 "Read" 0 "Erase" ;
VAL_ 2633984602 pHeatedGripEnable 3 "Description for the value '3'" 2 "Error Indicator" 1 "Enabled (Installed)" 0 "Disabled (Not installed)" ;
VAL_ 2633984602 pSideStandStatus 3 "Not Available" 2 "Error Indicator" 1 "Side Stand Up" 0 "Side Stand Down" ;
VAL_ 2633984602 pTetherSwitchStatus 3 "Not Available" 2 "Error" 1 "Tether SW Open (disconnected)" 0 "Tether SW Closed (connected)" ;
VAL_ 2633984602 pLowFuelIndicatorStatus 3 "Not Available" 2 "Error" 1 "Low Fuel Indicator On" 0 "Low Fuel Indicator Off" ;
VAL_ 2633984602 pOperatorNotInOperatingStation 3 "Description for the value '3'" 2 "Error" 1 "Operator Not In OperatorStation" 0 "Operator In OperatorStation" ;
VAL_ 2633984602 pParkBrakeIndicatorStatus 7 "Not Available" 6 "Error Indicator" 5 "Available for future use" 4 "Available for future use" 3 "Park Brake Indicator 2 Hz flash" 2 "Park Brake Indicator 1 Hz flash" 1 "Park Brake Indicator On (Solid)" 0 "Park Brake Indicator Off" ;
VAL_ 2633984602 pADCRequested 3 "Not Available" 2 "Error" 1 "ADC Mode Requested" 0 "ADC Mode not Requested" ;
VAL_ 2633984602 pAWDModeRequested 3 "Not Available" 2 "Error" 1 "AWD Mode Requested" 0 "AWD Mode not Requested" ;
VAL_ 2633984602 pRWDModeRequested 3 "Not Available" 2 "Error" 1 "RWD Mode Requested" 0 "RWD Mode not Requested" ;
VAL_ 2633984602 pTurfModeRequested 3 "Not Available" 2 "Error" 1 "Turf Mode Requested" 0 "Turf Mode not Requested" ;
VAL_ 2633984602 pADCStatus 0 "ADC Actuator Not Engaged" 1 "ADC Actuator Engaged" 2 "Error" 3 "Not available" ;
VAL_ 2633984602 pTreadleNeutralStatus 0 "Treadle Neutral Not Engaged" 1 "Treadle Neutral Engaged" 2 "Error" 3 "Not Available" ;
VAL_ 2633984602 pTreadleReverseStatus 0 "Treadle Reverse Not Engaged" 1 "Treadle Reverse Engaged" 2 "Error" 3 "Not Available" ;
VAL_ 2633984602 pSecurityLightStatus 0 "Off" 1 "On (Solid)" 2 "Error (Flashing)" 3 "Not Available" ;
VAL_ 2633984602 pHighBeamIndicatorStatus 0 "Indicator Off" 1 "Indicator On" 2 "Error (Indicator Flashing)" 3 "Not Available" ;
VAL_ 2633984602 pCruiseControlSetStatus 0 "Cruise Not Set" 1 "Cruise Set" 2 "Error (Lamp Flashing)" 3 "Not Available" ;
VAL_ 2633984602 pSeatBeltIndicatorStatus 0 "Seat_Belt_Indicator_Off" 1 "Seat_Belt_Indicator_On_Solid" 2 "Seat_Belt_Indicator_1Hz" 3 "Seat_Belt_Indicator_2Hz" 4 "Future1" 5 "Future2" 6 "Error" 7 "Not_Available" ;
VAL_ 2566876762 pEngineOilPressureStatus 0 "Not OK; Pressure is too low" 1 "OK; Pressure is above minimum" 2 "Error" 3 "Not Available" ;
VAL_ 2566876762 pHydraulicOilPressureStatus 0 "Not OK; Pressure too low" 1 "OK; Pressure above minimum" 2 "Error" 3 "Not Available" ;
VAL_ 2566876762 pHydraulicOilTempStatus 0 "Not OK; Temp too high" 1 "OK; Temp is below max" 2 "Error" 3 "Not Available" ;
VAL_ 2566876672 pEngineOilPressureStatus 0 "Not OK; Pressure is too low" 1 "OK; Pressure is above minimum" 2 "Error" 3 "Not Available" ;
VAL_ 2566876672 pHydraulicOilPressureStatus 0 "Not OK; Pressure too low" 1 "OK; Pressure above minimum" 2 "Error" 3 "Not Available" ;
VAL_ 2566876672 pHydraulicOilTempStatus 0 "Not OK; Temp too high" 1 "OK; Temp is below max" 2 "Error" 3 "Not Available" ;
VAL_ 2565866755 TransmissionRqstedRange 21024 " R" 20512 " P" 20000 " N" 19488 " L" 18464 " H" ;
VAL_ 2566844675 TwoSpeedAxleSwitch 0 "LowSpeedRange" 1 "HighSpeedRange" 2 "Error" 3 "NotAvailable" ;
VAL_ 2566844675 ParkingBrakeSwitch 0 "NotSet" 1 "Set" 2 "Error" 3 "NotAvailable" ;
VAL_ 2566844675 CruiseCtrlActive 0 "SwitchedOff" 1 "SwitchedOn" 2 "Error" 3 "NotAvailable" ;
VAL_ 2566844675 CruiseCtrlEnableSwitch 0 "Disabled" 1 "Enabled" 2 "Error" 3 "NotAvailable" ;
VAL_ 2566844675 BrakeSwitch 0 "PedalReleased" 1 "PedalDepressed" 2 "Error" 3 "NotAvailable" ;
VAL_ 2566844675 ClutchSwitch 0 "PedalReleased" 1 "PedalDepressed" 2 "Error" 3 "NotAvailable" ;
VAL_ 2566844675 CruiseCtrlSetSwitch 0 "NotSet" 1 "Set" 2 "Error" 3 "NotAvailable" ;
VAL_ 2566844675 CruiseCtrlCoastSwitch 0 "NotCoast" 1 "Coast" 2 "Error" 3 "NotAvailable" ;
VAL_ 2566844675 CruiseCtrlResumeSwitch 0 "NotResume" 1 "Resume" 2 "Error" 3 "NotAvailable" ;
VAL_ 2566844675 CruiseCtrlAccelerateSwitch 0 "NotAccelerate" 1 "Accelerate" 2 "Error" 3 "NotAvailable" ;
VAL_ 2566844675 pOdometerDriveBit 0 "State A" 1 "State B" 2 "Error" 3 "Not Available/Initialize" ;
VAL_ 2566844675 CruiseCtrlPauseSw 0 "Off" 1 "On" 2 "Error" 3 "Take No Action" ;
VAL_ 2566844675 pCruiseEnableStatus 0 "Not enabled." 1 "Enabled but not activated." 2 "Reserved" 14 "Error Indicator" 15 "Not Available" ;
VAL_ 2566878554 pOperationMode 0 "Manned" 3 "Not Available" 2 "Error" 1 "Remote" ;
VAL_ 2566878554 pStartStopCmd 3 "Not Available" 2 "Error" 1 "Button Pressed" 0 "Button Not Pressed" ;
VAL_ 2566844762 TwoSpeedAxleSwitch 0 "LowSpeedRange" 1 "HighSpeedRange" 2 "Error" 3 "NotAvailable" ;
VAL_ 2566844762 ParkingBrakeSwitch 0 "NotSet" 1 "Set" 2 "Error" 3 "NotAvailable" ;
VAL_ 2566844762 CruiseCtrlActive 0 "SwitchedOff" 1 "SwitchedOn" 2 "Error" 3 "NotAvailable" ;
VAL_ 2566844762 CruiseCtrlEnableSwitch 0 "Disabled" 1 "Enabled" 2 "Error" 3 "NotAvailable" ;
VAL_ 2566844762 BrakeSwitch 0 "PedalReleased" 1 "PedalDepressed" 2 "Error" 3 "NotAvailable" ;
VAL_ 2566844762 ClutchSwitch 0 "PedalReleased" 1 "PedalDepressed" 2 "Error" 3 "NotAvailable" ;
VAL_ 2566844762 CruiseCtrlSetSwitch 0 "NotSet" 1 "Set" 2 "Error" 3 "NotAvailable" ;
VAL_ 2566844762 CruiseCtrlCoastSwitch 0 "NotCoast" 1 "Coast" 2 "Error" 3 "NotAvailable" ;
VAL_ 2566844762 CruiseCtrlResumeSwitch 0 "NotResume" 1 "Resume" 2 "Error" 3 "NotAvailable" ;
VAL_ 2566844762 CruiseCtrlAccelerateSwitch 0 "NotAccelerate" 1 "Accelerate" 2 "Error" 3 "NotAvailable" ;
VAL_ 2566844762 pOdometerDriveBit 0 "State A" 1 "State B" 2 "Error" 3 "Not Available/Initialize" ;
VAL_ 2566844762 CruiseCtrlPauseSw 0 "Off" 1 "On" 2 "Error" 3 "Take No Action" ;
VAL_ 2566844762 pCruiseEnableStatus 0 "Not enabled." 1 "Enabled but not activated." 2 "Reserved" 14 "Error Indicator" 15 "Not Available" ;
VAL_ 2365526260 WATT_pFloat_State 3 "Not Available" 2 "Error" 1 "Low Electrolyte Level Detected" 0 "Electrolyte Level Ok" ;
VAL_ 2365526259 WATT_pFloat_State 3 "Not Available" 2 "Error" 1 "Low Electrolyte Level Detected" 0 "Electrolyte Level Ok" ;
VAL_ 2365526516 WATT_pBatteryType 128 "Li-Ion Pack" 70 "AGM Lead Acid 6V" 68 "AGM Lead Acid 12V" 6 "Flooded Lead Acid 6V" 4 "Flooded Lead Acid 12V" ;
VAL_ 2365526516 WATT_pWAKE_State 3 "Not Available" 2 "Error" 1 "Active" 0 "Off" ;
VAL_ 2365526516 WATT_pKEY_State 3 "Not Available" 2 "Error" 1 "On" 0 "Off" ;
VAL_ 2365526516 WATT_pDC_DC_State 7 "Not Available" 6 "Error" 5 "Power, Enabled" 4 "Powered, Disabled" 3 "Reserved" 2 "Reserved" 1 "Reserved" 0 "Off" ;
VAL_ 2365526516 WATT_pBalance_State 15 "Not Available" 14 "Reserved" 13 "Reserved" 12 "Reserved" 11 "Reserved" 10 "Reserved" 9 "Reserved" 8 "Relaxing" 7 "Reserved" 6 "Reserved" 5 "Reserved" 4 "Charging" 3 "Reserved" 2 "Resting" 1 "Driving" 0 "Power Up" ;
VAL_ 2365526772 WATT_pCharger_State 31 "Not Available" 30 "Reserved" 29 "Reserved" 28 "Reserved" 27 "Maintanence Charging" 26 "Equalize,Balance Charging" 25 "Float Charging" 24 "Charge Complete" 23 "Reserved" 22 "Reserved" 21 "Reserved" 20 "Reduced Performance" 19 "Finish Phase" 18 "Absorption Phase" 17 "Bulk Phase" 16 "Recovery Phase" 15 "Reserved" 14 "Reserved" 13 "Reserved" 12 "Reserved" 11 "Reserved" 10 "Reserved" 9 "Reserved" 8 "Reserved" 7 "Reserved" 6 "Internal Fault Shutdown" 5 "Over Temp Shutdown" 4 "Charge Timeout" 3 "Check Battery Shutdown" 2 "Low Voltage Shutdown" 1 "High Voltage Shutdown" 0 "Off" ;
VAL_ 2365526772 WATT_pAC_Status 7 "Not Available" 6 "Error" 5 "220 AC" 4 "220 AC, reduced pwr low Voltage" 3 "110 AC" 2 "110 AC, reduced pwr low Voltage" 1 "AC Present, Voltage Level N/A" 0 "No AC Present" ;
VAL_ 2365526515 WATT_pBatteryType 128 "Li-Ion Pack" 70 "AGM Lead Acid 6V" 68 "AGM Lead Acid 12V" 6 "Flooded Lead Acid 6V" 4 "Flooded Lead Acid 12V" ;
VAL_ 2365526515 WATT_pWAKE_State 3 "Not Available" 2 "Error" 1 "Active" 0 "Off" ;
VAL_ 2365526515 WATT_pKEY_State 3 "Not Available" 2 "Error" 1 "On" 0 "Off" ;
VAL_ 2365526515 WATT_pDC_DC_State 7 "Not Available" 6 "Error" 5 "Power, Enabled" 4 "Powered, Disabled" 3 "Reserved" 2 "Reserved" 1 "Reserved" 0 "Off" ;
VAL_ 2365526515 WATT_pBalance_State 15 "Not Available" 14 "Reserved" 13 "Reserved" 12 "Reserved" 11 "Reserved" 10 "Reserved" 9 "Reserved" 8 "Relaxing" 7 "Reserved" 6 "Reserved" 5 "Reserved" 4 "Charging" 3 "Reserved" 2 "Resting" 1 "Driving" 0 "Power Up" ;
VAL_ 2365526771 WATT_pCharger_State 31 "Not Available" 30 "Reserved" 29 "Reserved" 28 "Reserved" 27 "Maintanence Charging" 26 "Equalize,Balance Charging" 25 "Float Charging" 24 "Charge Complete" 23 "Reserved" 22 "Reserved" 21 "Reserved" 20 "Reduced Performance" 19 "Finish Phase" 18 "Absorption Phase" 17 "Bulk Phase" 16 "Recovery Phase" 15 "Reserved" 14 "Reserved" 13 "Reserved" 12 "Reserved" 11 "Reserved" 10 "Reserved" 9 "Reserved" 8 "Reserved" 7 "Reserved" 6 "Internal Fault Shutdown" 5 "Over Temp Shutdown" 4 "Charge Timeout" 3 "Check Battery Shutdown" 2 "Low Voltage Shutdown" 1 "High Voltage Shutdown" 0 "Off" ;
VAL_ 2365526771 WATT_pAC_Status 7 "Not Available" 6 "Error" 5 "220 AC" 4 "220 AC, reduced pwr low Voltage" 3 "110 AC" 2 "110 AC, reduced pwr low Voltage" 1 "AC Present, Voltage Level N/A" 0 "No AC Present" ;
VAL_ 2298415094 WATT_pPerformance_State 15 "Not Available" 14 "Reserved" 13 "Reserved" 12 "Reserved" 11 "Reserved" 10 "Reserved" 9 "Reserved" 8 "Reserved" 7 "Reserved" 6 "Fault Reaction" 5 "Fault Off" 4 "Enabled" 3 "Energized" 2 "Precharge" 1 "Shutdown" 0 "Initialize" ;
VAL_ 2298415095 WATT_pPerformance_State 15 "Not Available" 14 "Reserved" 13 "Reserved" 12 "Reserved" 11 "Reserved" 10 "Reserved" 9 "Reserved" 8 "Reserved" 7 "Reserved" 6 "Fault Reaction" 5 "Fault Off" 4 "Enabled" 3 "Energized" 2 "Precharge" 1 "Shutdown" 0 "Initialize" ;
VAL_ 2298415090 WATT_pPerformance_State 15 "Not Available" 14 "Reserved" 13 "Reserved" 12 "Reserved" 11 "Reserved" 10 "Reserved" 9 "Reserved" 8 "Reserved" 7 "Reserved" 6 "Fault Reaction" 5 "Fault Off" 4 "Enabled" 3 "Energized" 2 "Precharge" 1 "Shutdown" 0 "Initialize" ;
VAL_ 2298415089 WATT_pPerformance_State 15 "Not Available" 14 "Reserved" 13 "Reserved" 12 "Reserved" 11 "Reserved" 10 "Reserved" 9 "Reserved" 8 "Reserved" 7 "Reserved" 6 "Fault Reaction" 5 "Fault Off" 4 "Enabled" 3 "Energized" 2 "Precharge" 1 "Shutdown" 0 "Initialize" ;
VAL_ 2298415088 WATT_pPerformance_State 15 "Not Available" 14 "Reserved" 13 "Reserved" 12 "Reserved" 11 "Reserved" 10 "Reserved" 9 "Reserved" 8 "Reserved" 7 "Reserved" 6 "Fault Reaction" 5 "Fault Off" 4 "Enabled" 3 "Energized" 2 "Precharge" 1 "Shutdown" 0 "Initialize" ;
VAL_ 2298415087 WATT_pPerformance_State 15 "Not Available" 14 "Reserved" 13 "Reserved" 12 "Reserved" 11 "Reserved" 10 "Reserved" 9 "Reserved" 8 "Reserved" 7 "Reserved" 6 "Fault Reaction" 5 "Fault Off" 4 "Enabled" 3 "Energized" 2 "Precharge" 1 "Shutdown" 0 "Initialize" ;
VAL_ 2566834735 DM_FlashRedStopLamp 3 "Unavailable / Do Not Flash" 2 "Reserved" 1 "Fast Flash (2 Hz, 50% DC)" 0 "Slow Flash (1 Hz, 50% DC)" ;
VAL_ 2566834735 DM_FlashProtectLamp 3 "Unavailable / Do Not Flash" 2 "Reserved" 1 "Fast Flash (2 Hz, 50% DC)" 0 "Slow Flash (1 Hz, 50% DC)" ;
VAL_ 2566834735 DM_FlashMalfuncIndicatorLamp 3 "Unavailable / Do Not Flash" 2 "Reserved" 1 "Fast Flash (2 Hz, 50% DC)" 0 "Slow Flash (1 Hz, 50% DC)" ;
VAL_ 2566834735 DM_FlashAmberWarningLamp 3 "Unavailable / Do Not Flash" 2 "Reserved" 1 "Fast Flash (2 Hz, 50% DC)" 0 "Slow Flash (1 Hz, 50% DC)" ;
VAL_ 2566834735 DM_ProtectLampStatus 0 "Lamp off" 1 "Lamp on" 2 "Reserved" 3 "Not available" ;
VAL_ 2566834735 DM_RedStopLampState 0 "Lamp off" 1 "Lamp on" 2 "Reserved" 3 "Not available" ;
VAL_ 2566834735 DM_AmberWrningLmpStatus 0 "Lamp off" 1 "Lamp on" 2 "Reserved" 3 "Not available" ;
VAL_ 2566834735 DM_MalfuncnIndicatorLampStatus 0 "Lamp off" 1 "Lamp on" 2 "Reserved" 3 "Not available" ;
VAL_ 2566903040 DL_BoostBypassOutputActive 1 "Active" 0 "Inactive" ;
VAL_ 2566903040 DL_CruiseLampOutputActive 1 "Active" 0 "Inactive" ;
VAL_ 2566903040 DL_FuelSelectOutput2Active 1 "Active" 0 "Inactive" ;
VAL_ 2566903040 DL_FuelSelectOutput1Active 1 "Active" 0 "Inactive" ;
VAL_ 2566903040 DL_OemOutput4Active 1 "Active" 0 "Inactive" ;
VAL_ 2566903040 DL_OemOutput3Active 1 "Active" 0 "Inactive" ;
VAL_ 2566903040 DL_OemOutput2Active 1 "Active" 0 "Inactive" ;
VAL_ 2566903040 DL_OemOutput1Active 1 "Active" 0 "Inactive" ;
VAL_ 2566903040 DL_FuelPump2RelayOutputActive 1 "Active" 0 "Inactive" ;
VAL_ 2566903040 DL_IntercoolerOutputActive 1 "Active" 0 "Inactive" ;
VAL_ 2566903040 DL_ClutchSwitchInputActive 1 "Active" 0 "Inactive" ;
VAL_ 2566903040 DL_BrakeSwitchInputActive 1 "Active" 0 "Inactive" ;
VAL_ 2566903040 DL_ReverseSwitchInputActive 1 "Active" 0 "Inactive" ;
VAL_ 2566903040 DL_CrankReqInput 0 "Inactive" 1 "Active" ;
VAL_ 2566903040 DL_LowOilLevelInput 0 "Inactive" 1 "Active" ;
VAL_ 2566903040 DL_LoadAnticipate1Input 0 "Inactive" 1 "Active" ;
VAL_ 2566903040 DL_LoadAnticipate2Input 0 "Inactive" 1 "Active" ;
VAL_ 2566903040 DL_CruiseDecelInputActive 0 "Inactive" 1 "Active" ;
VAL_ 2566903040 DL_CruiseAccelInputActive 0 "Inactive" 1 "Active" ;
VAL_ 2566903040 DL_PowertrainRelayOutput 0 "Inactive" 1 "Active" ;
VAL_ 2566903040 DL_StarterRelayOutput 0 "Inactive" 1 "Active" ;
VAL_ 2566903040 DL_FuelPump1RelayOutput 0 "Inactive" 1 "Active" ;
VAL_ 2566903040 DL_SlowmodeInputActive 0 "Inactive" 1 "Active" ;
VAL_ 2566903040 DL_SlowModeLampOutput 0 "Inactive" 1 "Active" ;
VAL_ 2566903040 DL_GovCruiseSync 0 "Inactive" 1 "Active" ;
VAL_ 2566903040 DL_DiscreteLowOilPressInput 0 "Inactive" 1 "Active" ;
VAL_ 2566903040 DL_MILOutput 0 "Inactive" 1 "Active" ;
VAL_ 2566855680 pFan1DirectionCmd 3 "Description for the value '3'" 2 "Reserved" 1 "Reverse" 0 "Forward" ;
VAL_ 2566886912 pFleetMgmtDefVehState 15 "Not Available" 14 "Error State" 13 "Reserved" 12 "Reserved" 11 "Reserved" 10 "Reserved" 9 "Reserved" 8 "Reserved" 7 "Vehicle Speed Limit 7" 6 "Vehicle Speed Limit 6" 5 "Vehicle Speed Limit 5" 4 "Vehicle Speed Limit 4" 3 "Vehicle Speed Limit 3" 2 "Vehicle Speed Limit 2" 1 "Vehicle Speed Limit 1" 0 "Vehicle Disable Default State" ;
VAL_ 2566886912 pVehEnblDisbl 15 "Not Available" 14 "Error State" 13 "Reserved" 12 "Reserved" 11 "Reserved" 10 "Reserved" 9 "Reserved" 8 "Reserved" 7 "Reserved" 6 "Reserved" 5 "Reserved" 4 "Reserved" 3 "Reserved" 2 "Reserved" 1 "Normal Operation - Veh Disable" 0 "Normal Operation - Veh Enable" ;
VAL_ 2566886912 pUserAuthenticationStatus 15 "Not Available" 14 "Error State" 13 "Reserved" 12 "Reserved" 11 "Reserved" 10 "Reserved" 9 "Reserved" 8 "Reserved" 7 "Reserved" 6 "Reserved" 5 "Reserved" 4 "Reserved" 3 "Reserved" 2 "Reserved" 1 "Normal Operation - ID Reqd" 0 "Normal Operation - No ID Reqd" ;
VAL_ 2566886912 pBoundaryStatus 15 "Not Available" 14 "Error State" 13 "Reserved" 12 "Reserved" 11 "Reserved" 10 "Reserved" 9 "Reserved" 8 "Reserved" 7 "Reserved" 6 "Reserved" 5 "Reserved" 4 "Reserved" 3 "Reserved" 2 "Reserved" 1 "Normal Operation-Outsid Boundary" 0 "Normal Operation-Inside Boundary" ;
VAL_ 2566878227 pEPSSASCalibrated 3 "Not available" 2 "Reserved" 1 "SAS calibrated" 0 "SAS not calibrated" ;
VAL_ 2566878227 pEPSOperationStatus 7 "Not Available" 6 "Reserved" 5 "Error (non dunctional with DM1)" 4 "Not Used" 3 "Not Used" 2 "Limp Home Mode" 1 "Backup Mode" 0 "Fully Functional" ;
VAL_ 2566878227 pEPSOperationMode 16 "Set Position" 5 "Position w/Speed" 4 "Position" 3 "Speed" 2 "Torque Assist" 0 "Off" ;
VAL_ 2566878987 DL22_DynoMode 1 "Inactive" 0 "Active" ;
VAL_ 2566910503 FI4_SeatbeltSw 3 "Not Available" 2 "Error" 1 "True" 0 "False" ;
VAL_ 2566910503 FI4_pSideStandSw 3 "Not Available" 2 "Error" 1 "Inactive" 0 "Active" ;
VAL_ 2566910503 FI4_DrvlnMomentaryRight 3 "Not Available" 2 "Error" 1 "True" 0 "False" ;
VAL_ 2566910503 FI4_DrvlnMomentaryLeft 3 "Not Available" 2 "Error" 1 "True" 0 "False" ;
VAL_ 2566910503 FI4_BrakeLightOutput 0 "Output Active" 1 "Output Inactive" 2 "Error" 3 "Not Available" ;
VAL_ 2566910503 FI4_FogLightInput 0 "Input HIGH" 1 "Input LOW" 2 "Error" 3 "Not Available" ;
VAL_ 2566910503 FI4_HazardLightOutput 0 "Output Active" 1 "Output Inactive" 2 "Error" 3 "Not Available" ;
VAL_ 2566910503 FI4_HazardSWInput 0 "Input HIGH" 1 "Input LOW" 2 "Error" 3 "Not Available" ;
VAL_ 2566910503 FI4_HeatGripDecSW 0 "Active" 1 "Inactive" 2 "Error" 3 "Not Available" ;
VAL_ 2566910503 FI4_HeatGripIncSW 0 "Active" 1 "Inactive" 2 "Error" 3 "Not Available" ;
VAL_ 2566910503 FI4_HighBeamOutput 0 "Output Active" 1 "Output Inactive" 2 "Error" 3 "Not Available" ;
VAL_ 2566910503 FI4_HornInput 0 "Input HIGH" 1 "Input LOW" 2 "Error" 3 "Not Available" ;
VAL_ 2566910503 FI4_HornOutput 0 "Output Active" 1 "Output Inactive" 2 "Error" 3 "Not Available" ;
VAL_ 2566910503 FI4_LeftFogLightOutput 0 "Output Active" 1 "Output Inactive" 2 "Error" 3 "Not Available" ;
VAL_ 2566910503 FI4_LFTurnSignalOutput 0 "Output Active" 1 "Output Inactive" 2 "Error" 3 "Not Available" ;
VAL_ 2566910503 FI4_LockInput 0 "Input HIGH" 1 "Input LOW" 2 "Error" 3 "Not Available" ;
VAL_ 2566910503 FI4_LowBeamOutput 0 "Output Active" 1 "Output Inactive" 2 "Error" 3 "Not Available" ;
VAL_ 2566910503 FI4_LowHighBeamInput 0 "Input HIGH" 1 "Input LOW" 2 "Error" 3 "Not Available" ;
VAL_ 2566910503 FI4_LRTurnSignalOutput 0 "Output Active" 1 "Output Inactive" 2 "Error" 3 "Not Available" ;
VAL_ 2566910503 FI4_pOperatorButton1 0 "Active" 1 "Inactive" 2 "Error" 3 "Not Available" ;
VAL_ 2566910503 FI4_RFTurnSignalOutput 0 "Output Active" 1 "Output Inactive" 2 "Error" 3 "Not Available" ;
VAL_ 2566910503 FI4_RightFogLightOutput 0 "Output Active" 1 "Output Inactive" 2 "Error" 3 "Not Available" ;
VAL_ 2566910503 FI4_RRTurnSignalOutput 0 "Output Active" 1 "Output Inactive" 2 "Error" 3 "Not Available" ;
VAL_ 2566910503 FI4_SecondaryAirValveCmd 0 "Output Active" 1 "Output Inactive" 2 "Error" 3 "Not Available" ;
VAL_ 2566910503 FI4_SecondaryAirValveOut 0 "Output Active" 1 "Output Inactive" 2 "Error" 3 "Not Available" ;
VAL_ 2566910503 FI4_TailLightOutput 0 "Output Active" 1 "Output Inactive" 2 "Error" 3 "Not Available" ;
VAL_ 2566910503 FI4_UnlockInput 0 "Input HIGH" 1 "Input LOW" 2 "Error" 3 "Not Available" ;
VAL_ 2566910503 FI4_WindshieldSWDownInput 0 "Input HIGH" 1 "Input LOW" 2 "Error" 3 "Not Available" ;
VAL_ 2566910503 FI4_WindshieldSWUpInput 0 "Input HIGH" 1 "Input LOW" 2 "Error" 3 "Not Available" ;
VAL_ 2566910503 FI4_pOperatorButton2 0 "Active" 1 "Inactive" 2 "Error" 3 "Not Available" ;
VAL_ 2566910759 FI3_OilPressSwIn 3 "Not Available" 2 "Error" 1 "Input Low" 0 "Input High" ;
VAL_ 2566910759 FI3_BrkSw2In 3 "Not Available" 2 "Error" 1 "Input Low" 0 "Input High" ;
VAL_ 2566910759 FI3_CruiseCtrlResumeOut 3 "Not Available" 2 "Error" 1 "Inactive" 0 "Active" ;
VAL_ 2566910759 FI3_CruiseCtrlResumeIn 3 "Not Available" 2 "Error" 1 "Inactive" 0 "Active" ;
VAL_ 2566910759 FI3_CruiseCtrlCancelIn 3 "Not Available" 2 "Error" 1 "Inactive" 0 "Active" ;
VAL_ 2566910759 FI3_TetherSwStatus 3 "Not Available" 2 "Error" 1 "Inactive" 0 "Active" ;
VAL_ 2566910759 FI3_DriveMode1Input 0 "Active" 1 "Inactive" 2 "Error" 3 "Not Available" ;
VAL_ 2566910759 FI3_DriveMode2Input 0 "Active" 1 "Inactive" 2 "Error" 3 "Not Available" ;
VAL_ 2566910759 FI3_DriveMode3Input 0 "Active" 1 "Inactive" 2 "Error" 3 "Not Available" ;
VAL_ 2566910759 FI3_DriverMode4Input 0 "Active" 1 "Inactive" 2 "Error" 3 "Not Available" ;
VAL_ 2566910759 FI3_DriverMode1Output 0 "Active" 1 "Inactive" 2 "Error" 3 "Not Available" ;
VAL_ 2566910759 FI3_DriverMode2Output 0 "Active" 1 "Inactive" 2 "Error" 3 "Not Available" ;
VAL_ 2566910759 FI3_DriverMode3Output 0 "Active" 1 "Inactive" 2 "Error" 3 "Not Available" ;
VAL_ 2566910759 FI3_DriverMode4Ouput 0 "Active" 1 "Inactive" 2 "Error" 3 "Not Available" ;
VAL_ 2566910759 FI3_PTOModeInput 0 "Active" 1 "Inactive" 2 "Error" 3 "Not Available" ;
VAL_ 2566910759 FI3_PTOModeOutput 0 "Active" 1 "Inactive" 2 "Error" 3 "Not Available" ;
VAL_ 2566910759 FI3_DriversNetEngagement 0 "Engage" 1 "Disengage" 2 "Error" 3 "Unavailable" ;
VAL_ 2566910759 FI3_DriversSeatbeltEngagement 0 "Engage" 1 "Disengage" 2 "Error" 3 "Unavailable" ;
VAL_ 2566910759 FI3_TiltLockInput 0 "Active" 1 "Inactive" 2 "Error" 3 "Not Available" ;
VAL_ 2566910759 FI3_WorkGroupLockInput 0 "Active" 1 "Inactive" 2 "Error" 3 "Not Available" ;
VAL_ 2566910759 FI3_OperatorPresenceInput 0 "Active" 1 "Inactive" 2 "Error" 3 "Not Available" ;
VAL_ 2566910759 FI3_WorkGroupLockOutput 0 "Active" 1 "Inactive" 2 "Error" 3 "Not Available" ;
VAL_ 2566910759 FI3_OperatorPresenceOutput 0 "Active" 1 "Inactive" 2 "Error" 3 "Not Available" ;
VAL_ 2566910759 FI3_FootOnCruiseInput 0 "Active" 1 "Inactive" 2 "Error" 3 "Not Available" ;
VAL_ 2566910759 FI3_CruiseInput 0 "Active" 1 "Inactive" 2 "Error" 3 "Not Available" ;
VAL_ 2566910759 FI3_TredalInput 0 "Active" 1 "Inactive" 2 "Error" 3 "Not Available" ;
VAL_ 2566910759 FI3_CruiseSpeedInput 0 "Active" 1 "Inactive" 2 "Error" 3 "Not Available" ;
VAL_ 2566910759 FI3_FootOnCruiseOutput 0 "Active" 1 "Inactive" 2 "Error" 3 "Not Available" ;
VAL_ 2566910759 FI3_CruiseOutput 0 "Active" 1 "Inactive" 2 "Error" 3 "Not Available" ;
VAL_ 2566910759 FI3_CruiseControltoSetSpeed 0 "Active" 1 "Inactive" 2 "Error" 3 "Not Available" ;
VAL_ 2566910759 FI3_WorkModeInput 0 "Active" 1 "Inactive" 2 "Error" 3 "Not Available" ;
VAL_ 2566910759 FI3_TiltLockOutput 0 "Active" 1 "Inactive" 2 "Error" 3 "Not Available" ;
VAL_ 2566911015 FI2_ThrttlBdyInitLrnValSave 3 "Not Available" 2 "Error" 1 "True" 0 "False" ;
VAL_ 2566911015 FI2_ThrttlBdyInitLearnSuccess 3 "Not Available" 2 "Error" 1 "True" 0 "False" ;
VAL_ 2566911015 FI2_ThrottleLimpHomeOpCondition 0 "Active" 3 "Not Available" 2 "Error" 1 "Inactive" ;
VAL_ 2566911015 FI2_SystemOnInput 3 "Not Available" 2 "Error" 1 "Input Low" 0 "Input High" ;
VAL_ 2566911015 FI2_SftyFuelCutoffCndn 3 "Not Available" 2 "Error" 1 "Inactive" 0 "Active" ;
VAL_ 2566911015 FI2_RvrsblInjCutoffCndn 3 "Not Available" 2 "Error" 1 "Inactive" 0 "Active" ;
VAL_ 2566911015 FI2_PTOEngagementStatus 3 "Not Available" 2 "Error" 1 "Inactive" 0 "Active" ;
VAL_ 2566911015 FI2_ParkBrakeSwitchIn 3 "Not Available" 2 "Error" 1 "Input Low" 0 "Input High" ;
VAL_ 2566911015 FI2_NeutralSwitchIn 3 "Not Available" 2 "Error" 1 "Input Low" 0 "Input High" ;
VAL_ 2566911015 FI2_IrrvrsblInjCutoffCndn 3 "Not Available" 2 "Error" 1 "Inactive" 0 "Active" ;
VAL_ 2566911015 FI2_ETCFncnMonitor 3 "Not Available" 2 "Error" 1 "Inactive" 0 "Active" ;
VAL_ 2566911015 FI2_ADCOutput 0 "Active" 1 "Inactive" 2 "Error" 3 "Not Available" ;
VAL_ 2566911015 FI2_RearDiffLockOutput 0 "Active" 1 "Inactive" 2 "Error" 3 "Not Available" ;
VAL_ 2566911015 FI2_AWDOutput 0 "Active" 1 "Inactive" 2 "Error" 3 "Not Available" ;
VAL_ 2566911015 FI2_BrakeSwitchInput 0 "Input High" 1 "Input Low" 2 "Error" 3 "Not Available" ;
VAL_ 2566911015 FI2_ADCSwitchInput 0 "Input High" 1 "Input Low" 2 "Error" 3 "Not Available" ;
VAL_ 2566911015 FI2_TurfModeInput 0 "Input High" 1 "Input Low" 2 "Error" 3 "Not Available" ;
VAL_ 2566911015 FI2_AWDSwitchInput 0 "Input High" 1 "Input Low" 2 "Error" 3 "Not Available" ;
VAL_ 2566911015 FI2_ReverseSwitchInput 0 "Input High" 1 "Input Low" 2 "Error" 3 "Not Available" ;
VAL_ 2566911015 FI2_ReverseLimitSwitchInput 0 "Input High" 1 "Input Low" 2 "Error" 3 "Not Available" ;
VAL_ 2566911015 FI2_ForwardLimitSwitchInput 0 "Input High" 1 "Input Low" 2 "Error" 3 "Not Available" ;
VAL_ 2566911015 FI2_EngineDirection 0 "Input High" 1 "Input Low" 2 "Error" 3 "Not Available" ;
VAL_ 2566911015 FI2_RevSpeedLimitOverrideInput 0 "Input High" 1 "Input Low" 2 "Error" 3 "Not Available" ;
VAL_ 2566911015 FI2_ReverseOverspeedSignal 0 "Input High" 1 "Input Low" 2 "Error" 3 "Not Available" ;
VAL_ 2566911015 FI2_RightTurnSignalInput 0 "Input High" 1 "Input Low" 2 "Error" 3 "Not Available" ;
VAL_ 2566911015 FI2_LeftTurnSignalInput 0 "Input High" 1 "Input Low" 2 "Error" 3 "Not Available" ;
VAL_ 2566911015 FI2_KickstandSwitchInput 0 "Input High" 1 "Input Low" 2 "Error" 3 "Not Available" ;
VAL_ 2566911015 FI2_ReflashEnableInputSignal 0 "Input High" 1 "Input Low" 2 "Error" 3 "Not Available" ;
VAL_ 2566911015 FI2_TPSLearnInputSignal 0 "Input High" 1 "Input Low" 2 "Error" 3 "Not Available" ;
VAL_ 2566911015 FI2_LowRangeSwitchInput 0 "Active" 1 "Inactive" 2 "Error" 3 "Not Available" ;
VAL_ 2566911015 FI2_ReverseMotorDriveInput 0 "Input High" 1 "Input Low" 2 "Error" 3 "Not Available" ;
VAL_ 2566911271 FI1_FuelPullSolenoidStatus 3 "Not Available" 2 "Error" 1 "Inactive" 0 "Active" ;
VAL_ 2566911271 FI1_ClutchSwitchInput2 3 "Not Available" 2 "Error" 1 "Inactive" 0 "Active" ;
VAL_ 2566911271 FI1_FuelPumpDriverCkt 0 "Active" 1 "Inactive" 2 "Error" 3 "Not Available" ;
VAL_ 2566911271 FI1_RolloverSwitch 0 "Active" 1 "Inactive" 2 "Error" 3 "Not Available" ;
VAL_ 2566911271 FI1_CrankSensorSignal 0 "Present" 1 "Absent" 2 "Error" 3 "Not Available" ;
VAL_ 2566911271 FI1_CamSensorSignal 0 "Present" 1 "Absent" 2 "Error" 3 "Not Available" ;
VAL_ 2566911271 FI1_RPMLimitActive 0 "Active" 1 "Inactive" 2 "Error" 3 "Not Available" ;
VAL_ 2566911271 FI1_IdleSwitch 0 "Active" 1 "Inactive" 2 "Error" 3 "Not Available" ;
VAL_ 2566911271 FI1_CycleSynchro 0 "Sync" 1 "No-Sync" 2 "Error" 3 "Not Available" ;
VAL_ 2566911271 FI1_IdleSpeedControlStatus 0 "Active" 1 "Inactive" 2 "Error" 3 "Not Available" ;
VAL_ 2566911271 FI1_IgnitionSwitchInput 0 "Input High" 1 "Input Low" 2 "Error" 3 "Not Available" ;
VAL_ 2566911271 FI1_RunStopSwitchInput 0 "Input High" 1 "Input Low" 2 "Error" 3 "Not Available" ;
VAL_ 2566911271 FI1_StartSwitchInput 0 "Input High" 1 "Input Low" 2 "Error" 3 "Not Available" ;
VAL_ 2566911271 FI1_ThrottleSafetySwInput 0 "Input High" 1 "Input Low" 2 "Error" 3 "Not Available" ;
VAL_ 2566911271 FI1_FanRelayOutput 0 "Active" 1 "Inactive" 2 "Error" 3 "Not Available" ;
VAL_ 2566911271 FI1_IntercoolerFanOutput 0 "Active" 1 "Inactive" 2 "Error" 3 "Not Available" ;
VAL_ 2566911271 FI1_ReverseAlarmOutput 0 "Active" 1 "Inactive" 2 "Error" 3 "Not Available" ;
VAL_ 2566911271 FI1_MainRelayOutput 0 "Active" 1 "Inactive" 2 "Error" 3 "Not Available" ;
VAL_ 2566911271 FI1_StartSolenoidOutput 0 "Active" 1 "Inactive" 2 "Error" 3 "Not Available" ;
VAL_ 2566911271 FI1_IgnitionRelayOutput 0 "Active" 1 "Inactive" 2 "Error" 3 "Not Available" ;
VAL_ 2566911271 FI1_ChassisRelayOutput 0 "Active" 1 "Inactive" 2 "Error" 3 "Not Available" ;
VAL_ 2566911271 FI1_StarterEnableOutput 0 "Active" 1 "Inactive" 2 "Error" 3 "Not Available" ;
VAL_ 2566911271 FI1_ExhaustValveOutput 0 "Active" 1 "Inactive" 2 "Error" 3 "Not Available" ;
VAL_ 2566911271 FI1_BatteryChargeRelayOutput 0 "Active" 1 "Inactive" 2 "Error" 3 "Not Available" ;
VAL_ 2566911271 FI1_HeaterAccRelay 0 "Active" 1 "Inactive" 2 "Error" 3 "Not Available" ;
VAL_ 2566911271 FI1_ClutchSwitchInput 0 "Input High" 1 "Input Low" 2 "Error" 3 "Not Available" ;
VAL_ 2566911271 FI1_MILLampOutput 0 "Active" 1 "Inactive" 2 "Error" 3 "Not Available" ;
VAL_ 2566911271 FI1_OverTempLampOutput 0 "Active" 1 "Inactive" 2 "Error" 3 "Not Available" ;
VAL_ 2566911271 FI1_KnockDetLampOutput 0 "Active" 1 "Inactive" 2 "Error" 3 "Not Available" ;
VAL_ 2566911271 FI1_ElecOilPumpDrvrCirc 0 "Active" 1 "Inactive" 2 "Error" 3 "Not Available" ;
VAL_ 2566908427 DL17_ABS_Pump_Command 0 "Active" 1 "Inactive" 2 "Error" 3 "NotAvailable" ;
VAL_ 2566908427 DL17_Brake_Sw_Status 0 "Active" 1 "Inactive" 2 "Error" 3 "NotAvailable" ;
VAL_ 2566908427 DL17_ABS_Failsafe_Relay 0 "Active" 1 "Inactive" 2 "Error" 3 "NotAvailable" ;
VAL_ 2566908427 DL17_ABS_Evac_Fill 0 "Success" 1 "Failure" 2 "Error" 3 "NotAvailable" ;
VAL_ 2566908427 DL17_RedBrakeLamp 0 "Active" 1 "Inactive" ;
VAL_ 2566908427 DL17_ABSFaultLamp 0 "Active" 1 "Inactive" ;
VAL_ 2566908427 DL17_TCSDisabledLamp 0 "Active" 1 "Inactive" ;
VAL_ 2566908427 DL17_ESCDisabledLamp 0 "Active" 1 "Inactive" ;
VAL_ 2566908427 DL17_ESCFaultLampFlashing 0 "Active" 1 "Inactive" ;
VAL_ 2566908427 DL17_ESCFaultLampSolid 0 "Active" 1 "Inactive" ;
VAL_ 2566908427 DL17_TorqueRequestedtoECM 0 "Active" 1 "Inactive" ;
VAL_ 2566908427 DL17_TractionCtrlOverrideSwitch 0 "Active" 1 "Inactive" 2 "Reserved" 3 "Don't care" ;
VAL_ 2566907392 DL_O2SensorA1 0 "Absent" 1 "Present" ;
VAL_ 2566907392 DL_O2SensorA1Condition 0 "Lean" 1 "Rich" ;
VAL_ 2566907392 DL_O2SensorA1Status 0 "Inactive" 1 "Active" ;
VAL_ 2566907392 DL_ClosedLoopFuelControl 0 "Inactive" 1 "Active" ;
VAL_ 2566906624 DL_MATSensor 0 "Absent" 1 "Present" ;
VAL_ 2566906368 DL_ETCPresent 0 "False" 1 "True" ;
VAL_ 2566906368 DL_ETCHbridgeCurrentDirection 0 "Closes" 1 "Opens" ;
VAL_ 2566906368 DL_MinPositionLearningPending 0 "False" 1 "True" ;
VAL_ 2566906368 DL_GovPresent 0 "Absent" 1 "Present" ;
VAL_ 2566906112 DL_BaroSensorPresent 0 "False" 1 "True" ;
VAL_ 2566905344 DL_OilLifeMonitorEnabled 0 "False" 1 "True" ;
VAL_ 2566905344 DL_ChangeOilNow 0 "False" 1 "True" ;
VAL_ 2566905344 DL_ChangeOilSoon 0 "False" 1 "True" ;
VAL_ 2566904064 DL_CauseforRPMReduce 1 "False" 0 "True" ;
VAL_ 2566904064 DL_NoRevLimInLastSec 0 "False" 1 "True" ;
VAL_ 2566904064 DL_GovernorPresent 0 "Absent" 1 "Present" ;
VAL_ 2566904064 DL_SlowMode 0 "Inactive" 1 "Active" ;
VAL_ 2566903808 DL_CanisterPurgeSystemPresent 0 "False" 1 "True" ;
VAL_ 2566903552 DL_FailedDTCTestThisIgnCycle 0 "False" 1 "True" ;
VAL_ 2566903552 DL_HistoryDataCorrupted 0 "False" 1 "True" ;
VAL_ 2566903296 DL_FanDriver 0 "Disabled" 1 "Enabled" ;
VAL_ 2566902784 DL_CloseThrottleIdleControlMode 0 "Inactive" 1 "Active" ;
VAL_ 2566902784 DL_IACControlofRPM 0 "Inactive" 1 "Active" ;
VAL_ 2566902784 DL_LoadAnticipate1 0 "Disabled" 1 "Enabled" ;
VAL_ 2566902784 DL_LoadAnticipate2 0 "Disabled" 1 "Enabled" ;
VAL_ 2566902528 DL_FiringMode 0 "Individual" 1 "Paired" ;
VAL_ 2566902528 DL_KnockMonitoring 0 "Inactive" 1 "Active" ;
VAL_ 2566902528 DL_KnockPresentInLastSec 0 "False" 1 "True" ;
VAL_ 2566902528 DL_FuelDetonationControlMode 0 "Inactive" 1 "Active" ;
VAL_ 2566902528 DL_OctaneRatingStatus 0 "Disabled" 1 "Enabled" ;
VAL_ 2566902528 DL_OctaneUpdate 0 "Not in Progress" 1 "In" ;
VAL_ 2566901504 DL_CamXSensor 0 "Absent" 1 "Present" ;
VAL_ 2566901504 DL_CamXPhaser 0 "Absent" 1 "Present" ;
VAL_ 2566901248 DL_CamWSensor 0 "Absent" 1 "Present" ;
VAL_ 2566901248 DL_CamWPhaser 0 "Absent" 1 "Present" ;
